VERSION ""

NS_ :

BS_:

BU_: APIM_CISM FCIMB RACM_RCIM DSP WCM DACMC HUD_ADV TRM_ITRM ACM GWM _delete APIM IPC GENERIC TSTR

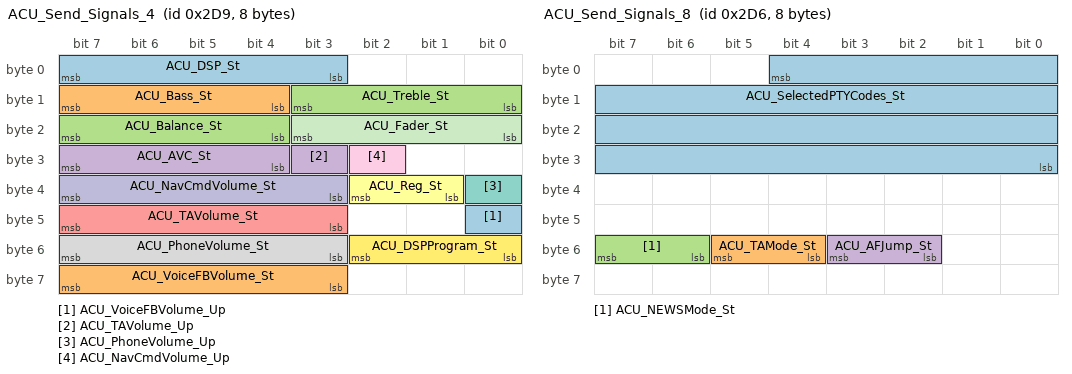
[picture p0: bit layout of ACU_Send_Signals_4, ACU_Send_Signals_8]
BO_ 729 ACU_Send_Signals_4: 8 ACM
 SG_ ACU_VoiceFBVolume_Up : 40|1@0+ (1,0) [0|1] "SED"  HUD_ADV,APIM,IPC
 SG_ ACU_VoiceFBVolume_St : 63|5@0+ (1,0) [0|30] "unitless"  HUD_ADV,WCM,APIM,IPC
 SG_ ACU_Treble_St : 11|4@0+ (1,-7) [-7|8] "unitless"  APIM,IPC
 SG_ ACU_TAVolume_Up : 27|1@0+ (1,0) [0|1] "SED"  HUD_ADV,APIM,IPC
 SG_ ACU_TAVolume_St : 47|5@0+ (1,0) [0|30] "SED"  HUD_ADV,WCM,APIM,IPC
 SG_ ACU_Reg_St : 34|2@0+ (1,0) [0|3] "SED"  APIM
 SG_ ACU_PhoneVolume_Up : 32|1@0+ (1,0) [0|1] "SED"  HUD_ADV,APIM,IPC
 SG_ ACU_PhoneVolume_St : 55|5@0+ (1,0) [0|30] "SED"  HUD_ADV,WCM,APIM,IPC
 SG_ ACU_NavCmdVolume_Up : 26|1@0+ (1,0) [0|1] "SED"  HUD_ADV,APIM,IPC
 SG_ ACU_NavCmdVolume_St : 39|5@0+ (1,0) [0|30] "SED"  HUD_ADV,WCM,APIM,IPC
 SG_ ACU_Fader_St : 19|4@0+ (1,-7) [-7|8] "unitless"  APIM,IPC
 SG_ ACU_DSPProgram_St : 50|3@0+ (1,0) [0|7] "SED"  APIM
 SG_ ACU_DSP_St : 7|5@0+ (1,0) [0|31] "SED"  APIM
 SG_ ACU_Bass_St : 15|4@0+ (1,-7) [-7|8] "unitless"  APIM
 SG_ ACU_Balance_St : 23|4@0+ (1,-7) [-7|8] "unitless"  APIM
 SG_ ACU_AVC_St : 31|4@0+ (1,0) [0|7] "unitless"  APIM

BO_ 727 ACU_Send_Signals_2: 8 ACM
 SG_ ACU_LoadEjectMode_St : 7|4@0+ (1,0) [0|15] "SED"  APIM
 SG_ ACU_LoadEjectDisc_St : 2|3@0+ (1,0) [0|7] "SED"  APIM

BO_ 726 ACU_Send_Signals_8: 8 ACM
 SG_ ACU_SelectedPTYCodes_St : 4|29@0+ (1,0) [0|536870911] "unitless"  APIM
 SG_ ACU_TAMode_St : 53|2@0+ (1,0) [0|3] "SED"  IPC,APIM
 SG_ ACU_NEWSMode_St : 55|2@0+ (1,0) [0|3] "SED"  IPC,APIM
 SG_ ACU_AFJump_St : 51|2@0+ (1,0) [0|3] "SED"  APIM

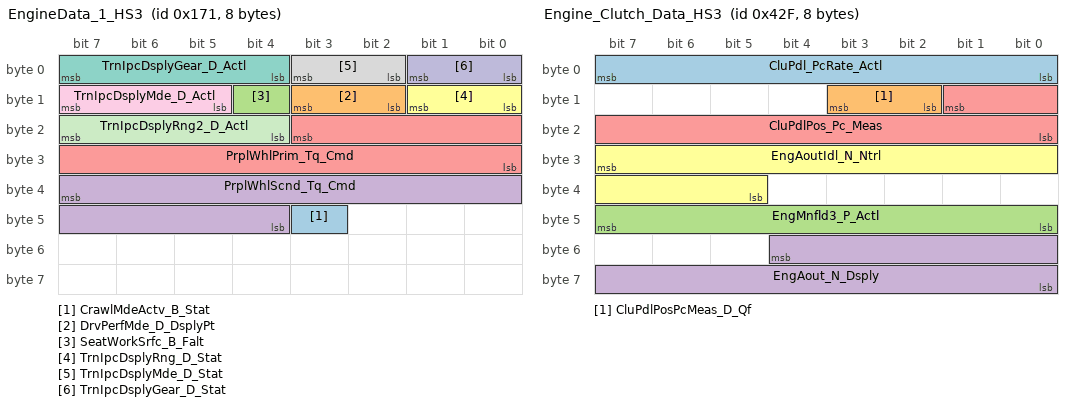
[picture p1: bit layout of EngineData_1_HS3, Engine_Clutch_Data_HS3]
BO_ 369 EngineData_1_HS3: 8 GWM
 SG_ CrawlMdeActv_B_Stat : 43|1@0+ (1,0) [0|1] "SED"  IPC
 SG_ DrvPerfMde_D_DsplyPt : 11|2@0+ (1,0) [0|3] "SED"  APIM_CISM,ACM
 SG_ SeatWorkSrfc_B_Falt : 12|1@0+ (1,0) [0|1] "SED"  IPC
 SG_ PrplWhlScnd_Tq_Cmd : 39|12@0+ (8,-16380) [-16380|16380] "Nm"  GENERIC
 SG_ PrplWhlPrim_Tq_Cmd : 19|12@0+ (8,-16380) [-16380|16380] "Nm"  GENERIC
 SG_ TrnIpcDsplyRng_D_Stat : 9|2@0+ (1,0) [0|3] "SED"  IPC
 SG_ TrnIpcDsplyGear_D_Actl : 7|4@0+ (1,0) [0|15] "SED"  HUD_ADV,APIM_CISM,APIM,IPC
 SG_ TrnIpcDsplyMde_D_Stat : 3|2@0+ (1,0) [0|3] "SED"  HUD_ADV,IPC
 SG_ TrnIpcDsplyMde_D_Actl : 15|3@0+ (1,0) [0|7] "SED"  HUD_ADV,IPC
 SG_ TrnIpcDsplyGear_D_Stat : 1|2@0+ (1,0) [0|3] "SED"  HUD_ADV,IPC
 SG_ TrnIpcDsplyRng2_D_Actl : 23|4@0+ (1,0) [0|15] "SED"  IPC

BO_ 1832 TesterPhysicalResIPC: 8 IPC
 SG_ TesterPhysicalResIPC : 7|64@0+ (1,0) [0|1.84467E+019] "unitless"  TSTR

BO_ 1071 Engine_Clutch_Data_HS3: 8 GWM
 SG_ CluPdl_PcRate_Actl : 7|8@0+ (0.04,-5) [-5|5.2] "%/ms"  IPC
 SG_ CluPdlPosPcMeas_D_Qf : 11|2@0+ (1,0) [0|3] "SED"  IPC
 SG_ EngMnfld3_P_Actl : 47|8@0+ (10,0) [0|2530] "milibar"  GENERIC
 SG_ EngAout_N_Dsply : 52|13@0+ (2,0) [0|16382] "rpm"  IPC
 SG_ CluPdlPos_Pc_Meas : 9|10@0+ (0.1,0) [0|102.3] "%"  IPC
 SG_ EngAoutIdl_N_Ntrl : 31|11@0+ (2,0) [0|4094] "rpm"  GENERIC

BO_ 848 RestraintsData: 8 IPC
 SG_ RILStat : 7|2@0+ (1,0) [0|3] "SED"  GWM

BO_ 891 Active_Noise_Data: 8 DACMC
 SG_ CabnSndAmb2_Db_Actl : 7|8@0+ (1,10) [10|264] "decibel"  GWM

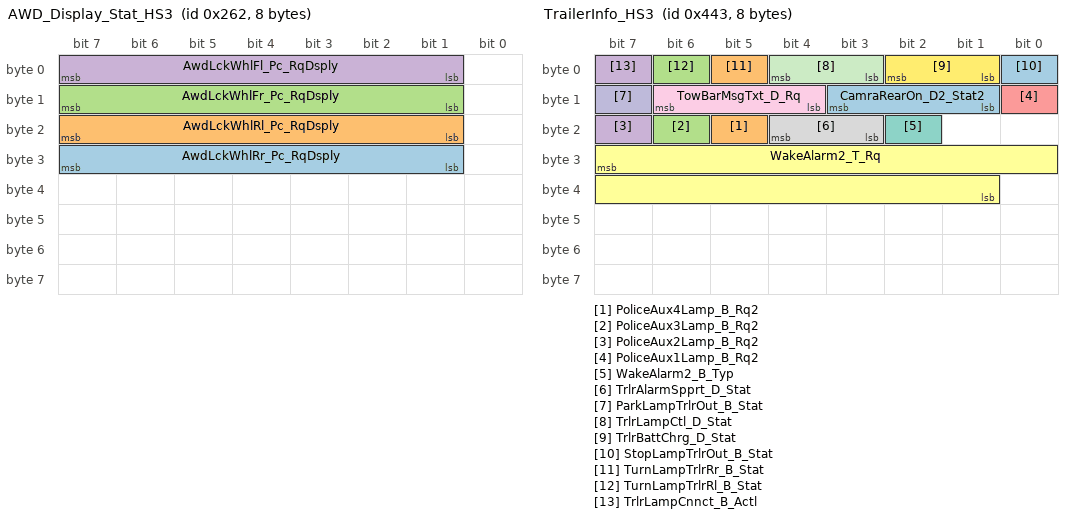
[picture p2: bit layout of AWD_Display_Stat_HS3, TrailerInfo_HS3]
BO_ 610 AWD_Display_Stat_HS3: 8 GWM
 SG_ AwdLckWhlRr_Pc_RqDsply : 31|7@0+ (1,0) [0|127] "percent"  IPC
 SG_ AwdLckWhlRl_Pc_RqDsply : 23|7@0+ (1,0) [0|127] "percent"  IPC
 SG_ AwdLckWhlFr_Pc_RqDsply : 15|7@0+ (1,0) [0|127] "percent"  IPC
 SG_ AwdLckWhlFl_Pc_RqDsply : 7|7@0+ (1,0) [0|127] "percent"  IPC

BO_ 839 FuelOpHeater_Stat_HS3: 8 GWM
 SG_ FohStop_B_Stat : 49|2@0+ (1,0) [0|3] "SED"  IPC
 SG_ FohMsgTxt_D_Rq : 4|3@0+ (1,0) [0|7] "SED"  IPC
 SG_ FohKeyOff_B_Rq : 6|1@0+ (1,0) [0|1] "SED"  IPC
 SG_ FohEnbl_B_Rq : 7|1@0+ (1,0) [0|1] "SED"  IPC
 SG_ FohTAllEnable_B_Stat : 17|2@0+ (1,0) [0|3] "SED"  IPC
 SG_ FohT2Mnte_T_Stat : 55|6@0+ (1,0) [0|63] "minute"  IPC
 SG_ FohT2Hr_T_Stat : 47|5@0+ (1,0) [0|31] "hour"  IPC
 SG_ FohT2Enable_B_Stat : 63|1@0+ (1,0) [0|1] "SED"  IPC
 SG_ FohT1Mnte_T_Stat : 39|6@0+ (1,0) [0|63] "minute"  IPC
 SG_ FohT1Hr_T_Stat : 31|5@0+ (1,0) [0|31] "hour"  IPC
 SG_ FohT1Enable_B_Stat : 0|1@0+ (1,0) [0|1] "SED"  IPC
 SG_ FohStrtMnte_T_Stat : 23|6@0+ (1,0) [0|63] "minute"  IPC
 SG_ FohStrtHr_T_Stat : 15|5@0+ (1,0) [0|31] "hour"  IPC
 SG_ FohStrtEnable_B_Stat : 1|1@0+ (1,0) [0|1] "SED"  IPC
 SG_ FohContOn_B_Stat : 33|2@0+ (1,0) [0|3] "SED"  IPC
 SG_ FohStrtDay_T_Stat : 10|3@0+ (1,0) [0|7] "SED"  IPC
 SG_ FohT2Wednesday_T_Stat : 56|1@0+ (1,0) [0|1] "SED"  IPC
 SG_ FohT2Tuesday_T_Stat : 57|1@0+ (1,0) [0|1] "SED"  IPC
 SG_ FohT2Thursday_T_Stat : 58|1@0+ (1,0) [0|1] "SED"  IPC
 SG_ FohT2Sunday_T_Stat : 59|1@0+ (1,0) [0|1] "SED"  IPC
 SG_ FohT2Saturday_T_Stat : 60|1@0+ (1,0) [0|1] "SED"  IPC
 SG_ FohT2Monday_T_Stat : 61|1@0+ (1,0) [0|1] "SED"  IPC
 SG_ FohT2Friday_T_Stat : 62|1@0+ (1,0) [0|1] "SED"  IPC
 SG_ FohT1Wednesday_T_Stat : 40|1@0+ (1,0) [0|1] "SED"  IPC
 SG_ FohT1Tuesday_T_Stat : 41|1@0+ (1,0) [0|1] "SED"  IPC
 SG_ FohT1Thursday_T_Stat : 42|1@0+ (1,0) [0|1] "SED"  IPC
 SG_ FohT1Sunday_T_Stat : 24|1@0+ (1,0) [0|1] "SED"  IPC
 SG_ FohT1Saturday_T_Stat : 25|1@0+ (1,0) [0|1] "SED"  IPC
 SG_ FohT1Monday_T_Stat : 26|1@0+ (1,0) [0|1] "SED"  IPC
 SG_ FohT1Friday_T_Stat : 5|1@0+ (1,0) [0|1] "SED"  IPC

BO_ 1091 TrailerInfo_HS3: 8 TRM_ITRM
 SG_ CamraRearOn_D2_Stat2 : 11|3@0+ (1,0) [0|7] "SED"  APIM_CISM,GWM,APIM
 SG_ PoliceAux4Lamp_B_Rq2 : 21|1@0+ (1,0) [0|1] "SED"  IPC,GWM
 SG_ PoliceAux3Lamp_B_Rq2 : 22|1@0+ (1,0) [0|1] "SED"  IPC,GWM
 SG_ PoliceAux2Lamp_B_Rq2 : 23|1@0+ (1,0) [0|1] "SED"  IPC,GWM
 SG_ PoliceAux1Lamp_B_Rq2 : 8|1@0+ (1,0) [0|1] "SED"  IPC,GWM
 SG_ WakeAlarm2_T_Rq : 31|15@0+ (1,0) [0|32767] "minute"  GWM
 SG_ WakeAlarm2_B_Typ : 18|1@0+ (1,0) [0|1] "SED"  GWM
 SG_ TrlrAlarmSpprt_D_Stat : 20|2@0+ (1,0) [0|3] "SED"  APIM_CISM,APIM
 SG_ TowBarMsgTxt_D_Rq : 14|3@0+ (1,0) [0|7] "SED"  GWM,IPC
 SG_ ParkLampTrlrOut_B_Stat : 15|1@0+ (1,0) [0|1] "SED"  GWM,IPC
 SG_ TrlrLampCtl_D_Stat : 4|2@0+ (1,0) [0|3] "SED"  GWM,IPC
 SG_ TrlrBattChrg_D_Stat : 2|2@0+ (1,0) [0|3] "SED"  GWM,IPC
 SG_ StopLampTrlrOut_B_Stat : 0|1@0+ (1,0) [0|1] "SED"  GWM,IPC
 SG_ TurnLampTrlrRr_B_Stat : 5|1@0+ (1,0) [0|1] "SED"  GWM,IPC
 SG_ TurnLampTrlrRl_B_Stat : 6|1@0+ (1,0) [0|1] "SED"  GWM,IPC
 SG_ TrlrLampCnnct_B_Actl : 7|1@0+ (1,0) [0|1] "SED"  APIM_CISM,GWM,APIM,IPC

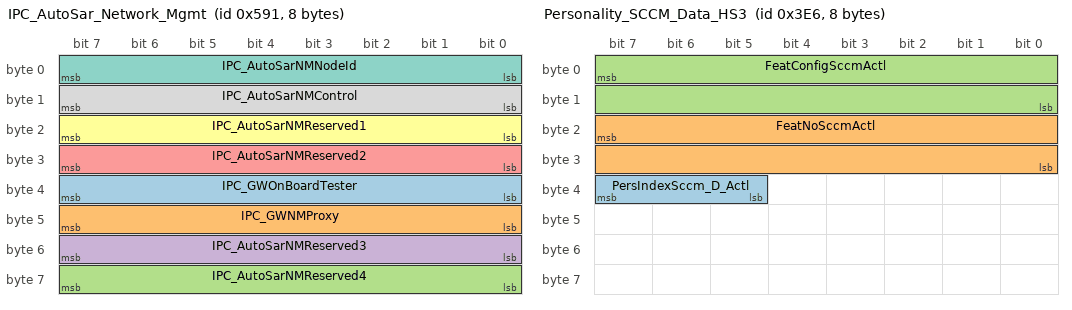
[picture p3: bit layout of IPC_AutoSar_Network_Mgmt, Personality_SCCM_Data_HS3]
BO_ 1425 IPC_AutoSar_Network_Mgmt: 8 IPC
 SG_ IPC_GWOnBoardTester : 39|8@0+ (1,0) [0|255] "unitless"  HUD_ADV,GWM
 SG_ IPC_GWNMProxy : 47|8@0+ (1,0) [0|255] "unitless"  HUD_ADV,GWM
 SG_ IPC_AutoSarNMReserved4 : 63|8@0+ (1,0) [0|255] "unitless"  HUD_ADV,GWM
 SG_ IPC_AutoSarNMReserved3 : 55|8@0+ (1,0) [0|255] "unitless"  HUD_ADV,GWM
 SG_ IPC_AutoSarNMReserved2 : 31|8@0+ (1,0) [0|255] "unitless"  HUD_ADV,GWM
 SG_ IPC_AutoSarNMReserved1 : 23|8@0+ (1,0) [0|255] "unitless"  HUD_ADV,GWM
 SG_ IPC_AutoSarNMNodeId : 7|8@0+ (1,0) [0|255] "unitless"  HUD_ADV,GWM
 SG_ IPC_AutoSarNMControl : 15|8@0+ (1,0) [0|255] "unitless"  HUD_ADV,GWM

BO_ 998 Personality_SCCM_Data_HS3: 8 GWM
 SG_ PersIndexSccm_D_Actl : 39|3@0+ (1,0) [0|7] "SED"  APIM_CISM,APIM,IPC
 SG_ FeatNoSccmActl : 23|16@0+ (1,0) [0|65535] "Number"  APIM_CISM,APIM,IPC
 SG_ FeatConfigSccmActl : 7|16@0+ (1,0) [0|65535] "Undefined"  APIM_CISM,APIM,IPC

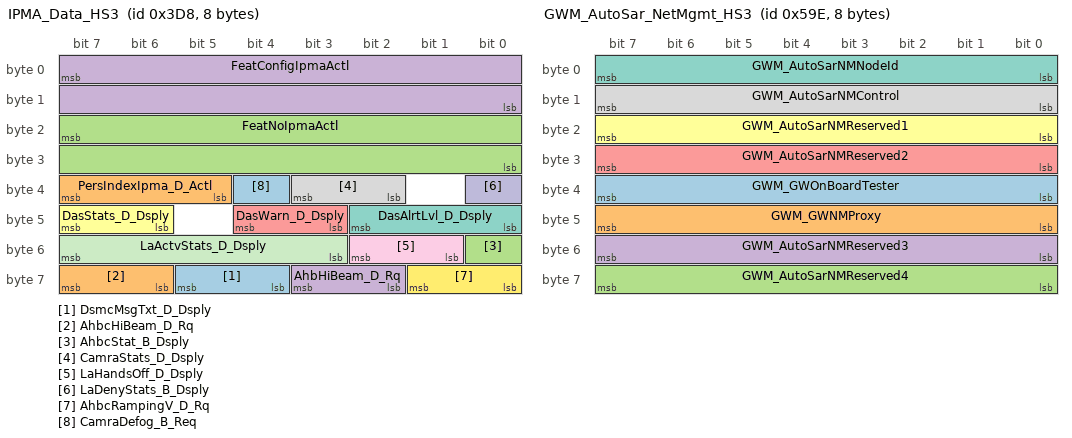
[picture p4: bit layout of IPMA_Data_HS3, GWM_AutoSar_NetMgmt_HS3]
BO_ 984 IPMA_Data_HS3: 8 GWM
 SG_ DsmcMsgTxt_D_Dsply : 61|2@0+ (1,0) [0|3] "SED"  IPC
 SG_ AhbcHiBeam_D_Rq : 63|2@0+ (1,0) [0|3] "SED"  GENERIC
 SG_ AhbcStat_B_Dsply : 48|1@0+ (1,0) [0|1] "SED"  IPC
 SG_ AhbHiBeam_D_Rq : 59|2@0+ (1,0) [0|3] "SED"  GENERIC
 SG_ DasWarn_D_Dsply : 44|2@0+ (1,0) [0|3] "SED"  IPC
 SG_ DasStats_D_Dsply : 47|2@0+ (1,0) [0|3] "SED"  IPC
 SG_ DasAlrtLvl_D_Dsply : 42|3@0+ (1,0) [0|7] "SED"  IPC
 SG_ CamraStats_D_Dsply : 35|2@0+ (1,0) [0|3] "SED"  IPC
 SG_ LaHandsOff_D_Dsply : 50|2@0+ (1,0) [0|3] "SED"  HUD_ADV,IPC
 SG_ LaDenyStats_B_Dsply : 32|1@0+ (1,0) [0|1] "SED"  IPC
 SG_ LaActvStats_D_Dsply : 55|5@0+ (1,0) [0|31] "SED"  APIM_CISM,HUD_ADV,IPC
 SG_ AhbcRampingV_D_Rq : 57|2@0+ (1,0) [0|3] "SED"  GENERIC
 SG_ CamraDefog_B_Req : 36|1@0+ (1,0) [0|1] "SED"  IPC
 SG_ PersIndexIpma_D_Actl : 39|3@0+ (1,0) [0|7] "SED"  APIM_CISM,HUD_ADV,APIM,IPC
 SG_ FeatNoIpmaActl : 23|16@0+ (1,0) [0|65535] "Number"  APIM_CISM,HUD_ADV,APIM,IPC
 SG_ FeatConfigIpmaActl : 7|16@0+ (1,0) [0|65535] "Undefined"  APIM_CISM,HUD_ADV,APIM,IPC

BO_ 1072 Cluster_Info1: 8 IPC
 SG_ PtDrvMde_D_Rq : 61|4@0+ (1,0) [0|15] "SED"  GWM
 SG_ DrvSlipCtlMde_D_Rq : 33|2@0+ (1,0) [0|3] "SED"  GWM
 SG_ EngIdlShutDown_B_RqDrv : 3|1@0+ (1,0) [0|1] "SED"  GWM
 SG_ DrvPerfMde_D_Rq : 49|2@0+ (1,0) [0|3] "SED"  GWM
 SG_ HaDsplyCpblty_B_Stat : 42|1@0+ (1,0) [0|1] "SED"  GWM
 SG_ HsaMde_D_Rq : 54|2@0+ (1,0) [0|3] "SED"  GWM
 SG_ StopStrtDrvMde_D_RqMnu : 47|2@0+ (1,0) [0|3] "SED"  GWM
 SG_ NtrlTowMdeEnbl_B_RqDrv : 1|1@0+ (1,0) [0|1] "SED"  GWM
 SG_ LscmbbStat_B_Actl : 2|1@0+ (1,0) [0|1] "SED"  GWM
 SG_ BulbChkActv_B_Stat : 55|1@0+ (1,0) [0|1] "SED"  GWM
 SG_ ParkDetect_Stat : 52|1@0+ (1,0) [0|1] "SED"  HUD_ADV,GWM
 SG_ ReducedGuard_D_Rq : 51|2@0+ (1,0) [0|3] "SED"  GWM
 SG_ FrostWarn_D_Stat : 45|2@0+ (1,0) [0|3] "SED"  GWM
 SG_ TrlrBrkMde_D_Rq : 57|1@0+ (1,0) [0|1] "SED"  TRM_ITRM,GWM
 SG_ TRLR_SWAY_CONFIG_CMD : 56|1@0+ (1,0) [0|1] "SED"  GWM
 SG_ TRAILER_BRAKE_CONFIG : 37|1@0+ (1,0) [0|1] "SED"  TRM_ITRM,GWM
 SG_ Power_Liftgate_Mode_Cmd : 39|1@0+ (1,0) [0|1] "SED"  GWM
 SG_ AccEnbl_B_RqDrv : 35|1@0+ (1,0) [0|1] "SED"  HUD_ADV,GWM
 SG_ OdometerMasterValue : 15|24@0+ (1,0) [0|16777214] "km"  APIM,APIM_CISM,GWM
 SG_ EngOilLife_B_RqReset : 43|1@0+ (1,0) [0|1] "SED"  GWM
 SG_ MetricActvTe_B_Actl : 38|1@0+ (1,0) [0|1] "SED"  GWM
 SG_ AccDeny_B_RqIpc : 7|1@0+ (1,0) [0|1] "SED"  HUD_ADV,GWM
 SG_ ePRNDL_MODE : 0|1@0+ (1,0) [0|1] "SED"  GWM
 SG_ PrkLckCtlEnbl_D_RqIpc : 63|2@0+ (1,0) [0|3] "SED"  GWM
 SG_ DrvSlipCtlMde_B_Rq2 : 34|1@0+ (1,0) [0|1] "SED"  GWM
 SG_ Fda_B_Stat : 36|1@0+ (1,0) [0|1] "SED"  GWM
 SG_ MetricActv_B_Actl : 6|1@0+ (1,0) [0|1] "SED"  APIM_CISM,HUD_ADV,APIM,GWM
 SG_ KeyTypeChngMykey_D_Rq : 41|2@0+ (1,0) [0|3] "SED"  GWM
 SG_ ManRgen_D_Rq : 5|2@0+ (1,0) [0|3] "SED"  GWM

BO_ 395 HeadUpDisplayReq: 8 IPC
 SG_ SelDrvMdeCnfm_D_Stat : 35|2@0+ (1,0) [0|3] "SED"  GWM
 SG_ HudShifPoint_N_Rq : 29|6@0+ (100,2000) [2000|8300] "rpm"  GWM
 SG_ HudMde_D_Rq : 38|3@0+ (1,0) [0|7] "SED"  GWM
 SG_ HudLedMde_D_Rq : 31|2@0+ (1,0) [0|3] "SED"  GWM
 SG_ HudLedIntns_Pc_Rq : 22|7@0+ (1,0) [0|127] "percent"  GWM
 SG_ HudLed9On_B_Rq : 15|1@0+ (1,0) [0|1] "SED"  GWM
 SG_ HudLed8On_B_Rq : 0|1@0+ (1,0) [0|1] "SED"  GWM
 SG_ HudLed7On_B_Rq : 1|1@0+ (1,0) [0|1] "SED"  GWM
 SG_ HudLed6On_B_Rq : 2|1@0+ (1,0) [0|1] "SED"  GWM
 SG_ HudLed5On_B_Rq : 3|1@0+ (1,0) [0|1] "SED"  GWM
 SG_ HudLed4On_B_Rq : 4|1@0+ (1,0) [0|1] "SED"  GWM
 SG_ HudLed3On_B_Rq : 5|1@0+ (1,0) [0|1] "SED"  GWM
 SG_ HudLed2On_B_Rq : 6|1@0+ (1,0) [0|1] "SED"  GWM
 SG_ HudLed1On_B_Rq : 7|1@0+ (1,0) [0|1] "SED"  GWM
 SG_ HudLed18On_B_Rq : 39|1@0+ (1,0) [0|1] "SED"  GWM
 SG_ HudLed17On_B_Rq : 23|1@0+ (1,0) [0|1] "SED"  GWM
 SG_ HudLed16On_B_Rq : 8|1@0+ (1,0) [0|1] "SED"  GWM
 SG_ HudLed15On_B_Rq : 9|1@0+ (1,0) [0|1] "SED"  GWM
 SG_ HudLed14On_B_Rq : 10|1@0+ (1,0) [0|1] "SED"  GWM
 SG_ HudLed13On_B_Rq : 11|1@0+ (1,0) [0|1] "SED"  GWM
 SG_ HudLed12On_B_Rq : 12|1@0+ (1,0) [0|1] "SED"  GWM
 SG_ HudLed11On_B_Rq : 13|1@0+ (1,0) [0|1] "SED"  GWM
 SG_ HudLed10On_B_Rq : 14|1@0+ (1,0) [0|1] "SED"  GWM

BO_ 1438 GWM_AutoSar_NetMgmt_HS3: 8 GWM
 SG_ GWM_GWOnBoardTester : 39|8@0+ (1,0) [0|255] "unitless"  APIM_CISM,RACM_RCIM,HUD_ADV,TRM_ITRM,WCM,IPC,DSP,APIM,ACM
 SG_ GWM_GWNMProxy : 47|8@0+ (1,0) [0|255] "unitless"  APIM_CISM,RACM_RCIM,HUD_ADV,TRM_ITRM,WCM,IPC,DSP,APIM,ACM
 SG_ GWM_AutoSarNMReserved4 : 63|8@0+ (1,0) [0|255] "unitless"  APIM_CISM,RACM_RCIM,HUD_ADV,TRM_ITRM,WCM,IPC,DSP,APIM,ACM
 SG_ GWM_AutoSarNMReserved3 : 55|8@0+ (1,0) [0|255] "unitless"  APIM_CISM,RACM_RCIM,HUD_ADV,TRM_ITRM,WCM,IPC,DSP,APIM,ACM
 SG_ GWM_AutoSarNMReserved2 : 31|8@0+ (1,0) [0|255] "unitless"  APIM_CISM,RACM_RCIM,HUD_ADV,TRM_ITRM,WCM,IPC,DSP,APIM,ACM
 SG_ GWM_AutoSarNMReserved1 : 23|8@0+ (1,0) [0|255] "unitless"  APIM_CISM,RACM_RCIM,HUD_ADV,TRM_ITRM,WCM,IPC,DSP,APIM,ACM
 SG_ GWM_AutoSarNMNodeId : 7|8@0+ (1,0) [0|255] "unitless"  APIM_CISM,RACM_RCIM,HUD_ADV,TRM_ITRM,WCM,IPC,DSP,APIM,ACM
 SG_ GWM_AutoSarNMControl : 15|8@0+ (1,0) [0|255] "unitless"  APIM_CISM,RACM_RCIM,HUD_ADV,TRM_ITRM,WCM,IPC,DSP,APIM,ACM

BO_ 76 RCMStatusMessage_HS3: 8 GWM
 SG_ RstrnPsngrOn_D_Stat : 39|4@0+ (1,0) [0|15] "SED"  IPC
 SG_ FirstRowBuckle_No_Cs : 47|8@0+ (1,0) [0|255] "unitless"  GENERIC
 SG_ RCMStatusMsg2_No_Cnt : 35|4@0+ (1,0) [0|15] "Unitless"  GENERIC
 SG_ PsngrFmidDetct_D_Actl : 26|2@0+ (1,0) [0|3] "SED"  APIM_CISM,APIM,IPC
 SG_ FirstRowBuckleMid : 28|2@0+ (1,0) [0|3] "SED"  APIM_CISM,APIM,IPC
 SG_ ThirdRowBucklePsngr : 17|2@0+ (1,0) [0|3] "SED"  APIM_CISM,APIM,IPC
 SG_ ThirdRowBuckleMid : 19|2@0+ (1,0) [0|3] "SED"  APIM_CISM,APIM,IPC
 SG_ ThirdRowBuckleDriver : 21|2@0+ (1,0) [0|3] "SED"  APIM_CISM,APIM,IPC
 SG_ SecondRowBucklePsngr : 23|2@0+ (1,0) [0|3] "SED"  APIM_CISM,APIM,IPC
 SG_ SecondRowBuckleMid : 9|2@0+ (1,0) [0|3] "SED"  APIM_CISM,APIM,IPC
 SG_ SecondRowBuckleDriver : 11|2@0+ (1,0) [0|3] "SED"  APIM_CISM,APIM,IPC
 SG_ FirstRowBuckleDriver : 15|2@0+ (1,0) [0|3] "SED"  APIM_CISM,APIM,IPC
 SG_ RILReq : 7|2@0+ (1,0) [0|3] "SED"  IPC
 SG_ FirstRowBucklePsngr : 13|2@0+ (1,0) [0|3] "SED"  APIM_CISM,APIM,IPC
 SG_ RstrnImpactEvntStatus : 3|3@0+ (1,0) [0|7] "SED"  APIM_CISM,APIM,HUD_ADV
 SG_ PsngrFrntDetct_D_Actl : 5|2@0+ (1,0) [0|3] "SED"  APIM_CISM,APIM,IPC
 SG_ PassRstrnInd_Req : 31|2@0+ (1,0) [0|3] "SED"  FCIMB
 SG_ EDRTriggerEvntSync : 29|1@0+ (1,0) [0|1] "SED"  APIM,APIM_CISM,IPC

BO_ 1034 GGCC_Config_Mgmt_ID_1_HS3: 8 GWM
 SG_ VehicleGGCCData : 7|64@0+ (1,0) [0|1.84467E+019] "mixed"  HUD_ADV,APIM_CISM,TRM_ITRM,APIM,ACM,IPC

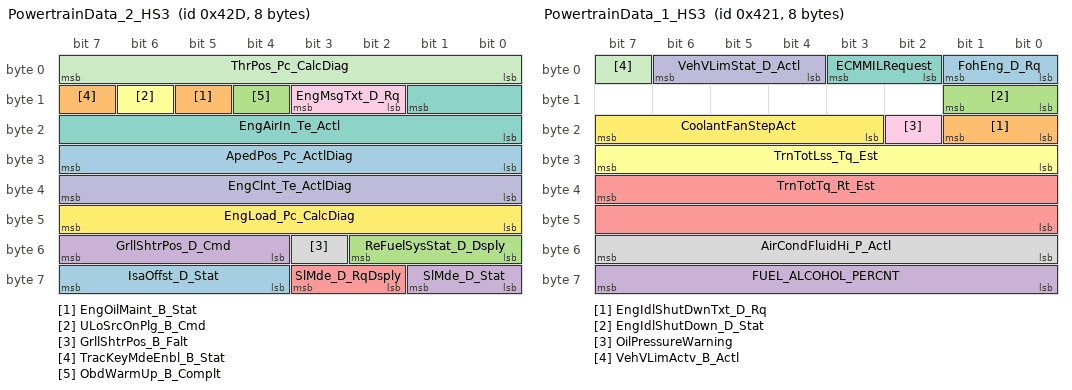
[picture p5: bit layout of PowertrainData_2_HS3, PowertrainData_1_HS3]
BO_ 1069 PowertrainData_2_HS3: 8 GWM
 SG_ IsaOffst_D_Stat : 63|4@0+ (1,0) [0|15] "SED"  HUD_ADV,IPC
 SG_ EngOilMaint_B_Stat : 13|1@0+ (1,0) [0|1] "SED"  GENERIC
 SG_ ReFuelSysStat_D_Dsply : 50|3@0+ (1,0) [0|7] "SED"  IPC
 SG_ SlMde_D_Stat : 57|2@0+ (1,0) [0|3] "SED"  HUD_ADV,IPC
 SG_ SlMde_D_RqDsply : 59|2@0+ (1,0) [0|3] "SED"  APIM_CISM,HUD_ADV,APIM,IPC
 SG_ ULoSrcOnPlg_B_Cmd : 14|1@0+ (1,0) [0|1] "SED"  IPC
 SG_ EngAirIn_Te_Actl : 9|10@0+ (0.25,-128) [-128|127.25] "degC"  IPC
 SG_ GrllShtrPos_B_Falt : 51|1@0+ (1,0) [0|1] "SED"  IPC
 SG_ EngMsgTxt_D_Rq : 11|2@0+ (1,0) [0|3] "SED"  IPC
 SG_ EngClnt_Te_ActlDiag : 39|8@0+ (1,-40) [-40|215] "degC"  IPC
 SG_ ThrPos_Pc_CalcDiag : 7|8@0+ (0.392157,0) [0|100.000035] "%"  IPC
 SG_ EngLoad_Pc_CalcDiag : 47|8@0+ (0.392157,0) [0|100.000035] "%"  IPC
 SG_ ApedPos_Pc_ActlDiag : 31|8@0+ (0.392157,0) [0|100.000035] "%"  IPC
 SG_ TracKeyMdeEnbl_B_Stat : 15|1@0+ (1,0) [0|1] "SED"  IPC
 SG_ ObdWarmUp_B_Complt : 12|1@0+ (1,0) [0|1] "SED" Vector__XXX
 SG_ GrllShtrPos_D_Cmd : 55|4@0+ (1,0) [0|15] "SED"  IPC

BO_ 1057 PowertrainData_1_HS3: 8 GWM
 SG_ FohEng_D_Rq : 1|2@0+ (1,0) [0|3] "SED"  IPC
 SG_ EngIdlShutDwnTxt_D_Rq : 17|2@0+ (1,0) [0|3] "SED"  IPC
 SG_ EngIdlShutDown_D_Stat : 9|2@0+ (1,0) [0|3] "SED"  IPC
 SG_ FUEL_ALCOHOL_PERCNT : 63|8@0+ (0.393700787,0) [0|99.999899898] "Percent"  IPC
 SG_ TrnTotTq_Rt_Est : 39|16@0+ (0.001,0) [0|65.533] "Unitless"  IPC
 SG_ TrnTotLss_Tq_Est : 31|8@0+ (0.5,0) [0|126.5] "Nm"  IPC
 SG_ ECMMILRequest : 3|2@0+ (1,0) [0|3] "SED"  IPC
 SG_ AirCondFluidHi_P_Actl : 55|8@0+ (0.125,0) [0|31.625] "bar"  IPC
 SG_ OilPressureWarning : 18|1@0+ (1,0) [0|1] "SED"  IPC
 SG_ VehVLimStat_D_Actl : 6|3@0+ (1,0) [0|7] "SED"  IPC
 SG_ VehVLimActv_B_Actl : 7|1@0+ (1,0) [0|1] "SED"  IPC
 SG_ CoolantFanStepAct : 23|5@0+ (1,0) [0|31] "Steps"  IPC

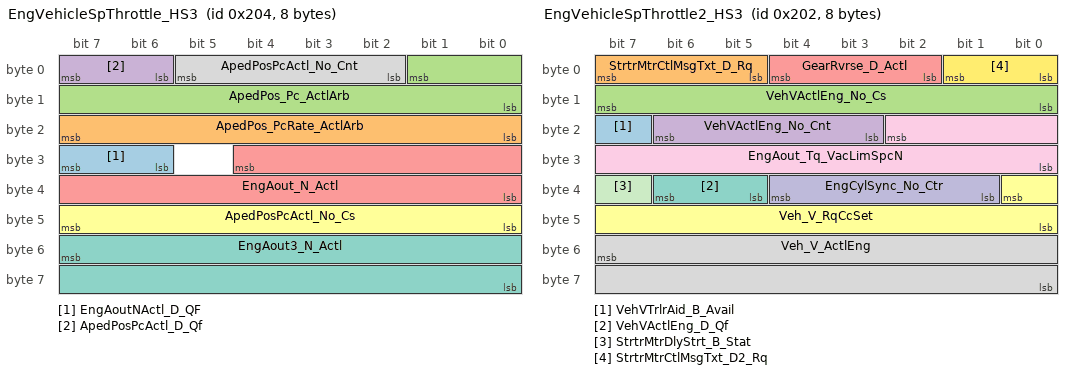
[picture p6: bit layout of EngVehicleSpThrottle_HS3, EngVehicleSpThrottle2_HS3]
BO_ 516 EngVehicleSpThrottle_HS3: 8 GWM
 SG_ EngAoutNActl_D_QF : 31|2@0+ (1,0) [0|3] "SED"  GENERIC
 SG_ ApedPos_PcRate_ActlArb : 23|8@0+ (0.04,-5) [-5|5.12] "%/ms"  APIM_CISM,ACM
 SG_ ApedPos_Pc_ActlArb : 1|10@0+ (0.1,0) [0|102.3] "%"  APIM,APIM_CISM,DACMC,ACM
 SG_ ApedPosPcActl_D_Qf : 7|2@0+ (1,0) [0|3] "SED"  APIM_CISM,DACMC,ACM
 SG_ EngAout_N_Actl : 28|13@0+ (2,0) [0|16382] "rpm"  HUD_ADV,APIM,APIM_CISM,ACM,DACMC,DSP,IPC
 SG_ ApedPosPcActl_No_Cs : 47|8@0+ (1,0) [0|255] "Unitless"  GENERIC
 SG_ EngAout3_N_Actl : 55|16@0+ (0.25,0) [0|16383.5] "RPM"  GENERIC
 SG_ ApedPosPcActl_No_Cnt : 5|4@0+ (1,0) [0|15] "Unitless"  GENERIC

BO_ 514 EngVehicleSpThrottle2_HS3: 8 GWM
 SG_ VehVTrlrAid_B_Avail : 23|1@0+ (1,0) [0|1] "SED"  GENERIC
 SG_ StrtrMtrCtlMsgTxt_D_Rq : 7|3@0+ (1,0) [0|7] "SED"  IPC
 SG_ VehVActlEng_No_Cs : 15|8@0+ (1,0) [0|255] "Unitless"  GENERIC
 SG_ VehVActlEng_No_Cnt : 22|4@0+ (1,0) [0|15] "Unitless"  GENERIC
 SG_ GearRvrse_D_Actl : 4|3@0+ (1,0) [0|7] "SED"  HUD_ADV,APIM_CISM,APIM,IPC
 SG_ Veh_V_RqCcSet : 32|9@0+ (0.5,0) [0|255.5] "kph"  IPC
 SG_ VehVActlEng_D_Qf : 38|2@0+ (1,0) [0|3] "SED"  WCM,APIM,APIM_CISM,DSP,ACM,IPC
 SG_ Veh_V_ActlEng : 55|16@0+ (0.01,0) [0|655.35] "kph"  WCM,APIM,APIM_CISM,TRM_ITRM,DSP,ACM,IPC
 SG_ EngAout_Tq_VacLimSpcN : 18|11@0+ (1,-500) [-500|1547] "Nm"  GENERIC
 SG_ EngCylSync_No_Ctr : 36|4@0+ (1,0) [0|15] "unitless"  GENERIC
 SG_ StrtrMtrDlyStrt_B_Stat : 39|1@0+ (1,0) [0|1] "SED"  GENERIC
 SG_ StrtrMtrCtlMsgTxt_D2_Rq : 1|2@0+ (1,0) [0|3] "SED"  IPC

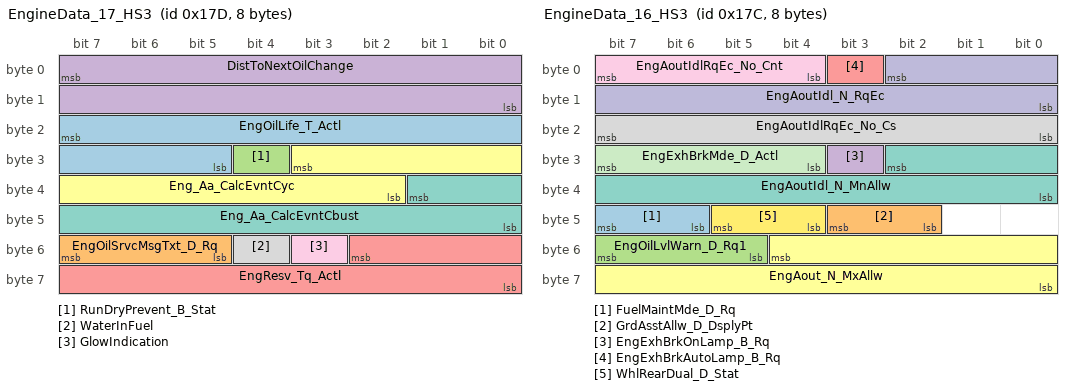
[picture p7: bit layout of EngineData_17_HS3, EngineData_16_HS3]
BO_ 381 EngineData_17_HS3: 8 GWM
 SG_ EngOilLife_T_Actl : 23|11@0+ (1,0) [0|2047] "days"  IPC
 SG_ EngOilSrvcMsgTxt_D_Rq : 55|3@0+ (1,0) [0|7] "SED"  IPC
 SG_ RunDryPrevent_B_Stat : 28|1@0+ (1,0) [0|1] "SED"  IPC
 SG_ DistToNextOilChange : 7|16@0+ (1,0) [0|65535] "unitless"  IPC
 SG_ EngResv_Tq_Actl : 50|11@0+ (1,-500) [-500|1547] "Nm"  IPC
 SG_ Eng_Aa_CalcEvntCyc : 27|10@0+ (0.05,-25.6) [-25.6|25.55] "rpm/ms"  IPC
 SG_ Eng_Aa_CalcEvntCbust : 33|10@0+ (0.05,-25.6) [-25.6|25.55] "rpm/ms"  IPC
 SG_ WaterInFuel : 52|1@0+ (1,0) [0|1] "SED"  IPC
 SG_ GlowIndication : 51|1@0+ (1,0) [0|1] "SED"  IPC

BO_ 380 EngineData_16_HS3: 8 GWM
 SG_ FuelMaintMde_D_Rq : 47|2@0+ (1,0) [0|3] "SED"  GENERIC
 SG_ GrdAsstAllw_D_DsplyPt : 43|2@0+ (1,0) [0|3] "SED"  IPC
 SG_ EngOilLvlWarn_D_Rq1 : 55|3@0+ (1,0) [0|7] "SED"  IPC
 SG_ EngExhBrkOnLamp_B_Rq : 27|1@0+ (1,0) [0|1] "SED"  IPC
 SG_ EngExhBrkAutoLamp_B_Rq : 3|1@0+ (1,0) [0|1] "SED"  IPC
 SG_ EngAout_N_MxAllw : 52|13@0+ (2,0) [0|16382] "rpm"  IPC
 SG_ EngAoutIdl_N_MnAllw : 26|11@0+ (2,0) [0|4094] "rpm"  IPC
 SG_ EngAoutIdlRqEc_No_Cs : 23|8@0+ (1,0) [0|255] "Unitless"  GENERIC
 SG_ EngAoutIdlRqEc_No_Cnt : 7|4@0+ (1,0) [0|15] "Unitless"  GENERIC
 SG_ EngAoutIdl_N_RqEc : 2|11@0+ (2,0) [0|4094] "rpm"  IPC
 SG_ EngExhBrkMde_D_Actl : 31|4@0+ (1,0) [0|15] "SED"  IPC
 SG_ WhlRearDual_D_Stat : 45|2@0+ (1,0) [0|3] "SED"  GENERIC

BO_ 377 EngineData_7_HS3: 8 GWM
 SG_ TrnManShif_D_IndDrv : 7|3@0+ (1,0) [0|7] "Unitless"  HUD_ADV,IPC
 SG_ HvacAirFullOut_B_Rq : 23|1@0+ (1,0) [0|1] "SED"  GENERIC
 SG_ EngFuelCutFull_B_Inhbt : 22|1@0+ (1,0) [0|1] "SED"  IPC
 SG_ EngDecelFuelCut_B_Allw : 21|1@0+ (1,0) [0|1] "SED"  IPC
 SG_ EngAout_Tq_Actl : 2|11@0+ (1,-500) [-500|1547] "Nm"  APIM_CISM,APIM,ACM
 SG_ TrnManShifGear_D_IndDrv : 54|3@0+ (1,0) [0|7] "SED"  HUD_ADV,IPC
 SG_ FuelFlw_Vl_Dsply : 49|10@0+ (25,0) [0|25575] "Micro_Liter"  APIM,APIM_CISM,IPC
 SG_ FuelFillInlet_B_Dsply : 32|1@0+ (1,0) [0|1] "SED"  IPC
 SG_ EngSrvcRqd_B_Rq : 19|1@0+ (1,0) [0|1] "SED"  IPC
 SG_ OdoCount : 47|8@0+ (0.2,0) [0|50.8] "Meters"  APIM_CISM,APIM,IPC
 SG_ EngOilLife_Pc_Actl : 39|7@0+ (1,0) [0|100] "Percent"  APIM,APIM_CISM,IPC
 SG_ EngTqSlwDly_T_Est : 18|11@0+ (1,0) [0|2047] "ms"  IPC
 SG_ TrnKickDown_B_RqDrv : 20|1@0+ (1,0) [0|1] "SED"  IPC
 SG_ FuelFilterLamp_B_Dsply : 50|1@0+ (1,0) [0|1] "SED"  IPC
 SG_ AirCondRec_B_Rq : 55|1@0+ (1,0) [0|1] "SED"  IPC
 SG_ AirCondClutch_B_Stats : 51|1@0+ (1,0) [0|1] "SED"  WCM,IPC
 SG_ EngAoutTqActl_D_Qf : 4|2@0+ (1,0) [0|3] "SED"  APIM_CISM

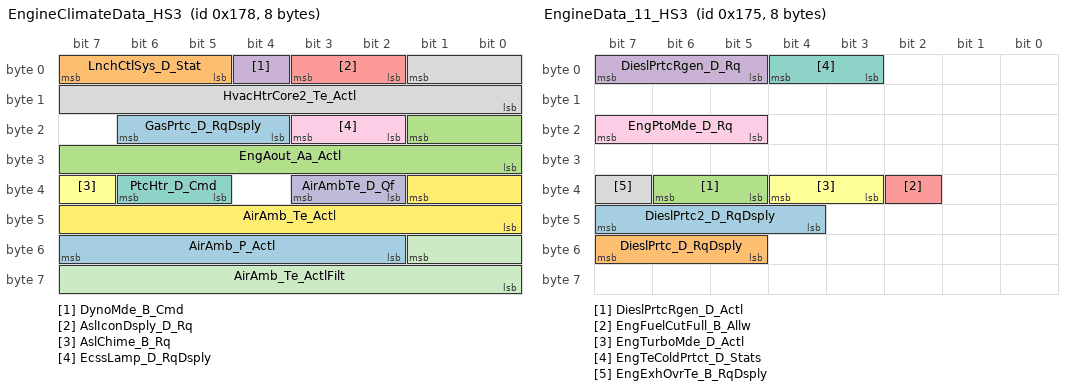
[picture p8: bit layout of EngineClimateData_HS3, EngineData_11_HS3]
BO_ 376 EngineClimateData_HS3: 8 GWM
 SG_ GasPrtc_D_RqDsply : 22|3@0+ (1,0) [0|7] "SED"  IPC
 SG_ LnchCtlSys_D_Stat : 7|3@0+ (1,0) [0|7] "SED"  IPC
 SG_ EngAout_Aa_Actl : 17|10@0+ (0.05,-25.6) [-25.6|25.55] "rpm/ms"  GENERIC
 SG_ DynoMde_B_Cmd : 4|1@0+ (1,0) [0|1] "SED"  GENERIC
 SG_ AslIconDsply_D_Rq : 3|2@0+ (1,0) [0|3] "SED"  HUD_ADV,APIM_CISM,APIM,IPC
 SG_ AslChime_B_Rq : 39|1@0+ (1,0) [0|1] "SED"  HUD_ADV,IPC
 SG_ PtcHtr_D_Cmd : 38|2@0+ (1,0) [0|3] "SED"  GENERIC
 SG_ HvacHtrCore2_Te_Actl : 1|10@0+ (0.25,-50) [-50|205.5] "degC"  IPC
 SG_ EcssLamp_D_RqDsply : 19|2@0+ (1,0) [0|3] "SED"  IPC
 SG_ AirAmbTe_D_Qf : 35|2@0+ (1,0) [0|3] "SED"  IPC
 SG_ AirAmb_Te_ActlFilt : 49|10@0+ (0.25,-128) [-128|127.75] "deg C"  IPC
 SG_ AirAmb_Te_Actl : 33|10@0+ (0.25,-128) [-128|127.75] "degC"  IPC
 SG_ AirAmb_P_Actl : 55|6@0+ (10,500) [500|1110] "mbar"  IPC

BO_ 373 EngineData_11_HS3: 8 GWM
 SG_ DieslPrtc2_D_RqDsply : 47|4@0+ (1,0) [0|15] "SED"  IPC
 SG_ DieslPrtc_D_RqDsply : 55|3@0+ (1,0) [0|7] "SED"  IPC
 SG_ DieslPrtcRgen_D_Actl : 38|2@0+ (1,0) [0|3] "SED"  IPC
 SG_ DieslPrtcRgen_D_Rq : 7|3@0+ (1,0) [0|7] "SED"  IPC
 SG_ EngFuelCutFull_B_Allw : 34|1@0+ (1,0) [0|1] "SED"  GENERIC
 SG_ EngTurboMde_D_Actl : 36|2@0+ (1,0) [0|3] "SED"  IPC
 SG_ EngTeColdPrtct_D_Stats : 4|2@0+ (1,0) [0|3] "SED"  IPC
 SG_ EngExhOvrTe_B_RqDsply : 39|1@0+ (1,0) [0|1] "SED"  IPC
 SG_ EngPtoMde_D_Rq : 23|3@0+ (1,0) [0|7] "SED"  IPC

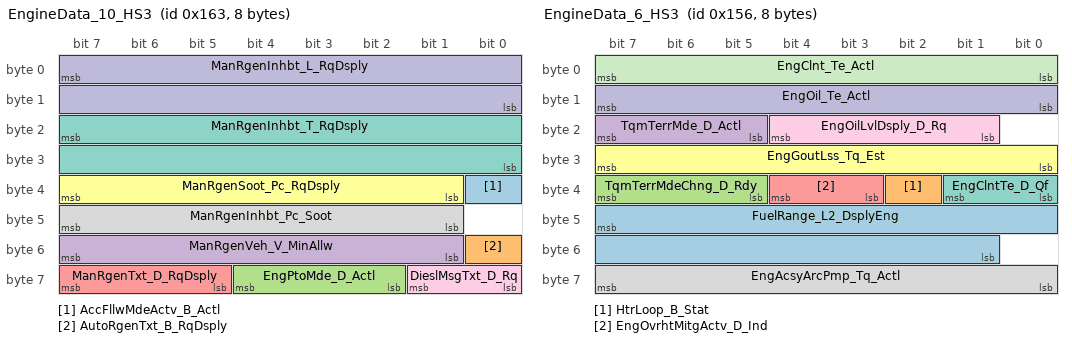
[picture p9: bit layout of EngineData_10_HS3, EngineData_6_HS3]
BO_ 355 EngineData_10_HS3: 8 GWM
 SG_ AccFllwMdeActv_B_Actl : 32|1@0+ (1,0) [0|1] "SED"  GENERIC
 SG_ AutoRgenTxt_B_RqDsply : 48|1@0+ (1,0) [0|1] "SED"  IPC
 SG_ EngPtoMde_D_Actl : 60|3@0+ (1,0) [0|7] "SED"  IPC
 SG_ ManRgenVeh_V_MinAllw : 55|7@0+ (1,0) [0|126] "kilometer/hour"  IPC
 SG_ ManRgenTxt_D_RqDsply : 63|3@0+ (1,0) [0|7] "SED"  IPC
 SG_ ManRgenSoot_Pc_RqDsply : 39|7@0+ (1,0) [0|126] "%"  IPC
 SG_ ManRgenInhbt_T_RqDsply : 23|16@0+ (1,0) [0|65534] "Minutes"  IPC
 SG_ ManRgenInhbt_Pc_Soot : 47|7@0+ (1,0) [0|126] "%"  IPC
 SG_ DieslMsgTxt_D_Rq : 57|2@0+ (1,0) [0|3] "SED"  IPC
 SG_ ManRgenInhbt_L_RqDsply : 7|16@0+ (1,0) [0|65534] "kilometer"  IPC

BO_ 342 EngineData_6_HS3: 8 GWM
 SG_ FuelRange_L2_DsplyEng : 47|15@0+ (0.1,0) [0|3276.7] "kilometer"  IPC
 SG_ HtrLoop_B_Stat : 34|1@0+ (1,0) [0|1] "SED"  IPC
 SG_ TqmTerrMdeChng_D_Rdy : 39|3@0+ (1,0) [0|7] "SED"  IPC
 SG_ TqmTerrMde_D_Actl : 23|3@0+ (1,0) [0|7] "SED"  IPC
 SG_ EngOvrhtMitgActv_D_Ind : 36|2@0+ (1,0) [0|3] "SED"  IPC
 SG_ EngGoutLss_Tq_Est : 31|8@0+ (1,0) [0|255] "Nm"  IPC
 SG_ EngClntTe_D_Qf : 33|2@0+ (1,0) [0|3] "SED"  IPC
 SG_ EngAcsyArcPmp_Tq_Actl : 63|8@0+ (0.5,0) [0|126.5] "Nm"  IPC
 SG_ EngOilLvlDsply_D_Rq : 20|4@0+ (1,0) [0|15] "SED"  IPC
 SG_ EngOil_Te_Actl : 15|8@0+ (1,-60) [-60|193] "degC"  APIM_CISM,APIM,IPC
 SG_ EngClnt_Te_Actl : 7|8@0+ (1,-60) [-60|195] "degC"  APIM_CISM,APIM,IPC

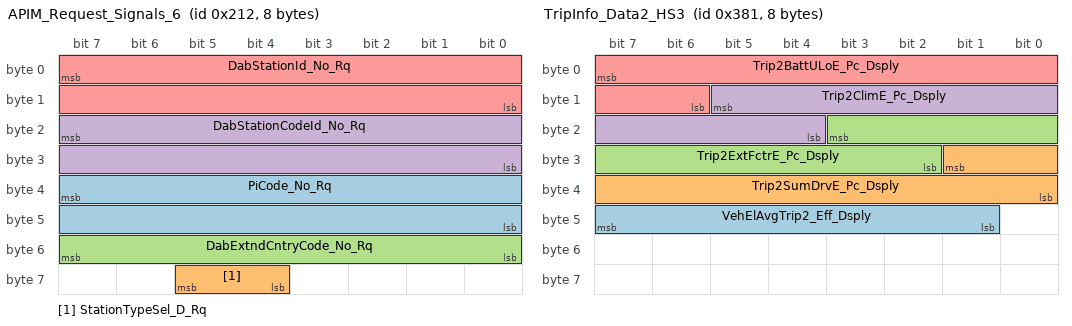
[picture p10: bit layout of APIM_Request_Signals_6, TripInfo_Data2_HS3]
BO_ 530 APIM_Request_Signals_6: 8 APIM
 SG_ PiCode_No_Rq : 39|16@0+ (1,0) [0|65535] "unitless"  APIM_CISM,ACM
 SG_ StationTypeSel_D_Rq : 61|2@0+ (1,0) [0|3] "SED"  APIM_CISM,ACM
 SG_ DabExtndCntryCode_No_Rq : 55|8@0+ (1,0) [0|255] "unitless"  APIM_CISM,ACM
 SG_ DabStationCodeId_No_Rq : 23|16@0+ (1,0) [0|65535] "unitless"  APIM_CISM,ACM
 SG_ DabStationId_No_Rq : 7|16@0+ (1,0) [0|65535] "unitless"  APIM_CISM,ACM

BO_ 897 TripInfo_Data2_HS3: 8 GWM
 SG_ VehElAvgTrip2_Eff_Dsply : 47|7@0+ (10,-100) [-100|1150] "wattHr/km"  APIM_CISM,APIM
 SG_ Trip2SumDrvE_Pc_Dsply : 25|10@0+ (0.1,0) [0|102.1] "percent"  APIM_CISM,APIM
 SG_ Trip2ExtFctrE_Pc_Dsply : 19|10@0+ (0.1,0) [0|102.1] "percent"  APIM_CISM,APIM
 SG_ Trip2ClimE_Pc_Dsply : 13|10@0+ (0.1,0) [0|102.1] "percent"  APIM_CISM,APIM
 SG_ Trip2BattULoE_Pc_Dsply : 7|10@0+ (0.1,0) [0|102.1] "percent"  APIM_CISM,APIM

BO_ 707 SSPClnt_SSPSrv_WORD_Tx: 8 ACM
 SG_ SSPClnt_SSPSrv_WORD_Tx : 7|64@0+ (1,0) [0|1.84467440737096E+019] "unitless"  APIM_CISM,APIM

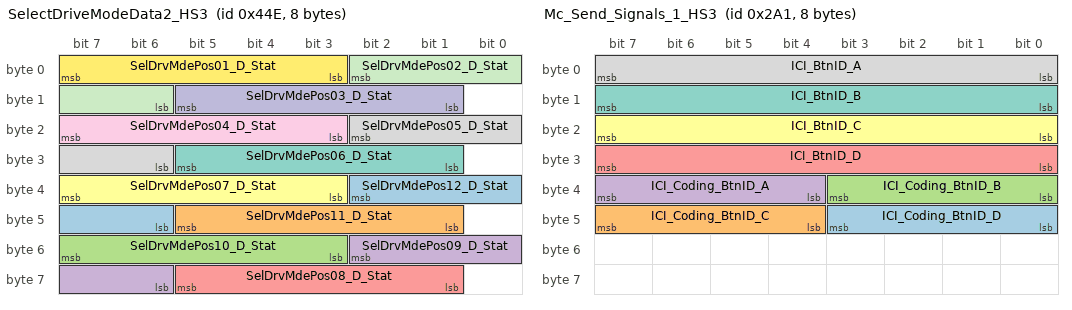
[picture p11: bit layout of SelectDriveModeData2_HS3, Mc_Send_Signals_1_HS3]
BO_ 1102 SelectDriveModeData2_HS3: 8 GWM
 SG_ SelDrvMdePos12_D_Stat : 34|5@0+ (1,0) [0|31] "SED"  APIM_CISM,APIM,IPC
 SG_ SelDrvMdePos11_D_Stat : 45|5@0+ (1,0) [0|31] "SED"  APIM_CISM,APIM,IPC
 SG_ SelDrvMdePos10_D_Stat : 55|5@0+ (1,0) [0|31] "SED"  APIM_CISM,APIM,IPC
 SG_ SelDrvMdePos09_D_Stat : 50|5@0+ (1,0) [0|31] "SED"  APIM_CISM,APIM,IPC
 SG_ SelDrvMdePos08_D_Stat : 61|5@0+ (1,0) [0|31] "SED"  APIM_CISM,APIM,IPC
 SG_ SelDrvMdePos07_D_Stat : 39|5@0+ (1,0) [0|31] "SED"  APIM_CISM,APIM,IPC
 SG_ SelDrvMdePos06_D_Stat : 29|5@0+ (1,0) [0|31] "SED"  APIM_CISM,APIM,IPC
 SG_ SelDrvMdePos05_D_Stat : 18|5@0+ (1,0) [0|31] "SED"  APIM_CISM,APIM,IPC
 SG_ SelDrvMdePos04_D_Stat : 23|5@0+ (1,0) [0|31] "SED"  APIM_CISM,APIM,IPC
 SG_ SelDrvMdePos03_D_Stat : 13|5@0+ (1,0) [0|31] "SED"  APIM_CISM,APIM,IPC
 SG_ SelDrvMdePos02_D_Stat : 2|5@0+ (1,0) [0|31] "SED"  APIM_CISM,APIM,IPC
 SG_ SelDrvMdePos01_D_Stat : 7|5@0+ (1,0) [0|31] "SED"  APIM_CISM,APIM,IPC

BO_ 551 APIM_Request_Signals_1: 8 APIM
 SG_ Rba_D_Rq : 31|2@0+ (1,0) [0|3] "SED"  GWM
 SG_ PrcondEdit_D_RqMnu : 15|3@0+ (1,0) [0|7] "SED"  GWM
 SG_ ChrgToPcEdit_Pc_RqMnu : 23|7@0+ (1,0) [0|125] "percent"  GWM
 SG_ EcoIdl_D_Rq : 7|2@0+ (1,0) [0|3] "SED"  GWM
 SG_ PwRnngBoardT_D_Rq : 25|2@0+ (1,0) [0|3] "SED"  GWM
 SG_ PwRnngBoardSwtch_D_Rq : 27|2@0+ (1,0) [0|3] "SED"  GWM
 SG_ PwRnngBoardMde_D_Rq : 29|2@0+ (1,0) [0|3] "SED"  GWM
 SG_ GoTElementEdit_No_RqMnu : 12|4@0+ (1,0) [0|15] "unitless"  GWM
 SG_ OneTEditActv_B_RqMnu : 40|1@0+ (1,0) [0|1] "SED"  GWM
 SG_ Cntr_Plg_Mode_Cmd : 39|1@0+ (1,0) [0|1] "SED"  GWM
 SG_ BattTracLoThres_D_Rq : 43|3@0+ (1,0) [0|7] "SED"  GWM
 SG_ EmPrflNo_D_Rq : 61|3@0+ (1,0) [0|7] "SED"  GWM
 SG_ EmPrflButtnAssoc_D_Rq : 33|2@0+ (1,0) [0|3] "SED"  GWM
 SG_ EmPrflKeyAssoc_D_Rq : 46|3@0+ (1,0) [0|7] "SED"  GWM
 SG_ Em_D_Stat : 63|2@0+ (1,0) [0|3] "SED"  GWM
 SG_ PmCabnLvl_D_Stat : 36|3@0+ (1,0) [0|7] "SED"  GWM,RACM_RCIM
 SG_ PmCabn_D_Stat : 38|2@0+ (1,0) [0|3] "SED"  GWM,RACM_RCIM
 SG_ ChrgCrdLckEnbl_B_Stat : 47|1@0+ (1,0) [0|1] "SED"  GWM
 SG_ ChrgOvrdExitScrn_D_Rq : 58|2@0+ (1,0) [0|3] "SED"  GWM
 SG_ Btt_L_Actl2 : 55|7@0+ (0.1,0) [0|12.5] "meter"  GWM

BO_ 673 Mc_Send_Signals_1_HS3: 8 GWM
 SG_ ICI_Coding_BtnID_D : 43|4@0+ (1,0) [0|15] "SED"  APIM_CISM,HUD_ADV,ACM,APIM,IPC
 SG_ ICI_Coding_BtnID_C : 47|4@0+ (1,0) [0|15] "SED"  APIM_CISM,HUD_ADV,ACM,APIM,IPC
 SG_ ICI_Coding_BtnID_B : 35|4@0+ (1,0) [0|15] "SED"  APIM_CISM,HUD_ADV,ACM,APIM,IPC
 SG_ ICI_Coding_BtnID_A : 39|4@0+ (1,0) [0|15] "SED"  APIM_CISM,HUD_ADV,ACM,APIM,IPC
 SG_ ICI_BtnID_D : 31|8@0+ (1,0) [0|255] "unitless"  APIM_CISM,HUD_ADV,ACM,APIM,IPC
 SG_ ICI_BtnID_C : 23|8@0+ (1,0) [0|255] "unitless"  APIM_CISM,HUD_ADV,ACM,APIM,IPC
 SG_ ICI_BtnID_B : 15|8@0+ (1,0) [0|255] "unitless"  APIM_CISM,HUD_ADV,ACM,APIM,IPC
 SG_ ICI_BtnID_A : 7|8@0+ (1,0) [0|255] "unitless"  APIM_CISM,HUD_ADV,APIM,ACM,IPC

BO_ 963 BCM_Lamp_Stat_HS3: 8 GWM
 SG_ Illuminated_Entry_Stat : 63|2@0+ (1,0) [0|3] "SED"  GENERIC
 SG_ Dr_Courtesy_Light_Stat : 49|2@0+ (1,0) [0|3] "SED"  GENERIC
 SG_ Courtesy_Delay_Status : 51|2@0+ (1,0) [0|3] "SED"  GENERIC
 SG_ ImpactEvntFdbck_D_Stat : 53|2@0+ (1,0) [0|3] "SED"  GENERIC
 SG_ WrlssAcsyChrgInhbt_B_Rq : 40|1@0+ (1,0) [0|1] "SED"  WCM
 SG_ PudLampPsngr_D_Rq : 57|2@0+ (1,0) [0|3] "SED" Vector__XXX
 SG_ HeadLampLoOut_B_Stat : 32|1@0+ (1,0) [0|1] "SED"  IPC
 SG_ CrnrLghtRight_Pc_Rq : 47|7@0+ (1,0) [0|100] "percent"  GENERIC
 SG_ CrnrLghtLeft_Pc_Rq : 39|7@0+ (1,0) [0|100] "percent"  GENERIC
 SG_ HeadLghtHiFdbck_D_Stat : 55|2@0+ (1,0) [0|3] "SED"  GENERIC
 SG_ PrkLightChime_B_Rq : 25|1@0+ (1,0) [0|1] "SED"  IPC
 SG_ TrnNotInPrkChime_B_Rq : 24|1@0+ (1,0) [0|1] "SED"  IPC
 SG_ KeyInIgnWarn_B_Cmd : 27|1@0+ (1,0) [0|1] "SED"  IPC
 SG_ HomeSafeLtChime_B_Rq : 28|1@0+ (1,0) [0|1] "SED"  IPC
 SG_ StopLghtOn_B_Stat : 8|1@0+ (1,0) [0|1] "SED"  TRM_ITRM
 SG_ RvrseLghtOn_B_Stat : 9|1@0+ (1,0) [0|1] "SED"  APIM_CISM,APIM
 SG_ PrkLght_D_Stat : 13|2@0+ (1,0) [0|3] "SED" Vector__XXX
 SG_ HeadLghtSwtch_D_Stat : 15|2@0+ (1,0) [0|3] "SED"  IPC
 SG_ HeadLampLoFrOn_B_Stat : 2|1@0+ (1,0) [0|1] "SED"  GENERIC
 SG_ HeadLampLoFlOn_B_Stat : 3|1@0+ (1,0) [0|1] "SED"  GENERIC
 SG_ HeadLampLoActv_B_Stat : 4|1@0+ (1,0) [0|1] "SED"  APIM_CISM,APIM
 SG_ Headlamp_On_Wrning_Cmd : 29|1@0+ (1,0) [0|1] "SED"  IPC
 SG_ HeadLghtHiOn_B_Stat : 1|1@0+ (1,0) [0|1] "SED"  APIM,APIM_CISM,IPC
 SG_ Park_Brake_Chime_Rqst : 26|1@0+ (1,0) [0|1] "SED"  IPC
 SG_ BrkWarnInd_B_Rq : 20|1@0+ (1,0) [0|1] "SED"  IPC
 SG_ Brk_Fluid_Lvl_Low : 31|2@0+ (1,0) [0|3] "SED"  IPC
 SG_ ReducedGuard_D_Stat : 19|2@0+ (1,0) [0|3] "SED"  IPC
 SG_ PudLampDrv_D_Rq : 59|2@0+ (1,0) [0|3] "SED" Vector__XXX
 SG_ Courtesy_BSave_Stat : 7|2@0+ (1,0) [0|3] "SED"  APIM_CISM,ACM
 SG_ DayRnngLampOn_B_Stat : 5|1@0+ (1,0) [0|1] "SED"  IPC
 SG_ PerimeterAlarmChimeRq : 0|1@0+ (1,0) [0|1] "SED"  IPC
 SG_ Perimeter_Alarm_Status : 17|2@0+ (1,0) [0|3] "SED"  TRM_ITRM
 SG_ WndwGlbl_D_Cmd : 23|3@0+ (1,0) [0|7] "SED" Vector__XXX
 SG_ DrTgateLck_D_Stat : 61|2@0+ (1,0) [0|3] "SED"  IPC
 SG_ PudLamp_D_Rq : 11|2@0+ (1,0) [0|3] "SED"  HUD_ADV,APIM_CISM,APIM

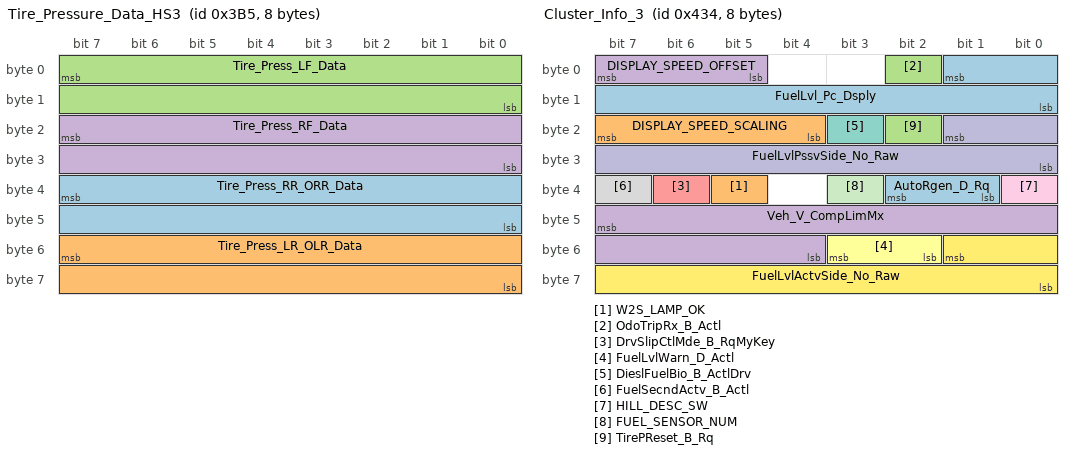
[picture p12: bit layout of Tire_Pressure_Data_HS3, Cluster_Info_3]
BO_ 949 Tire_Pressure_Data_HS3: 8 GWM
 SG_ Tire_Press_RR_ORR_Data : 39|16@0+ (1,0) [0|65533] "kilopascal"  APIM_CISM,APIM,IPC
 SG_ Tire_Press_LR_OLR_Data : 55|16@0+ (1,0) [0|65533] "kilopascal"  APIM_CISM,APIM,IPC
 SG_ Tire_Press_LF_Data : 7|16@0+ (1,0) [0|65533] "kilopascal"  APIM_CISM,APIM,IPC
 SG_ Tire_Press_RF_Data : 23|16@0+ (1,0) [0|65533] "kilopascal"  APIM_CISM,APIM,IPC

BO_ 2015 TesterFunctionalReq_H3: 8 TSTR
 SG_ TesterFunctionalReq : 7|64@0+ (1,0) [0|1.84467E+019] "unitless"  RACM_RCIM,APIM,DACMC,APIM_CISM,DSP,HUD_ADV,TRM_ITRM,FCIMB,WCM,ACM,IPC,GWM

BO_ 1076 Cluster_Info_3: 8 IPC
 SG_ AutoRgen_D_Rq : 34|2@0+ (1,0) [0|3] "SED"  GWM
 SG_ W2S_LAMP_OK : 37|1@0+ (1,0) [0|1] "SED"  GWM
 SG_ OdoTripRx_B_Actl : 2|1@0+ (1,0) [0|1] "SED"  GWM
 SG_ Veh_V_CompLimMx : 47|12@0+ (0.1,0) [0|409.5] "km/h"  GWM
 SG_ DrvSlipCtlMde_B_RqMyKey : 38|1@0+ (1,0) [0|1] "SED"  GWM
 SG_ FuelLvlWarn_D_Actl : 51|2@0+ (1,0) [0|3] "SED"  HUD_ADV,APIM_CISM,APIM,GWM
 SG_ DieslFuelBio_B_ActlDrv : 19|1@0+ (1,0) [0|1] "SED"  GWM
 SG_ FuelSecndActv_B_Actl : 39|1@0+ (1,0) [0|1] "SED"  GWM
 SG_ HILL_DESC_SW : 32|1@0+ (1,0) [0|1] "SED"  GWM
 SG_ FuelLvlPssvSide_No_Raw : 17|10@0+ (1,0) [0|1023] "Unitless"  GWM
 SG_ FUEL_SENSOR_NUM : 35|1@0+ (1,0) [0|1] "SED"  GWM
 SG_ FuelLvlActvSide_No_Raw : 49|10@0+ (1,0) [0|1023] "Unitless"  GWM
 SG_ FuelLvl_Pc_Dsply : 1|10@0+ (0.108696,-5.217408) [-5.217408|105.9786] "Percent"  APIM_CISM,APIM,GWM
 SG_ DISPLAY_SPEED_SCALING : 23|4@0+ (0.5,100) [100|107.5] "%"  GWM
 SG_ TirePReset_B_Rq : 18|1@0+ (1,0) [0|1] "SED"  GWM
 SG_ DISPLAY_SPEED_OFFSET : 7|3@0+ (0.5,0) [0|3.5] "kph"  GWM

BO_ 709 DSPAMP_RDISP_WORD_Tx: 8 DSP
 SG_ DSPAMP_RDISP_WORD_Tx : 7|64@0+ (1,0) [0|1.84467440737096E+019] "unitless"  APIM_CISM,APIM

BO_ 552 DSPAMP_Send_Signals: 8 DSP
 SG_ DSP_Treble_St : 55|4@0+ (1,-7) [-7|8] "unitless"  APIM_CISM,APIM
 SG_ DSP_VoiceFBVolume_Up : 35|1@0+ (1,0) [0|1] "SED"  IPC,HUD_ADV,APIM_CISM,APIM
 SG_ DSP_VoiceFBVolume_St : 63|5@0+ (1,0) [0|30] "unitless"  IPC,WCM,HUD_ADV,APIM_CISM,APIM
 SG_ DSP_TAVolume_Up : 34|1@0+ (1,0) [0|1] "SED"  IPC,HUD_ADV,APIM_CISM,APIM
 SG_ DSP_TAVolume_St : 44|5@0+ (1,0) [0|30] "unitless"  IPC,WCM,HUD_ADV,APIM_CISM,APIM
 SG_ DSP_Shaker_St : 1|1@0+ (1,0) [0|1] "SED"  APIM_CISM,APIM
 SG_ DSP_Reg_St : 27|2@0+ (1,0) [0|3] "SED"  APIM_CISM,APIM
 SG_ DSP_PhoneVolume_Up : 25|1@0+ (1,0) [0|1] "SED"  IPC,HUD_ADV,APIM_CISM,APIM
 SG_ DSP_PhoneVolume_St : 33|5@0+ (1,0) [0|30] "unitless"  IPC,WCM,HUD_ADV,APIM_CISM,APIM
 SG_ DSP_NavCmdVolume_Up : 7|1@0+ (1,0) [0|1] "SED"  IPC,HUD_ADV,APIM_CISM,APIM
 SG_ DSP_NavCmdVolume_St : 24|5@0+ (1,0) [0|30] "SED"  IPC,WCM,HUD_ADV,APIM_CISM,APIM
 SG_ DSP_Midrange_St : 51|4@0+ (1,-7) [-7|8] "unitless"  APIM_CISM,APIM
 SG_ DSP_Fader_St : 20|4@0+ (1,-7) [-7|8] "unitless"  APIM_CISM,APIM
 SG_ DSP_DSPProgram_St : 15|3@0+ (1,0) [0|7] "SED"  APIM_CISM,APIM
 SG_ DSP_DSP_St : 16|5@0+ (1,0) [0|31] "SED"  APIM_CISM,APIM
 SG_ DSP_Bass_St : 12|4@0+ (1,-7) [-7|8] "unitless"  APIM_CISM,APIM
 SG_ DSP_Balance_St : 8|4@0+ (1,-7) [-7|8] "unitless"  APIM_CISM,APIM
 SG_ DSP_AVC_St : 6|3@0+ (1,0) [0|7] "SED"  APIM_CISM,APIM
 SG_ Audio_Demo_Status : 0|1@0+ (1,0) [0|1] "SED"  APIM_CISM,APIM

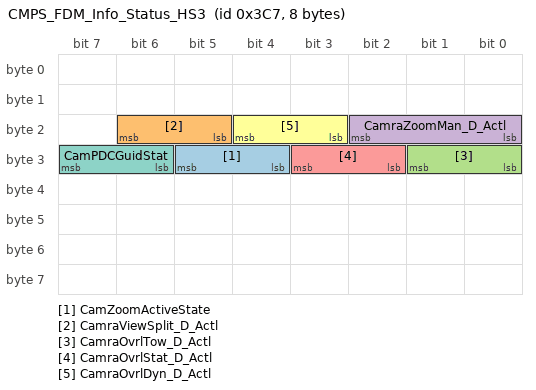
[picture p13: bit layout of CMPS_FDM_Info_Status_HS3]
BO_ 967 CMPS_FDM_Info_Status_HS3: 8 GWM
 SG_ CamZoomActiveState : 29|2@0+ (1,0) [0|3] "SED"  APIM_CISM,APIM
 SG_ CamraViewSplit_D_Actl : 22|2@0+ (1,0) [0|3] "SED"  APIM_CISM,APIM
 SG_ CamraOvrlTow_D_Actl : 25|2@0+ (1,0) [0|3] "SED"  APIM_CISM,APIM
 SG_ CamraZoomMan_D_Actl : 18|3@0+ (1,0) [0|7] "SED"  APIM_CISM,APIM
 SG_ CamraOvrlStat_D_Actl : 27|2@0+ (1,0) [0|3] "SED"  APIM_CISM,APIM
 SG_ CamraOvrlDyn_D_Actl : 20|2@0+ (1,0) [0|3] "SED"  APIM_CISM,APIM
 SG_ CamPDCGuidStat : 31|2@0+ (1,0) [0|3] "SED"  APIM_CISM,APIM

BO_TX_BU_ 729 : APIM_CISM,ACM;
BO_TX_BU_ 727 : APIM_CISM,ACM;
BO_TX_BU_ 726 : APIM_CISM,ACM;
BO_TX_BU_ 1091 : GWM,TRM_ITRM;
BO_TX_BU_ 530 : APIM_CISM,APIM;
BO_TX_BU_ 707 : APIM_CISM,ACM;
BO_TX_BU_ 551 : APIM_CISM,APIM;
CM_ SG_ 729 ACU_VoiceFBVolume_Up "Object Audio.VoiceFBVolume_UP
Object.AHU_VR_Vol_Updated
Indicate user value recalls if the value is set to lower/upper border ";
CM_ SG_ 729 ACU_VoiceFBVolume_St "Object Audio.VoiceFBVolume
Method AHU_VR_Vol_Level_St()

Refer method table in SPSS for details
0x0 No Volume
0x1 Vol_Step1
0x2 Vol_Step2
0x3 Vol_Step3
Cont.
0x1E Vol_Step30";
CM_ SG_ 729 ACU_Treble_St "Object Audio.Treble

Treble.St



Level -7..0..7


Method: AHU_Treble";
CM_ SG_ 729 ACU_TAVolume_Up "Object Audio.TAVolume_UP
Indicate user value recalls if the value is set to lower/upper border 
Method AHU_TA_Vol_Updated ";
CM_ SG_ 729 ACU_TAVolume_St "Object Audio.TAVolume
Method AHU_TA_Vol_Level.St 

Refer method table in SPSS for details
0x0 No Volume
0x1 Vol_Step1
0x2 Vol_Step2
0x3 Vol_Step3
Cont.
0x1E Vol_Step30";
CM_ SG_ 729 ACU_Reg_St "Object Tuner.REG";
CM_ SG_ 729 ACU_PhoneVolume_Up "Object Audio.PhoneVolume_UP

Object.VolumeControl.AHU_Phone_Vol_Updated";
CM_ SG_ 729 ACU_PhoneVolume_St "Object Audio.PhoneVolume
AHU_Phone_Vol_Level.St
0x0 No Volume
0x1 Vol_Step1
0x2 Vol_Step2
0x3 Vol_Step3
Cont.
0x1E Vol_Step30";
CM_ SG_ 729 ACU_NavCmdVolume_Up "Object Audio.NavCmdVolume_UP. AHU_Prompt_Vol_Updated. ";
CM_ SG_ 729 ACU_NavCmdVolume_St "Object Audio.NavCmdVolume. AHU_Prompt_Vol_Level.St()

Refer method table in SPSS for details
0x0 No Volume
0x1 Vol_Step1
0x2 Vol_Step2
0x3 Vol_Step3
Cont.
0x1E Vol_Step30";
CM_ SG_ 729 ACU_Fader_St "Object Audio.Fader



Fade.St

Level -7..0..7


Method: AHU_Fade";
CM_ SG_ 729 ACU_DSPProgram_St "Object Audio.DSPProgram
";
CM_ SG_ 729 ACU_DSP_St "Object. Audio.DSP
Object: AudioSettings.AHU_Occupancy_Mode.St";
CM_ SG_ 729 ACU_Bass_St "Object Audio.Bass



Bass.St

Level -7..0..7


Method: AHU_Bass";
CM_ SG_ 729 ACU_Balance_St "Object Audio.Balance

Balance.St



Level -7..0..7


Method: AHU_Balance";
CM_ SG_ 729 ACU_AVC_St "Object Audio.AVC
Off, Level 1 .. Level 7

Method: AHU_Speed_Comp_Vol.St";
CM_ SG_ 727 ACU_LoadEjectMode_St "Object Indash CD Changer.LoadEject(Action)";
CM_ SG_ 727 ACU_LoadEjectDisc_St "Object Indash CD Changer.LoadEject(Disc Number)";
CM_ SG_ 726 ACU_SelectedPTYCodes_St "Object Tuner.SelectedPTYCodes

Bit 0: 0: invalid, 1: valid
Bit 1: 0: PTY code 2 not selected; 1: PTY code 2 selected
...
Bit 28: 0: PTY code 29 not selected; 1: PTY code 29 selected";
CM_ SG_ 726 ACU_TAMode_St "Object Tuner.TAMode";
CM_ SG_ 726 ACU_NEWSMode_St "Object Tuner.NEWSMode";
CM_ SG_ 726 ACU_AFJump_St "Object Tuner.AFJump.St";
CM_ SG_ 1071 CluPdl_PcRate_Actl "Signal not transmitted on HEV variants.";
CM_ SG_ 1071 CluPdlPosPcMeas_D_Qf "Signal not transmitted on HEV variants.";
CM_ SG_ 1071 CluPdlPos_Pc_Meas "Signal not transmitted on HEV variants.";
CM_ SG_ 1071 EngAoutIdl_N_Ntrl "Signal not transmitted on HEV variants and diesel.";
CM_ BO_ 891 "DACMC Tx";
CM_ SG_ 839 FohStop_B_Stat "Signal not transmitted on vehicles that do not have the Fuel operated heater feature.";
CM_ SG_ 839 FohMsgTxt_D_Rq "Signal not transmitted on vehicles that do not have the Fuel operated heater feature.";
CM_ SG_ 839 FohKeyOff_B_Rq "Signal not transmitted on vehicles that do not have the Fuel operated heater feature.";
CM_ SG_ 839 FohEnbl_B_Rq "Signal not transmitted on vehicles that do not have the Fuel operated heater feature.";
CM_ SG_ 839 FohTAllEnable_B_Stat "Signal not transmitted on vehicles that do not have the Fuel operated heater feature.";
CM_ SG_ 839 FohT2Mnte_T_Stat "Signal not transmitted on vehicles that do not have the Fuel operated heater feature.";
CM_ SG_ 839 FohT2Hr_T_Stat "Signal not transmitted on vehicles that do not have the Fuel operated heater feature.";
CM_ SG_ 839 FohT2Enable_B_Stat "Signal not transmitted on vehicles that do not have the Fuel operated heater feature.";
CM_ SG_ 839 FohT1Mnte_T_Stat "Signal not transmitted on vehicles that do not have the Fuel operated heater feature.";
CM_ SG_ 839 FohT1Hr_T_Stat "Signal not transmitted on vehicles that do not have the Fuel operated heater feature.";
CM_ SG_ 839 FohT1Enable_B_Stat "Signal not transmitted on vehicles that do not have the Fuel operated heater feature.";
CM_ SG_ 839 FohStrtMnte_T_Stat "Signal not transmitted on vehicles that do not have the Fuel operated heater feature.";
CM_ SG_ 839 FohStrtHr_T_Stat "Signal not transmitted on vehicles that do not have the Fuel operated heater feature.";
CM_ SG_ 839 FohStrtEnable_B_Stat "Signal not transmitted on vehicles that do not have the Fuel operated heater feature.";
CM_ SG_ 839 FohContOn_B_Stat "Signal not transmitted on vehicles that do not have the Fuel operated heater feature.";
CM_ SG_ 839 FohStrtDay_T_Stat "Signal not transmitted on vehicles that do not have the Fuel operated heater feature.";
CM_ SG_ 839 FohT2Wednesday_T_Stat "Signal not transmitted on vehicles that do not have the Fuel operated heater feature.";
CM_ SG_ 839 FohT2Tuesday_T_Stat "Signal not transmitted on vehicles that do not have the Fuel operated heater feature.";
CM_ SG_ 839 FohT2Thursday_T_Stat "Signal not transmitted on vehicles that do not have the Fuel operated heater feature.";
CM_ SG_ 839 FohT2Sunday_T_Stat "Signal not transmitted on vehicles that do not have the Fuel operated heater feature.";
CM_ SG_ 839 FohT2Saturday_T_Stat "Signal not transmitted on vehicles that do not have the Fuel operated heater feature.";
CM_ SG_ 839 FohT2Monday_T_Stat "Signal not transmitted on vehicles that do not have the Fuel operated heater feature.";
CM_ SG_ 839 FohT2Friday_T_Stat "Signal not transmitted on vehicles that do not have the Fuel operated heater feature.";
CM_ SG_ 839 FohT1Wednesday_T_Stat "Signal not transmitted on vehicles that do not have the Fuel operated heater feature.";
CM_ SG_ 839 FohT1Tuesday_T_Stat "Signal not transmitted on vehicles that do not have the Fuel operated heater feature.";
CM_ SG_ 839 FohT1Thursday_T_Stat "Signal not transmitted on vehicles that do not have the Fuel operated heater feature.";
CM_ SG_ 839 FohT1Sunday_T_Stat "Signal not transmitted on vehicles that do not have the Fuel operated heater feature.";
CM_ SG_ 839 FohT1Saturday_T_Stat "Signal not transmitted on vehicles that do not have the Fuel operated heater feature.";
CM_ SG_ 839 FohT1Monday_T_Stat "Signal not transmitted on vehicles that do not have the Fuel operated heater feature.";
CM_ SG_ 839 FohT1Friday_T_Stat "Signal not transmitted on vehicles that do not have the Fuel operated heater feature.";
CM_ SG_ 1091 PoliceAux4Lamp_B_Rq2 "Signal not transmitted on programs that do not have AWD.";
CM_ SG_ 1091 PoliceAux3Lamp_B_Rq2 "Signal not transmitted on programs that do not have AWD.";
CM_ SG_ 1091 PoliceAux2Lamp_B_Rq2 "Signal not transmitted on programs that do not have AWD.";
CM_ SG_ 1091 PoliceAux1Lamp_B_Rq2 "Signal not transmitted on programs that do not have AWD.";
CM_ SG_ 1072 MetricActv_B_Actl "0 =Inactive(English), 1=Active(Metric)";
CM_ SG_ 1034 VehicleGGCCData "RCMGenSigTimeout=6000";
CM_ SG_ 1069 SlMde_D_Stat "IPC and HUD_ADV Receve from HS3 FGW 0x42D, not HS3 0x38A, MSG DCR 506.";
CM_ SG_ 1069 SlMde_D_RqDsply "IPC and HUD_ADV Receve from HS3 FGW 0x42D, not HS3 0x38A, MSG DCR 506.";
CM_ SG_ 1069 EngMsgTxt_D_Rq "Signal not transmitted on diesel variants.";
CM_ SG_ 1069 EngClnt_Te_ActlDiag "Signal not transmitted on gas variants.";
CM_ SG_ 1069 EngLoad_Pc_CalcDiag "Signal not transmitted on gas variants.";
CM_ SG_ 1069 ApedPos_Pc_ActlDiag "Signal not transmitted on gas variants.";
CM_ SG_ 1069 ObdWarmUp_B_Complt "Signal not transmitted on gas and diesel variants.";
CM_ SG_ 1057 FohEng_D_Rq "Signal not transmitted on vehicles that do not have the fuel operated heater feature.";
CM_ SG_ 1057 EngIdlShutDown_D_Stat "Signal not transmitted on diesel variants.";
CM_ SG_ 1057 FUEL_ALCOHOL_PERCNT "signal not transmitted on diesel and HEV variants.";
CM_ SG_ 1057 TrnTotTq_Rt_Est "Signal not transmitted on gas and HEV variants.";
CM_ SG_ 1057 TrnTotLss_Tq_Est "Signal not transmitted on gas and HEV variants.";
CM_ SG_ 1057 VehVLimStat_D_Actl "Signal not transmitted on gas and HEV variants.";
CM_ SG_ 1057 VehVLimActv_B_Actl "Signal not transmitted on gas and HEV variants.";
CM_ SG_ 516 ApedPos_Pc_ActlArb "ABSGenSigTimeoutTime=1000";
CM_ SG_ 516 ApedPosPcActl_No_Cs "Signal not transmitted on gas and diesel variants.";
CM_ SG_ 516 EngAout3_N_Actl "Signal not transmitted on gas and diesel variants.";
CM_ SG_ 516 ApedPosPcActl_No_Cnt "Signal not transmitted on gas and diesel variants.";
CM_ SG_ 514 GearRvrse_D_Actl "Do not implement GearRvrse_D_Actl  until eTracker 8804151 is approved, 11/24/09";
CM_ SG_ 514 EngAout_Tq_VacLimSpcN "Signal not transmitted on gas and diesel variances.";
CM_ SG_ 514 EngCylSync_No_Ctr "Signal not transmitted on gas and diesel variances.";
CM_ SG_ 377 EngFuelCutFull_B_Inhbt "Signal not transmitted on diesel variants.";
CM_ SG_ 377 FuelFlw_Vl_Dsply "Signal not transmitted on diesel variants.";
CM_ SG_ 377 FuelFillInlet_B_Dsply "Signal not transmitted on diesel variants.";
CM_ SG_ 377 OdoCount "Signal not transmitted on diesel variants.";
CM_ SG_ 377 EngOilLife_Pc_Actl "Signal not transmitted on diesel variants.";
CM_ SG_ 377 TrnKickDown_B_RqDrv "Signal not transmitted on diesel variants.";
CM_ SG_ 377 AirCondRec_B_Rq "Signal not transmitted on diesel variants.";
CM_ SG_ 377 AirCondClutch_B_Stats "Signal not transmitted on diesel variants.";
CM_ SG_ 376 EngAout_Aa_Actl "Signal not transmitted on HEV variants.";
CM_ SG_ 373 EngFuelCutFull_B_Allw "Signal not transmitted on diesel variances.";
CM_ SG_ 342 EngOvrhtMitgActv_D_Ind "Signal not transmitted on diesel.";
CM_ SG_ 342 EngGoutLss_Tq_Est "Signal not transmitted on gas and diesel variants.";
CM_ SG_ 707 SSPClnt_SSPSrv_WORD_Tx "Tx by HS3 APIM";
CM_ BO_ 673 "Do not use this Frame for other Cluster Interaction";
CM_ SG_ 673 ICI_Coding_BtnID_D "Object InputControlInterface ICI ButtonCoding_D
(Parameter2)";
CM_ SG_ 673 ICI_Coding_BtnID_C "Object InputControlInterface ICI ButtonCoding_C
(Parameter2)";
CM_ SG_ 673 ICI_Coding_BtnID_B "Object InputControlInterface ICI ButtonCoding_B
(Parameter2)";
CM_ SG_ 673 ICI_Coding_BtnID_A "Object InputControlInterface ICI ButtonCoding_A
(Parameter2)";
CM_ SG_ 673 ICI_BtnID_D "Object InputControlInterface ICI ButtonID_D
(Parameter1)
for detailed Information refer to ICI Reference document";
CM_ SG_ 673 ICI_BtnID_C "Object InputControlInterface ICI ButtonID_C
(Parameter1)
for detailed Information refer to ICI Reference document";
CM_ SG_ 673 ICI_BtnID_B "Object InputControlInterface ICI ButtonID_B
(Parameter1)
for detailed Information refer to ICI Reference document";
CM_ SG_ 673 ICI_BtnID_A "Object InputControlInterface ICI ButtonID_A
(Parameter1)
for detailed Information refer to ICI Reference document";
CM_ BO_ 949 "For 2010MY and beyond, use for SCT (non-CGEA) and CGEA modules";
CM_ BO_ 2015 "OBDII Request ($7DF) messages are for FNOS 1.0.1 only.
Diagnostic Functional Addressing ($7DF) and Dual Rate Periodic messages are for FNOS I3 only.";
CM_ SG_ 709 DSPAMP_RDISP_WORD_Tx "Object:BezelDiagnostics.DSP_Bezel_Diag_Data";
CM_ SG_ 552 DSP_Treble_St "Object Audio.Treble.St

Level -7..0..7";
CM_ SG_ 552 DSP_VoiceFBVolume_Up "Object AudioControl.DSP_VR_Vol_updated";
CM_ SG_ 552 DSP_VoiceFBVolume_St "Object.VolumeControl.DSP_VR_Vol_Level.St 
0x0 No Volume
0x1 Vol_Step1
0x2 Vol_Step2
0x3 Vol_Step3
Cont.
0x1E Vol_Step30";
CM_ SG_ 552 DSP_TAVolume_Up "Object Audio.DSP_TA_Vol_Updated
Indicate user value recalls if the value is set to lower/upper border ";
CM_ SG_ 552 DSP_TAVolume_St "Object.VolumeControl.DSP_TA_Vol_Level.St

0x0 No Volume
0x1 Vol_Step1
0x2 Vol_Step2
0x3 Vol_Step3
Cont.
0x1E Vol_Step30";
CM_ SG_ 552 DSP_Shaker_St "Method DSP_Shaker.St";
CM_ SG_ 552 DSP_Reg_St "Object Tuner.REG";
CM_ SG_ 552 DSP_PhoneVolume_Up "Object.VolumeControl.DSP_Phone_Vol_Updated
";
CM_ SG_ 552 DSP_PhoneVolume_St "Object.VolumeControl.DSP_Phone_Vol_Level.St

0x0 No Volume
0x1 Vol_Step1
0x2 Vol_Step2
0x3 Vol_Step3
Cont.
0x1E Vol_Step30";
CM_ SG_ 552 DSP_NavCmdVolume_Up "Object Audio.NavCmdVolume_UP. DSP_Prompt_Vol_Updated
";
CM_ SG_ 552 DSP_NavCmdVolume_St "Object Audio.NavCmdVolume. DSP_Prompt_Vol_Level.St

0x0 No Volume
0x1 Vol_Step1
0x2 Vol_Step2
0x3 Vol_Step3
Cont.
0x1E Vol_Step30";
CM_ SG_ 552 DSP_Midrange_St "MidRange.St

Level -7..0..7";
CM_ SG_ 552 DSP_Fader_St "Object Audio.Fader

Fade.St

Level -7..0..7";
CM_ SG_ 552 DSP_DSPProgram_St "Object Audio.DSPProgram
";
CM_ SG_ 552 DSP_DSP_St "Object Audio.DSP

";
CM_ SG_ 552 DSP_Bass_St "Object Audio.Bass.St

Level -7..0..7";
CM_ SG_ 552 DSP_Balance_St "Object Audio.Balance.St

Level -7..0..7";
CM_ SG_ 552 DSP_AVC_St "Object Audio.AVC
Off, Level 1 .. Level 7

Object.AudioSettings.DSP_Speed_Comp_Vol.St 
";
CM_ SG_ 552 Audio_Demo_Status "Object.AudioSettings.Audio_Demo_Status";
CM_ BO_ 967 "2008' programs, Tx by IC;  updated on 5/6/05";
BA_DEF_ BO_  "FrameRouting" STRING ;
BA_DEF_ BO_  "FrameGatewayNetwork" STRING ;
BA_DEF_ BO_  "NetworkInitialization" ENUM  "No","Yes";
BA_DEF_ BO_  "FrameGatewayId" HEX 0 1407;
BA_DEF_ BO_  "EventRateOfChange" INT 10 10000;
BA_DEF_ BO_  "GenMsgStartDelayTime" INT 0 10000;
BA_DEF_ BO_  "GenMsgNrOfRepetition" INT 0 100;
BA_DEF_ BO_  "GenMsgDelayTime" INT 0 1000;
BA_DEF_ BO_  "GenMsgCycleTime" INT 0 100000;
BA_DEF_ BO_  "GenMsgSendType" ENUM  "FixedPeriodic","Event","EnabledPeriodic","NotUsed","NotUsed","EventPeriodic","NotUsed","NotUsed","NoMsgSendType";
BA_DEF_ SG_  "U_U55X_MY2022_Tx" ENUM  "No","Yes";
BA_DEF_ SG_  "U_CD542_MY2021_Tx" ENUM  "No","Yes";
BA_DEF_ SG_  "ECGUsedTxSignal" ENUM  "No","Yes";
BA_DEF_ SG_  "U_T6_MCA_MY2020_Tx" ENUM  "No","Yes";
BA_DEF_ SG_  "U_P702_MY2021_Tx" ENUM  "No","Yes";
BA_DEF_ SG_  "U_CX727_MY2021_Tx" ENUM  "No","Yes";
BA_DEF_ SG_  "U_FNV2_IVI_Rx" ENUM  "No","Yes";
BA_DEF_ SG_  "U_U55X_MY2022_Rx" ENUM  "No","Yes";
BA_DEF_ SG_  "U_CD542_MY2021_Rx" ENUM  "No","Yes";
BA_DEF_ SG_  "ECGUsedRxSignal" ENUM  "No","Yes";
BA_DEF_ SG_  "U_T6_MCA_MY2020_Rx" ENUM  "No","Yes";
BA_DEF_ SG_  "U_P702_MY2021_Rx" ENUM  "No","Yes";
BA_DEF_ SG_  "U_CX727_MY2021_Rx" ENUM  "No","Yes";
BA_DEF_ SG_  "GenSigStartValue" HEX 0 268435455;
BA_DEF_ SG_  "MetaData" ENUM  "No","Yes";
BA_DEF_ SG_  "ContentDependant" ENUM  "No","Yes";
BA_DEF_ SG_  "GenSigStartValueInteger" INT 0 1000000000;
BA_DEF_ SG_  "UsedOnPgmDBC" ENUM  "No","Yes";
BA_DEF_ SG_  "WakeupSignal" ENUM  "No","Yes";
BA_DEF_ SG_  "GenSigInactiveValue" INT 0 100000;
BA_DEF_ SG_  "GenSigSendType" ENUM  "Cyclic","OnWrite","vector_leerstring","OnChange","vector_leerstring","IfActive","vector_leerstring","NoSigSendType";
BA_DEF_ BO_  "OvtpPushApplication" ENUM  "FALSE","TRUE";
BA_DEF_ BO_  "SCP_FreshnessValueLength" INT 0 512;
BA_DEF_ BO_  "SCP_FreshnessValueTxLength" INT 0 512;
BA_DEF_ BO_  "SCP_AuthInfoTxLength" INT 0 512;
BA_DEF_ BO_  "GenMsgRoutingTimeoutTime" INT 0 5000;
BA_DEF_ BO_  "MessageGateway" ENUM  "No","Yes";
BA_DEF_ BO_  "NmAsrMessage" ENUM  "No","Yes";
BA_DEF_ BO_  "DiagState" ENUM  "No","Yes";
BA_DEF_ BO_  "TpTxIndex" INT 0 536870911;
BA_DEF_ BO_  "DiagRequest" ENUM  "No","Yes";
BA_DEF_ BO_  "DiagResponse" ENUM  "No","Yes";
BA_DEF_ BO_  "GenMsgILSupport" ENUM  "No","Yes";
BA_DEF_DEF_  "FrameRouting" "";
BA_DEF_DEF_  "FrameGatewayNetwork" "NONE";
BA_DEF_DEF_  "NetworkInitialization" "Yes";
BA_DEF_DEF_  "FrameGatewayId" 0;
BA_DEF_DEF_  "EventRateOfChange" 10000;
BA_DEF_DEF_  "GenMsgStartDelayTime" 0;
BA_DEF_DEF_  "GenMsgNrOfRepetition" 1;
BA_DEF_DEF_  "GenMsgDelayTime" 20;
BA_DEF_DEF_  "GenMsgCycleTime" 0;
BA_DEF_DEF_  "GenMsgSendType" "NoMsgSendType";
BA_DEF_DEF_  "U_U55X_MY2022_Tx" "No";
BA_DEF_DEF_  "U_CD542_MY2021_Tx" "No";
BA_DEF_DEF_  "ECGUsedTxSignal" "No";
BA_DEF_DEF_  "U_T6_MCA_MY2020_Tx" "No";
BA_DEF_DEF_  "U_P702_MY2021_Tx" "No";
BA_DEF_DEF_  "U_CX727_MY2021_Tx" "No";
BA_DEF_DEF_  "U_FNV2_IVI_Rx" "No";
BA_DEF_DEF_  "U_U55X_MY2022_Rx" "No";
BA_DEF_DEF_  "U_CD542_MY2021_Rx" "No";
BA_DEF_DEF_  "ECGUsedRxSignal" "No";
BA_DEF_DEF_  "U_T6_MCA_MY2020_Rx" "No";
BA_DEF_DEF_  "U_P702_MY2021_Rx" "No";
BA_DEF_DEF_  "U_CX727_MY2021_Rx" "No";
BA_DEF_DEF_  "GenSigStartValue" 0;
BA_DEF_DEF_  "MetaData" "No";
BA_DEF_DEF_  "ContentDependant" "No";
BA_DEF_DEF_  "GenSigStartValueInteger" 0;
BA_DEF_DEF_  "UsedOnPgmDBC" "Yes";
BA_DEF_DEF_  "WakeupSignal" "No";
BA_DEF_DEF_  "GenSigInactiveValue" 0;
BA_DEF_DEF_  "GenSigSendType" "NoSigSendType";
BA_DEF_DEF_  "OvtpPushApplication" "FALSE";
BA_DEF_DEF_  "SCP_FreshnessValueLength" 64;
BA_DEF_DEF_  "SCP_FreshnessValueTxLength" 11;
BA_DEF_DEF_  "SCP_AuthInfoTxLength" 53;
BA_DEF_DEF_  "GenMsgRoutingTimeoutTime" 0;
BA_DEF_DEF_  "MessageGateway" "No";
BA_DEF_DEF_  "NmAsrMessage" "No";
BA_DEF_DEF_  "DiagState" "No";
BA_DEF_DEF_  "TpTxIndex" 0;
BA_DEF_DEF_  "DiagRequest" "No";
BA_DEF_DEF_  "DiagResponse" "No";
BA_DEF_DEF_  "GenMsgILSupport" "Yes";
BA_ "GenMsgCycleTime" BO_ 729 1000;
BA_ "GenMsgSendType" BO_ 729 5;
BA_ "GenMsgCycleTime" BO_ 727 1000;
BA_ "GenMsgSendType" BO_ 727 5;
BA_ "GenMsgCycleTime" BO_ 726 1000;
BA_ "GenMsgSendType" BO_ 726 5;
BA_ "FrameRouting" BO_ 369 "FD1_CAN,0x171;";
BA_ "FrameGatewayNetwork" BO_ 369 "FD1_CAN";
BA_ "FrameGatewayId" BO_ 369 369;
BA_ "GenMsgDelayTime" BO_ 369 15;
BA_ "NetworkInitialization" BO_ 1832 0;
BA_ "GenMsgDelayTime" BO_ 1832 0;
BA_ "GenMsgSendType" BO_ 1832 1;
BA_ "DiagResponse" BO_ 1832 1;
BA_ "GenMsgILSupport" BO_ 1832 0;
BA_ "GenMsgCycleTime" BO_ 1071 50;
BA_ "GenMsgSendType" BO_ 1071 0;
BA_ "GenMsgRoutingTimeoutTime" BO_ 1071 90;
BA_ "MessageGateway" BO_ 1071 1;
BA_ "GenMsgCycleTime" BO_ 848 1000;
BA_ "GenMsgSendType" BO_ 848 0;
BA_ "GenMsgCycleTime" BO_ 891 100;
BA_ "GenMsgSendType" BO_ 891 0;
BA_ "FrameRouting" BO_ 610 "FD1_CAN,0x262;HS1_CAN,0x262";
BA_ "FrameGatewayNetwork" BO_ 610 "FD1_CAN";
BA_ "FrameGatewayId" BO_ 610 610;
BA_ "FrameRouting" BO_ 839 "MS1_CAN,0x347;";
BA_ "FrameGatewayNetwork" BO_ 839 "MS1_CAN";
BA_ "FrameGatewayId" BO_ 839 839;
BA_ "GenMsgCycleTime" BO_ 1091 1000;
BA_ "GenMsgSendType" BO_ 1091 5;
BA_ "NetworkInitialization" BO_ 1425 0;
BA_ "GenMsgCycleTime" BO_ 1425 1000;
BA_ "GenMsgSendType" BO_ 1425 0;
BA_ "NmAsrMessage" BO_ 1425 1;
BA_ "GenMsgILSupport" BO_ 1425 0;
BA_ "FrameRouting" BO_ 998 "HS2_CAN,0x3E6;";
BA_ "FrameGatewayNetwork" BO_ 998 "HS2_CAN";
BA_ "FrameGatewayId" BO_ 998 998;
BA_ "FrameRouting" BO_ 984 "FD1_CAN,0x3D8;HS2_CAN,0x3D8";
BA_ "GenMsgCycleTime" BO_ 1072 100;
BA_ "GenMsgSendType" BO_ 1072 5;
BA_ "GenMsgCycleTime" BO_ 395 1000;
BA_ "GenMsgSendType" BO_ 395 5;
BA_ "NetworkInitialization" BO_ 1438 0;
BA_ "GenMsgCycleTime" BO_ 1438 1000;
BA_ "GenMsgSendType" BO_ 1438 0;
BA_ "NmAsrMessage" BO_ 1438 1;
BA_ "GenMsgILSupport" BO_ 1438 0;
BA_ "FrameRouting" BO_ 76 "HS2_CAN,0x4C;";
BA_ "FrameGatewayNetwork" BO_ 76 "HS2_CAN";
BA_ "FrameGatewayId" BO_ 76 76;
BA_ "GenMsgDelayTime" BO_ 76 10;
BA_ "FrameRouting" BO_ 1034 "HS1_CAN,0x40A;";
BA_ "FrameGatewayNetwork" BO_ 1034 "HS1_CAN";
BA_ "FrameGatewayId" BO_ 1034 1034;
BA_ "FrameRouting" BO_ 1069 "FD1_CAN,0x42D;HS1_CAN,0x42D";
BA_ "FrameGatewayNetwork" BO_ 1069 "FD1_CAN";
BA_ "FrameGatewayId" BO_ 1069 1069;
BA_ "FrameRouting" BO_ 1057 "FD1_CAN,0x421;HS1_CAN,0x421";
BA_ "FrameGatewayNetwork" BO_ 1057 "FD1_CAN";
BA_ "FrameGatewayId" BO_ 1057 1057;
BA_ "FrameRouting" BO_ 516 "FD1_CAN,0x204;HS1_CAN,0x204";
BA_ "FrameGatewayNetwork" BO_ 516 "FD1_CAN";
BA_ "FrameGatewayId" BO_ 516 516;
BA_ "GenMsgDelayTime" BO_ 516 0;
BA_ "FrameRouting" BO_ 514 "FD1_CAN,0x202;HS1_CAN,0x202";
BA_ "FrameGatewayNetwork" BO_ 514 "FD1_CAN";
BA_ "FrameGatewayId" BO_ 514 514;
BA_ "GenMsgDelayTime" BO_ 514 10;
BA_ "FrameRouting" BO_ 381 "FD1_CAN,0x17D;";
BA_ "FrameGatewayNetwork" BO_ 381 "FD1_CAN";
BA_ "FrameGatewayId" BO_ 381 381;
BA_ "FrameRouting" BO_ 380 "FD1_CAN,0x17C;";
BA_ "FrameGatewayNetwork" BO_ 380 "FD1_CAN";
BA_ "FrameGatewayId" BO_ 380 380;
BA_ "FrameRouting" BO_ 377 "FD1_CAN,0x179;HS1_CAN,0x179";
BA_ "FrameGatewayNetwork" BO_ 377 "FD1_CAN";
BA_ "FrameGatewayId" BO_ 377 377;
BA_ "FrameRouting" BO_ 376 "FD1_CAN,0x178;HS1_CAN,0x178";
BA_ "FrameGatewayNetwork" BO_ 376 "FD1_CAN";
BA_ "FrameGatewayId" BO_ 376 376;
BA_ "FrameRouting" BO_ 373 "FD1_CAN,0x175;";
BA_ "FrameGatewayNetwork" BO_ 373 "FD1_CAN";
BA_ "FrameGatewayId" BO_ 373 373;
BA_ "GenMsgDelayTime" BO_ 373 10;
BA_ "FrameRouting" BO_ 355 "FD1_CAN,0x163;";
BA_ "FrameGatewayNetwork" BO_ 355 "FD1_CAN";
BA_ "FrameGatewayId" BO_ 355 355;
BA_ "FrameRouting" BO_ 342 "FD1_CAN,0x156;HS1_CAN,0x156";
BA_ "FrameGatewayNetwork" BO_ 342 "FD1_CAN";
BA_ "FrameGatewayId" BO_ 342 342;
BA_ "GenMsgSendType" BO_ 530 1;
BA_ "FrameRouting" BO_ 897 "FD1_CAN,0x381;";
BA_ "FrameGatewayNetwork" BO_ 897 "FD1_CAN";
BA_ "FrameGatewayId" BO_ 897 897;
BA_ "TpTxIndex" BO_ 707 23;
BA_ "FrameRouting" BO_ 1102 "FD1_CAN,0x44E;HS1_CAN,0x44E";
BA_ "FrameGatewayNetwork" BO_ 1102 "FD1_CAN";
BA_ "FrameGatewayId" BO_ 1102 1102;
BA_ "GenMsgCycleTime" BO_ 551 1000;
BA_ "GenMsgSendType" BO_ 551 5;
BA_ "FrameRouting" BO_ 673 "HS2_CAN,0x2A1;";
BA_ "FrameGatewayNetwork" BO_ 673 "HS2_CAN";
BA_ "FrameGatewayId" BO_ 673 673;
BA_ "FrameRouting" BO_ 963 "HS1_CAN,0x3C3;";
BA_ "FrameGatewayNetwork" BO_ 963 "HS1_CAN";
BA_ "FrameGatewayId" BO_ 963 963;
BA_ "FrameRouting" BO_ 949 "HS1_CAN,0x3B5;";
BA_ "FrameGatewayNetwork" BO_ 949 "HS1_CAN";
BA_ "FrameGatewayId" BO_ 949 949;
BA_ "NetworkInitialization" BO_ 2015 0;
BA_ "GenMsgDelayTime" BO_ 2015 0;
BA_ "GenMsgSendType" BO_ 2015 1;
BA_ "DiagState" BO_ 2015 1;
BA_ "GenMsgILSupport" BO_ 2015 0;
BA_ "GenMsgCycleTime" BO_ 1076 100;
BA_ "GenMsgSendType" BO_ 1076 5;
BA_ "TpTxIndex" BO_ 709 25;
BA_ "GenMsgCycleTime" BO_ 552 1000;
BA_ "GenMsgSendType" BO_ 552 5;
BA_ "FrameRouting" BO_ 967 "HS1_CAN,0x3C7;";
BA_ "FrameGatewayNetwork" BO_ 967 "HS1_CAN";
BA_ "FrameGatewayId" BO_ 967 967;
BA_ "U_U55X_MY2022_Tx" SG_ 729 ACU_VoiceFBVolume_Up 1;
BA_ "U_CD542_MY2021_Tx" SG_ 729 ACU_VoiceFBVolume_Up 1;
BA_ "U_T6_MCA_MY2020_Tx" SG_ 729 ACU_VoiceFBVolume_Up 1;
BA_ "U_P702_MY2021_Tx" SG_ 729 ACU_VoiceFBVolume_Up 1;
BA_ "U_P702_MY2021_Rx" SG_ 729 ACU_VoiceFBVolume_Up 1;
BA_ "U_U55X_MY2022_Rx" SG_ 729 ACU_VoiceFBVolume_Up 1;
BA_ "U_CD542_MY2021_Rx" SG_ 729 ACU_VoiceFBVolume_Up 1;
BA_ "U_T6_MCA_MY2020_Rx" SG_ 729 ACU_VoiceFBVolume_Up 1;
BA_ "GenSigSendType" SG_ 729 ACU_VoiceFBVolume_Up 3;
BA_ "U_U55X_MY2022_Tx" SG_ 729 ACU_VoiceFBVolume_St 1;
BA_ "U_CD542_MY2021_Tx" SG_ 729 ACU_VoiceFBVolume_St 1;
BA_ "U_T6_MCA_MY2020_Tx" SG_ 729 ACU_VoiceFBVolume_St 1;
BA_ "U_P702_MY2021_Tx" SG_ 729 ACU_VoiceFBVolume_St 1;
BA_ "U_P702_MY2021_Rx" SG_ 729 ACU_VoiceFBVolume_St 1;
BA_ "U_U55X_MY2022_Rx" SG_ 729 ACU_VoiceFBVolume_St 1;
BA_ "U_CD542_MY2021_Rx" SG_ 729 ACU_VoiceFBVolume_St 1;
BA_ "U_T6_MCA_MY2020_Rx" SG_ 729 ACU_VoiceFBVolume_St 1;
BA_ "GenSigSendType" SG_ 729 ACU_VoiceFBVolume_St 3;
BA_ "U_U55X_MY2022_Tx" SG_ 729 ACU_Treble_St 1;
BA_ "U_CD542_MY2021_Tx" SG_ 729 ACU_Treble_St 1;
BA_ "U_T6_MCA_MY2020_Tx" SG_ 729 ACU_Treble_St 1;
BA_ "U_P702_MY2021_Tx" SG_ 729 ACU_Treble_St 1;
BA_ "U_P702_MY2021_Rx" SG_ 729 ACU_Treble_St 1;
BA_ "U_U55X_MY2022_Rx" SG_ 729 ACU_Treble_St 1;
BA_ "U_CD542_MY2021_Rx" SG_ 729 ACU_Treble_St 1;
BA_ "U_T6_MCA_MY2020_Rx" SG_ 729 ACU_Treble_St 1;
BA_ "GenSigSendType" SG_ 729 ACU_Treble_St 3;
BA_ "U_U55X_MY2022_Tx" SG_ 729 ACU_TAVolume_Up 1;
BA_ "U_CD542_MY2021_Tx" SG_ 729 ACU_TAVolume_Up 1;
BA_ "U_T6_MCA_MY2020_Tx" SG_ 729 ACU_TAVolume_Up 1;
BA_ "U_P702_MY2021_Tx" SG_ 729 ACU_TAVolume_Up 1;
BA_ "U_P702_MY2021_Rx" SG_ 729 ACU_TAVolume_Up 1;
BA_ "U_U55X_MY2022_Rx" SG_ 729 ACU_TAVolume_Up 1;
BA_ "U_CD542_MY2021_Rx" SG_ 729 ACU_TAVolume_Up 1;
BA_ "U_T6_MCA_MY2020_Rx" SG_ 729 ACU_TAVolume_Up 1;
BA_ "GenSigSendType" SG_ 729 ACU_TAVolume_Up 3;
BA_ "U_U55X_MY2022_Tx" SG_ 729 ACU_TAVolume_St 1;
BA_ "U_CD542_MY2021_Tx" SG_ 729 ACU_TAVolume_St 1;
BA_ "U_T6_MCA_MY2020_Tx" SG_ 729 ACU_TAVolume_St 1;
BA_ "U_P702_MY2021_Tx" SG_ 729 ACU_TAVolume_St 1;
BA_ "U_P702_MY2021_Rx" SG_ 729 ACU_TAVolume_St 1;
BA_ "U_U55X_MY2022_Rx" SG_ 729 ACU_TAVolume_St 1;
BA_ "U_CD542_MY2021_Rx" SG_ 729 ACU_TAVolume_St 1;
BA_ "U_T6_MCA_MY2020_Rx" SG_ 729 ACU_TAVolume_St 1;
BA_ "GenSigSendType" SG_ 729 ACU_TAVolume_St 3;
BA_ "U_U55X_MY2022_Tx" SG_ 729 ACU_Reg_St 1;
BA_ "U_CD542_MY2021_Tx" SG_ 729 ACU_Reg_St 1;
BA_ "U_T6_MCA_MY2020_Tx" SG_ 729 ACU_Reg_St 1;
BA_ "U_P702_MY2021_Tx" SG_ 729 ACU_Reg_St 1;
BA_ "U_U55X_MY2022_Rx" SG_ 729 ACU_Reg_St 1;
BA_ "U_CD542_MY2021_Rx" SG_ 729 ACU_Reg_St 1;
BA_ "U_T6_MCA_MY2020_Rx" SG_ 729 ACU_Reg_St 1;
BA_ "U_P702_MY2021_Rx" SG_ 729 ACU_Reg_St 1;
BA_ "GenSigSendType" SG_ 729 ACU_Reg_St 3;
BA_ "U_U55X_MY2022_Tx" SG_ 729 ACU_PhoneVolume_Up 1;
BA_ "U_CD542_MY2021_Tx" SG_ 729 ACU_PhoneVolume_Up 1;
BA_ "U_T6_MCA_MY2020_Tx" SG_ 729 ACU_PhoneVolume_Up 1;
BA_ "U_P702_MY2021_Tx" SG_ 729 ACU_PhoneVolume_Up 1;
BA_ "U_P702_MY2021_Rx" SG_ 729 ACU_PhoneVolume_Up 1;
BA_ "U_U55X_MY2022_Rx" SG_ 729 ACU_PhoneVolume_Up 1;
BA_ "U_CD542_MY2021_Rx" SG_ 729 ACU_PhoneVolume_Up 1;
BA_ "U_T6_MCA_MY2020_Rx" SG_ 729 ACU_PhoneVolume_Up 1;
BA_ "GenSigSendType" SG_ 729 ACU_PhoneVolume_Up 3;
BA_ "U_U55X_MY2022_Tx" SG_ 729 ACU_PhoneVolume_St 1;
BA_ "U_CD542_MY2021_Tx" SG_ 729 ACU_PhoneVolume_St 1;
BA_ "U_T6_MCA_MY2020_Tx" SG_ 729 ACU_PhoneVolume_St 1;
BA_ "U_P702_MY2021_Tx" SG_ 729 ACU_PhoneVolume_St 1;
BA_ "U_P702_MY2021_Rx" SG_ 729 ACU_PhoneVolume_St 1;
BA_ "U_U55X_MY2022_Rx" SG_ 729 ACU_PhoneVolume_St 1;
BA_ "U_CD542_MY2021_Rx" SG_ 729 ACU_PhoneVolume_St 1;
BA_ "U_T6_MCA_MY2020_Rx" SG_ 729 ACU_PhoneVolume_St 1;
BA_ "GenSigSendType" SG_ 729 ACU_PhoneVolume_St 3;
BA_ "U_U55X_MY2022_Tx" SG_ 729 ACU_NavCmdVolume_Up 1;
BA_ "U_CD542_MY2021_Tx" SG_ 729 ACU_NavCmdVolume_Up 1;
BA_ "U_T6_MCA_MY2020_Tx" SG_ 729 ACU_NavCmdVolume_Up 1;
BA_ "U_P702_MY2021_Tx" SG_ 729 ACU_NavCmdVolume_Up 1;
BA_ "U_P702_MY2021_Rx" SG_ 729 ACU_NavCmdVolume_Up 1;
BA_ "U_U55X_MY2022_Rx" SG_ 729 ACU_NavCmdVolume_Up 1;
BA_ "U_CD542_MY2021_Rx" SG_ 729 ACU_NavCmdVolume_Up 1;
BA_ "U_T6_MCA_MY2020_Rx" SG_ 729 ACU_NavCmdVolume_Up 1;
BA_ "GenSigSendType" SG_ 729 ACU_NavCmdVolume_Up 3;
BA_ "U_U55X_MY2022_Tx" SG_ 729 ACU_NavCmdVolume_St 1;
BA_ "U_CD542_MY2021_Tx" SG_ 729 ACU_NavCmdVolume_St 1;
BA_ "U_T6_MCA_MY2020_Tx" SG_ 729 ACU_NavCmdVolume_St 1;
BA_ "U_P702_MY2021_Tx" SG_ 729 ACU_NavCmdVolume_St 1;
BA_ "U_P702_MY2021_Rx" SG_ 729 ACU_NavCmdVolume_St 1;
BA_ "U_U55X_MY2022_Rx" SG_ 729 ACU_NavCmdVolume_St 1;
BA_ "U_CD542_MY2021_Rx" SG_ 729 ACU_NavCmdVolume_St 1;
BA_ "U_T6_MCA_MY2020_Rx" SG_ 729 ACU_NavCmdVolume_St 1;
BA_ "GenSigSendType" SG_ 729 ACU_NavCmdVolume_St 3;
BA_ "U_U55X_MY2022_Tx" SG_ 729 ACU_Fader_St 1;
BA_ "U_CD542_MY2021_Tx" SG_ 729 ACU_Fader_St 1;
BA_ "U_T6_MCA_MY2020_Tx" SG_ 729 ACU_Fader_St 1;
BA_ "U_P702_MY2021_Tx" SG_ 729 ACU_Fader_St 1;
BA_ "U_P702_MY2021_Rx" SG_ 729 ACU_Fader_St 1;
BA_ "U_U55X_MY2022_Rx" SG_ 729 ACU_Fader_St 1;
BA_ "U_CD542_MY2021_Rx" SG_ 729 ACU_Fader_St 1;
BA_ "U_T6_MCA_MY2020_Rx" SG_ 729 ACU_Fader_St 1;
BA_ "GenSigSendType" SG_ 729 ACU_Fader_St 3;
BA_ "U_U55X_MY2022_Tx" SG_ 729 ACU_DSPProgram_St 1;
BA_ "U_CD542_MY2021_Tx" SG_ 729 ACU_DSPProgram_St 1;
BA_ "U_T6_MCA_MY2020_Tx" SG_ 729 ACU_DSPProgram_St 1;
BA_ "U_P702_MY2021_Tx" SG_ 729 ACU_DSPProgram_St 1;
BA_ "U_U55X_MY2022_Rx" SG_ 729 ACU_DSPProgram_St 1;
BA_ "U_CD542_MY2021_Rx" SG_ 729 ACU_DSPProgram_St 1;
BA_ "U_T6_MCA_MY2020_Rx" SG_ 729 ACU_DSPProgram_St 1;
BA_ "U_P702_MY2021_Rx" SG_ 729 ACU_DSPProgram_St 1;
BA_ "GenSigSendType" SG_ 729 ACU_DSPProgram_St 3;
BA_ "U_U55X_MY2022_Tx" SG_ 729 ACU_DSP_St 1;
BA_ "U_CD542_MY2021_Tx" SG_ 729 ACU_DSP_St 1;
BA_ "U_T6_MCA_MY2020_Tx" SG_ 729 ACU_DSP_St 1;
BA_ "U_P702_MY2021_Tx" SG_ 729 ACU_DSP_St 1;
BA_ "U_U55X_MY2022_Rx" SG_ 729 ACU_DSP_St 1;
BA_ "U_CD542_MY2021_Rx" SG_ 729 ACU_DSP_St 1;
BA_ "U_T6_MCA_MY2020_Rx" SG_ 729 ACU_DSP_St 1;
BA_ "U_P702_MY2021_Rx" SG_ 729 ACU_DSP_St 1;
BA_ "GenSigSendType" SG_ 729 ACU_DSP_St 3;
BA_ "U_U55X_MY2022_Tx" SG_ 729 ACU_Bass_St 1;
BA_ "U_CD542_MY2021_Tx" SG_ 729 ACU_Bass_St 1;
BA_ "U_T6_MCA_MY2020_Tx" SG_ 729 ACU_Bass_St 1;
BA_ "U_P702_MY2021_Tx" SG_ 729 ACU_Bass_St 1;
BA_ "U_U55X_MY2022_Rx" SG_ 729 ACU_Bass_St 1;
BA_ "U_CD542_MY2021_Rx" SG_ 729 ACU_Bass_St 1;
BA_ "U_T6_MCA_MY2020_Rx" SG_ 729 ACU_Bass_St 1;
BA_ "U_P702_MY2021_Rx" SG_ 729 ACU_Bass_St 1;
BA_ "GenSigSendType" SG_ 729 ACU_Bass_St 3;
BA_ "U_U55X_MY2022_Tx" SG_ 729 ACU_Balance_St 1;
BA_ "U_CD542_MY2021_Tx" SG_ 729 ACU_Balance_St 1;
BA_ "U_T6_MCA_MY2020_Tx" SG_ 729 ACU_Balance_St 1;
BA_ "U_P702_MY2021_Tx" SG_ 729 ACU_Balance_St 1;
BA_ "U_U55X_MY2022_Rx" SG_ 729 ACU_Balance_St 1;
BA_ "U_CD542_MY2021_Rx" SG_ 729 ACU_Balance_St 1;
BA_ "U_T6_MCA_MY2020_Rx" SG_ 729 ACU_Balance_St 1;
BA_ "U_P702_MY2021_Rx" SG_ 729 ACU_Balance_St 1;
BA_ "GenSigSendType" SG_ 729 ACU_Balance_St 3;
BA_ "U_U55X_MY2022_Tx" SG_ 729 ACU_AVC_St 1;
BA_ "U_CD542_MY2021_Tx" SG_ 729 ACU_AVC_St 1;
BA_ "U_T6_MCA_MY2020_Tx" SG_ 729 ACU_AVC_St 1;
BA_ "U_P702_MY2021_Tx" SG_ 729 ACU_AVC_St 1;
BA_ "U_U55X_MY2022_Rx" SG_ 729 ACU_AVC_St 1;
BA_ "U_CD542_MY2021_Rx" SG_ 729 ACU_AVC_St 1;
BA_ "U_T6_MCA_MY2020_Rx" SG_ 729 ACU_AVC_St 1;
BA_ "U_P702_MY2021_Rx" SG_ 729 ACU_AVC_St 1;
BA_ "GenSigSendType" SG_ 729 ACU_AVC_St 3;
BA_ "U_U55X_MY2022_Tx" SG_ 727 ACU_LoadEjectMode_St 1;
BA_ "U_CD542_MY2021_Tx" SG_ 727 ACU_LoadEjectMode_St 1;
BA_ "U_T6_MCA_MY2020_Tx" SG_ 727 ACU_LoadEjectMode_St 1;
BA_ "U_P702_MY2021_Tx" SG_ 727 ACU_LoadEjectMode_St 1;
BA_ "U_U55X_MY2022_Rx" SG_ 727 ACU_LoadEjectMode_St 1;
BA_ "U_CD542_MY2021_Rx" SG_ 727 ACU_LoadEjectMode_St 1;
BA_ "U_T6_MCA_MY2020_Rx" SG_ 727 ACU_LoadEjectMode_St 1;
BA_ "U_P702_MY2021_Rx" SG_ 727 ACU_LoadEjectMode_St 1;
BA_ "GenSigSendType" SG_ 727 ACU_LoadEjectMode_St 3;
BA_ "U_U55X_MY2022_Tx" SG_ 727 ACU_LoadEjectDisc_St 1;
BA_ "U_CD542_MY2021_Tx" SG_ 727 ACU_LoadEjectDisc_St 1;
BA_ "U_T6_MCA_MY2020_Tx" SG_ 727 ACU_LoadEjectDisc_St 1;
BA_ "U_P702_MY2021_Tx" SG_ 727 ACU_LoadEjectDisc_St 1;
BA_ "U_U55X_MY2022_Rx" SG_ 727 ACU_LoadEjectDisc_St 1;
BA_ "U_CD542_MY2021_Rx" SG_ 727 ACU_LoadEjectDisc_St 1;
BA_ "U_T6_MCA_MY2020_Rx" SG_ 727 ACU_LoadEjectDisc_St 1;
BA_ "U_P702_MY2021_Rx" SG_ 727 ACU_LoadEjectDisc_St 1;
BA_ "U_U55X_MY2022_Tx" SG_ 726 ACU_SelectedPTYCodes_St 1;
BA_ "U_CD542_MY2021_Tx" SG_ 726 ACU_SelectedPTYCodes_St 1;
BA_ "U_T6_MCA_MY2020_Tx" SG_ 726 ACU_SelectedPTYCodes_St 1;
BA_ "U_P702_MY2021_Tx" SG_ 726 ACU_SelectedPTYCodes_St 1;
BA_ "U_U55X_MY2022_Rx" SG_ 726 ACU_SelectedPTYCodes_St 1;
BA_ "U_CD542_MY2021_Rx" SG_ 726 ACU_SelectedPTYCodes_St 1;
BA_ "U_T6_MCA_MY2020_Rx" SG_ 726 ACU_SelectedPTYCodes_St 1;
BA_ "U_P702_MY2021_Rx" SG_ 726 ACU_SelectedPTYCodes_St 1;
BA_ "GenSigSendType" SG_ 726 ACU_SelectedPTYCodes_St 3;
BA_ "U_U55X_MY2022_Tx" SG_ 726 ACU_TAMode_St 1;
BA_ "U_CD542_MY2021_Tx" SG_ 726 ACU_TAMode_St 1;
BA_ "U_T6_MCA_MY2020_Tx" SG_ 726 ACU_TAMode_St 1;
BA_ "U_P702_MY2021_Tx" SG_ 726 ACU_TAMode_St 1;
BA_ "U_U55X_MY2022_Rx" SG_ 726 ACU_TAMode_St 1;
BA_ "U_CD542_MY2021_Rx" SG_ 726 ACU_TAMode_St 1;
BA_ "U_T6_MCA_MY2020_Rx" SG_ 726 ACU_TAMode_St 1;
BA_ "U_P702_MY2021_Rx" SG_ 726 ACU_TAMode_St 1;
BA_ "GenSigSendType" SG_ 726 ACU_TAMode_St 3;
BA_ "U_U55X_MY2022_Tx" SG_ 726 ACU_NEWSMode_St 1;
BA_ "U_CD542_MY2021_Tx" SG_ 726 ACU_NEWSMode_St 1;
BA_ "U_T6_MCA_MY2020_Tx" SG_ 726 ACU_NEWSMode_St 1;
BA_ "U_P702_MY2021_Tx" SG_ 726 ACU_NEWSMode_St 1;
BA_ "U_U55X_MY2022_Rx" SG_ 726 ACU_NEWSMode_St 1;
BA_ "U_CD542_MY2021_Rx" SG_ 726 ACU_NEWSMode_St 1;
BA_ "U_T6_MCA_MY2020_Rx" SG_ 726 ACU_NEWSMode_St 1;
BA_ "U_P702_MY2021_Rx" SG_ 726 ACU_NEWSMode_St 1;
BA_ "GenSigSendType" SG_ 726 ACU_NEWSMode_St 3;
BA_ "U_U55X_MY2022_Tx" SG_ 726 ACU_AFJump_St 1;
BA_ "U_CD542_MY2021_Tx" SG_ 726 ACU_AFJump_St 1;
BA_ "U_T6_MCA_MY2020_Tx" SG_ 726 ACU_AFJump_St 1;
BA_ "U_P702_MY2021_Tx" SG_ 726 ACU_AFJump_St 1;
BA_ "U_U55X_MY2022_Rx" SG_ 726 ACU_AFJump_St 1;
BA_ "U_CD542_MY2021_Rx" SG_ 726 ACU_AFJump_St 1;
BA_ "U_T6_MCA_MY2020_Rx" SG_ 726 ACU_AFJump_St 1;
BA_ "U_P702_MY2021_Rx" SG_ 726 ACU_AFJump_St 1;
BA_ "GenSigSendType" SG_ 726 ACU_AFJump_St 3;
BA_ "U_CD542_MY2021_Rx" SG_ 369 SeatWorkSrfc_B_Falt 1;
BA_ "GenSigStartValue" SG_ 369 PrplWhlScnd_Tq_Cmd 2048;
BA_ "GenSigStartValueInteger" SG_ 369 PrplWhlScnd_Tq_Cmd 4;
BA_ "GenSigStartValue" SG_ 369 PrplWhlPrim_Tq_Cmd 2048;
BA_ "GenSigStartValueInteger" SG_ 369 PrplWhlPrim_Tq_Cmd 4;
BA_ "U_U55X_MY2022_Rx" SG_ 369 TrnIpcDsplyRng_D_Stat 1;
BA_ "U_CD542_MY2021_Rx" SG_ 369 TrnIpcDsplyRng_D_Stat 1;
BA_ "U_T6_MCA_MY2020_Rx" SG_ 369 TrnIpcDsplyRng_D_Stat 1;
BA_ "U_P702_MY2021_Rx" SG_ 369 TrnIpcDsplyRng_D_Stat 1;
BA_ "U_U55X_MY2022_Rx" SG_ 369 TrnIpcDsplyGear_D_Actl 1;
BA_ "U_CD542_MY2021_Rx" SG_ 369 TrnIpcDsplyGear_D_Actl 1;
BA_ "U_T6_MCA_MY2020_Rx" SG_ 369 TrnIpcDsplyGear_D_Actl 1;
BA_ "U_P702_MY2021_Rx" SG_ 369 TrnIpcDsplyGear_D_Actl 1;
BA_ "GenSigStartValue" SG_ 369 TrnIpcDsplyGear_D_Actl 15;
BA_ "GenSigStartValueInteger" SG_ 369 TrnIpcDsplyGear_D_Actl 15;
BA_ "U_U55X_MY2022_Rx" SG_ 369 TrnIpcDsplyMde_D_Stat 1;
BA_ "U_CD542_MY2021_Rx" SG_ 369 TrnIpcDsplyMde_D_Stat 1;
BA_ "U_T6_MCA_MY2020_Rx" SG_ 369 TrnIpcDsplyMde_D_Stat 1;
BA_ "U_P702_MY2021_Rx" SG_ 369 TrnIpcDsplyMde_D_Stat 1;
BA_ "WakeupSignal" SG_ 369 TrnIpcDsplyMde_D_Stat 1;
BA_ "U_U55X_MY2022_Rx" SG_ 369 TrnIpcDsplyMde_D_Actl 1;
BA_ "U_CD542_MY2021_Rx" SG_ 369 TrnIpcDsplyMde_D_Actl 1;
BA_ "U_T6_MCA_MY2020_Rx" SG_ 369 TrnIpcDsplyMde_D_Actl 1;
BA_ "U_P702_MY2021_Rx" SG_ 369 TrnIpcDsplyMde_D_Actl 1;
BA_ "WakeupSignal" SG_ 369 TrnIpcDsplyMde_D_Actl 1;
BA_ "U_U55X_MY2022_Rx" SG_ 369 TrnIpcDsplyGear_D_Stat 1;
BA_ "U_CD542_MY2021_Rx" SG_ 369 TrnIpcDsplyGear_D_Stat 1;
BA_ "U_T6_MCA_MY2020_Rx" SG_ 369 TrnIpcDsplyGear_D_Stat 1;
BA_ "U_P702_MY2021_Rx" SG_ 369 TrnIpcDsplyGear_D_Stat 1;
BA_ "U_U55X_MY2022_Rx" SG_ 369 TrnIpcDsplyRng2_D_Actl 1;
BA_ "U_CD542_MY2021_Rx" SG_ 369 TrnIpcDsplyRng2_D_Actl 1;
BA_ "U_T6_MCA_MY2020_Rx" SG_ 369 TrnIpcDsplyRng2_D_Actl 1;
BA_ "U_P702_MY2021_Rx" SG_ 369 TrnIpcDsplyRng2_D_Actl 1;
BA_ "GenSigStartValue" SG_ 369 TrnIpcDsplyRng2_D_Actl 15;
BA_ "GenSigStartValueInteger" SG_ 369 TrnIpcDsplyRng2_D_Actl 15;
BA_ "U_U55X_MY2022_Tx" SG_ 1832 TesterPhysicalResIPC 1;
BA_ "U_CD542_MY2021_Tx" SG_ 1832 TesterPhysicalResIPC 1;
BA_ "U_T6_MCA_MY2020_Tx" SG_ 1832 TesterPhysicalResIPC 1;
BA_ "U_P702_MY2021_Tx" SG_ 1832 TesterPhysicalResIPC 1;
BA_ "GenSigSendType" SG_ 1832 TesterPhysicalResIPC 3;
BA_ "U_CD542_MY2021_Rx" SG_ 1071 CluPdl_PcRate_Actl 1;
BA_ "U_T6_MCA_MY2020_Rx" SG_ 1071 CluPdl_PcRate_Actl 1;
BA_ "ContentDependant" SG_ 1071 CluPdl_PcRate_Actl 1;
BA_ "U_CD542_MY2021_Rx" SG_ 1071 CluPdlPosPcMeas_D_Qf 1;
BA_ "U_T6_MCA_MY2020_Rx" SG_ 1071 CluPdlPosPcMeas_D_Qf 1;
BA_ "GenSigStartValue" SG_ 1071 CluPdlPosPcMeas_D_Qf 1;
BA_ "MetaData" SG_ 1071 CluPdlPosPcMeas_D_Qf 1;
BA_ "ContentDependant" SG_ 1071 CluPdlPosPcMeas_D_Qf 1;
BA_ "GenSigStartValueInteger" SG_ 1071 CluPdlPosPcMeas_D_Qf 1;
BA_ "GenSigStartValue" SG_ 1071 EngMnfld3_P_Actl 254;
BA_ "GenSigStartValueInteger" SG_ 1071 EngMnfld3_P_Actl 254;
BA_ "U_U55X_MY2022_Rx" SG_ 1071 EngAout_N_Dsply 1;
BA_ "U_CD542_MY2021_Rx" SG_ 1071 EngAout_N_Dsply 1;
BA_ "U_T6_MCA_MY2020_Rx" SG_ 1071 EngAout_N_Dsply 1;
BA_ "U_P702_MY2021_Rx" SG_ 1071 EngAout_N_Dsply 1;
BA_ "U_CD542_MY2021_Rx" SG_ 1071 CluPdlPos_Pc_Meas 1;
BA_ "U_T6_MCA_MY2020_Rx" SG_ 1071 CluPdlPos_Pc_Meas 1;
BA_ "ContentDependant" SG_ 1071 CluPdlPos_Pc_Meas 1;
BA_ "ContentDependant" SG_ 1071 EngAoutIdl_N_Ntrl 1;
BA_ "U_U55X_MY2022_Tx" SG_ 848 RILStat 1;
BA_ "U_CD542_MY2021_Tx" SG_ 848 RILStat 1;
BA_ "U_T6_MCA_MY2020_Tx" SG_ 848 RILStat 1;
BA_ "U_P702_MY2021_Tx" SG_ 848 RILStat 1;
BA_ "U_U55X_MY2022_Rx" SG_ 610 AwdLckWhlRr_Pc_RqDsply 1;
BA_ "U_T6_MCA_MY2020_Rx" SG_ 610 AwdLckWhlRr_Pc_RqDsply 1;
BA_ "U_U55X_MY2022_Rx" SG_ 610 AwdLckWhlRl_Pc_RqDsply 1;
BA_ "U_T6_MCA_MY2020_Rx" SG_ 610 AwdLckWhlRl_Pc_RqDsply 1;
BA_ "U_U55X_MY2022_Rx" SG_ 610 AwdLckWhlFr_Pc_RqDsply 1;
BA_ "U_T6_MCA_MY2020_Rx" SG_ 610 AwdLckWhlFr_Pc_RqDsply 1;
BA_ "U_U55X_MY2022_Rx" SG_ 610 AwdLckWhlFl_Pc_RqDsply 1;
BA_ "U_T6_MCA_MY2020_Rx" SG_ 610 AwdLckWhlFl_Pc_RqDsply 1;
BA_ "U_T6_MCA_MY2020_Rx" SG_ 839 FohStop_B_Stat 1;
BA_ "GenSigStartValue" SG_ 839 FohStop_B_Stat 3;
BA_ "ContentDependant" SG_ 839 FohStop_B_Stat 1;
BA_ "GenSigStartValueInteger" SG_ 839 FohStop_B_Stat 3;
BA_ "WakeupSignal" SG_ 839 FohStop_B_Stat 1;
BA_ "U_T6_MCA_MY2020_Rx" SG_ 839 FohMsgTxt_D_Rq 1;
BA_ "ContentDependant" SG_ 839 FohMsgTxt_D_Rq 1;
BA_ "U_T6_MCA_MY2020_Rx" SG_ 839 FohKeyOff_B_Rq 1;
BA_ "ContentDependant" SG_ 839 FohKeyOff_B_Rq 1;
BA_ "WakeupSignal" SG_ 839 FohKeyOff_B_Rq 1;
BA_ "U_T6_MCA_MY2020_Rx" SG_ 839 FohEnbl_B_Rq 1;
BA_ "ContentDependant" SG_ 839 FohEnbl_B_Rq 1;
BA_ "WakeupSignal" SG_ 839 FohEnbl_B_Rq 1;
BA_ "U_T6_MCA_MY2020_Rx" SG_ 839 FohTAllEnable_B_Stat 1;
BA_ "GenSigStartValue" SG_ 839 FohTAllEnable_B_Stat 3;
BA_ "ContentDependant" SG_ 839 FohTAllEnable_B_Stat 1;
BA_ "GenSigStartValueInteger" SG_ 839 FohTAllEnable_B_Stat 3;
BA_ "U_T6_MCA_MY2020_Rx" SG_ 839 FohT2Mnte_T_Stat 1;
BA_ "ContentDependant" SG_ 839 FohT2Mnte_T_Stat 1;
BA_ "U_T6_MCA_MY2020_Rx" SG_ 839 FohT2Hr_T_Stat 1;
BA_ "ContentDependant" SG_ 839 FohT2Hr_T_Stat 1;
BA_ "U_T6_MCA_MY2020_Rx" SG_ 839 FohT2Enable_B_Stat 1;
BA_ "ContentDependant" SG_ 839 FohT2Enable_B_Stat 1;
BA_ "U_T6_MCA_MY2020_Rx" SG_ 839 FohT1Mnte_T_Stat 1;
BA_ "ContentDependant" SG_ 839 FohT1Mnte_T_Stat 1;
BA_ "U_T6_MCA_MY2020_Rx" SG_ 839 FohT1Hr_T_Stat 1;
BA_ "ContentDependant" SG_ 839 FohT1Hr_T_Stat 1;
BA_ "U_T6_MCA_MY2020_Rx" SG_ 839 FohT1Enable_B_Stat 1;
BA_ "ContentDependant" SG_ 839 FohT1Enable_B_Stat 1;
BA_ "U_T6_MCA_MY2020_Rx" SG_ 839 FohStrtMnte_T_Stat 1;
BA_ "ContentDependant" SG_ 839 FohStrtMnte_T_Stat 1;
BA_ "U_T6_MCA_MY2020_Rx" SG_ 839 FohStrtHr_T_Stat 1;
BA_ "ContentDependant" SG_ 839 FohStrtHr_T_Stat 1;
BA_ "ContentDependant" SG_ 839 FohStrtEnable_B_Stat 1;
BA_ "U_T6_MCA_MY2020_Rx" SG_ 839 FohContOn_B_Stat 1;
BA_ "GenSigStartValue" SG_ 839 FohContOn_B_Stat 3;
BA_ "ContentDependant" SG_ 839 FohContOn_B_Stat 1;
BA_ "GenSigStartValueInteger" SG_ 839 FohContOn_B_Stat 3;
BA_ "ContentDependant" SG_ 839 FohStrtDay_T_Stat 1;
BA_ "U_T6_MCA_MY2020_Rx" SG_ 839 FohT2Wednesday_T_Stat 1;
BA_ "ContentDependant" SG_ 839 FohT2Wednesday_T_Stat 1;
BA_ "U_T6_MCA_MY2020_Rx" SG_ 839 FohT2Tuesday_T_Stat 1;
BA_ "ContentDependant" SG_ 839 FohT2Tuesday_T_Stat 1;
BA_ "U_T6_MCA_MY2020_Rx" SG_ 839 FohT2Thursday_T_Stat 1;
BA_ "ContentDependant" SG_ 839 FohT2Thursday_T_Stat 1;
BA_ "U_T6_MCA_MY2020_Rx" SG_ 839 FohT2Sunday_T_Stat 1;
BA_ "ContentDependant" SG_ 839 FohT2Sunday_T_Stat 1;
BA_ "U_T6_MCA_MY2020_Rx" SG_ 839 FohT2Saturday_T_Stat 1;
BA_ "ContentDependant" SG_ 839 FohT2Saturday_T_Stat 1;
BA_ "U_T6_MCA_MY2020_Rx" SG_ 839 FohT2Monday_T_Stat 1;
BA_ "ContentDependant" SG_ 839 FohT2Monday_T_Stat 1;
BA_ "U_T6_MCA_MY2020_Rx" SG_ 839 FohT2Friday_T_Stat 1;
BA_ "ContentDependant" SG_ 839 FohT2Friday_T_Stat 1;
BA_ "U_T6_MCA_MY2020_Rx" SG_ 839 FohT1Wednesday_T_Stat 1;
BA_ "ContentDependant" SG_ 839 FohT1Wednesday_T_Stat 1;
BA_ "U_T6_MCA_MY2020_Rx" SG_ 839 FohT1Tuesday_T_Stat 1;
BA_ "ContentDependant" SG_ 839 FohT1Tuesday_T_Stat 1;
BA_ "U_T6_MCA_MY2020_Rx" SG_ 839 FohT1Thursday_T_Stat 1;
BA_ "ContentDependant" SG_ 839 FohT1Thursday_T_Stat 1;
BA_ "U_T6_MCA_MY2020_Rx" SG_ 839 FohT1Sunday_T_Stat 1;
BA_ "ContentDependant" SG_ 839 FohT1Sunday_T_Stat 1;
BA_ "U_T6_MCA_MY2020_Rx" SG_ 839 FohT1Saturday_T_Stat 1;
BA_ "ContentDependant" SG_ 839 FohT1Saturday_T_Stat 1;
BA_ "U_T6_MCA_MY2020_Rx" SG_ 839 FohT1Monday_T_Stat 1;
BA_ "ContentDependant" SG_ 839 FohT1Monday_T_Stat 1;
BA_ "U_T6_MCA_MY2020_Rx" SG_ 839 FohT1Friday_T_Stat 1;
BA_ "ContentDependant" SG_ 839 FohT1Friday_T_Stat 1;
BA_ "U_U55X_MY2022_Rx" SG_ 1091 CamraRearOn_D2_Stat2 1;
BA_ "U_CD542_MY2021_Rx" SG_ 1091 CamraRearOn_D2_Stat2 1;
BA_ "U_P702_MY2021_Rx" SG_ 1091 CamraRearOn_D2_Stat2 1;
BA_ "U_T6_MCA_MY2020_Rx" SG_ 1091 PoliceAux4Lamp_B_Rq2 1;
BA_ "ContentDependant" SG_ 1091 PoliceAux4Lamp_B_Rq2 1;
BA_ "U_T6_MCA_MY2020_Rx" SG_ 1091 PoliceAux3Lamp_B_Rq2 1;
BA_ "ContentDependant" SG_ 1091 PoliceAux3Lamp_B_Rq2 1;
BA_ "U_T6_MCA_MY2020_Rx" SG_ 1091 PoliceAux2Lamp_B_Rq2 1;
BA_ "ContentDependant" SG_ 1091 PoliceAux2Lamp_B_Rq2 1;
BA_ "U_T6_MCA_MY2020_Rx" SG_ 1091 PoliceAux1Lamp_B_Rq2 1;
BA_ "ContentDependant" SG_ 1091 PoliceAux1Lamp_B_Rq2 1;
BA_ "U_U55X_MY2022_Tx" SG_ 1091 WakeAlarm2_T_Rq 1;
BA_ "U_T6_MCA_MY2020_Tx" SG_ 1091 WakeAlarm2_T_Rq 1;
BA_ "GenSigSendType" SG_ 1091 WakeAlarm2_T_Rq 3;
BA_ "GenSigStartValue" SG_ 1091 WakeAlarm2_T_Rq 32767;
BA_ "GenSigStartValueInteger" SG_ 1091 WakeAlarm2_T_Rq 32767;
BA_ "U_U55X_MY2022_Tx" SG_ 1091 WakeAlarm2_B_Typ 1;
BA_ "U_T6_MCA_MY2020_Tx" SG_ 1091 WakeAlarm2_B_Typ 1;
BA_ "GenSigSendType" SG_ 1091 WakeAlarm2_B_Typ 3;
BA_ "U_U55X_MY2022_Tx" SG_ 1091 TrlrAlarmSpprt_D_Stat 1;
BA_ "U_T6_MCA_MY2020_Tx" SG_ 1091 TrlrAlarmSpprt_D_Stat 1;
BA_ "U_U55X_MY2022_Rx" SG_ 1091 TrlrAlarmSpprt_D_Stat 1;
BA_ "U_CD542_MY2021_Rx" SG_ 1091 TrlrAlarmSpprt_D_Stat 1;
BA_ "U_T6_MCA_MY2020_Rx" SG_ 1091 TrlrAlarmSpprt_D_Stat 1;
BA_ "GenSigSendType" SG_ 1091 TrlrAlarmSpprt_D_Stat 3;
BA_ "U_T6_MCA_MY2020_Tx" SG_ 1091 ParkLampTrlrOut_B_Stat 1;
BA_ "U_P702_MY2021_Tx" SG_ 1091 ParkLampTrlrOut_B_Stat 1;
BA_ "U_U55X_MY2022_Rx" SG_ 1091 ParkLampTrlrOut_B_Stat 1;
BA_ "U_T6_MCA_MY2020_Rx" SG_ 1091 ParkLampTrlrOut_B_Stat 1;
BA_ "U_P702_MY2021_Rx" SG_ 1091 ParkLampTrlrOut_B_Stat 1;
BA_ "U_U55X_MY2022_Tx" SG_ 1091 TrlrLampCtl_D_Stat 1;
BA_ "U_T6_MCA_MY2020_Tx" SG_ 1091 TrlrLampCtl_D_Stat 1;
BA_ "U_P702_MY2021_Tx" SG_ 1091 TrlrLampCtl_D_Stat 1;
BA_ "U_U55X_MY2022_Rx" SG_ 1091 TrlrLampCtl_D_Stat 1;
BA_ "U_T6_MCA_MY2020_Rx" SG_ 1091 TrlrLampCtl_D_Stat 1;
BA_ "U_P702_MY2021_Rx" SG_ 1091 TrlrLampCtl_D_Stat 1;
BA_ "U_U55X_MY2022_Tx" SG_ 1091 TrlrBattChrg_D_Stat 1;
BA_ "U_T6_MCA_MY2020_Tx" SG_ 1091 TrlrBattChrg_D_Stat 1;
BA_ "U_P702_MY2021_Tx" SG_ 1091 TrlrBattChrg_D_Stat 1;
BA_ "U_U55X_MY2022_Rx" SG_ 1091 TrlrBattChrg_D_Stat 1;
BA_ "U_T6_MCA_MY2020_Rx" SG_ 1091 TrlrBattChrg_D_Stat 1;
BA_ "U_P702_MY2021_Rx" SG_ 1091 TrlrBattChrg_D_Stat 1;
BA_ "U_U55X_MY2022_Tx" SG_ 1091 StopLampTrlrOut_B_Stat 1;
BA_ "U_T6_MCA_MY2020_Tx" SG_ 1091 StopLampTrlrOut_B_Stat 1;
BA_ "U_P702_MY2021_Tx" SG_ 1091 StopLampTrlrOut_B_Stat 1;
BA_ "U_U55X_MY2022_Rx" SG_ 1091 StopLampTrlrOut_B_Stat 1;
BA_ "U_T6_MCA_MY2020_Rx" SG_ 1091 StopLampTrlrOut_B_Stat 1;
BA_ "U_P702_MY2021_Rx" SG_ 1091 StopLampTrlrOut_B_Stat 1;
BA_ "U_U55X_MY2022_Tx" SG_ 1091 TurnLampTrlrRr_B_Stat 1;
BA_ "U_T6_MCA_MY2020_Tx" SG_ 1091 TurnLampTrlrRr_B_Stat 1;
BA_ "U_P702_MY2021_Tx" SG_ 1091 TurnLampTrlrRr_B_Stat 1;
BA_ "U_U55X_MY2022_Rx" SG_ 1091 TurnLampTrlrRr_B_Stat 1;
BA_ "U_T6_MCA_MY2020_Rx" SG_ 1091 TurnLampTrlrRr_B_Stat 1;
BA_ "U_P702_MY2021_Rx" SG_ 1091 TurnLampTrlrRr_B_Stat 1;
BA_ "U_U55X_MY2022_Tx" SG_ 1091 TurnLampTrlrRl_B_Stat 1;
BA_ "U_T6_MCA_MY2020_Tx" SG_ 1091 TurnLampTrlrRl_B_Stat 1;
BA_ "U_P702_MY2021_Tx" SG_ 1091 TurnLampTrlrRl_B_Stat 1;
BA_ "U_U55X_MY2022_Rx" SG_ 1091 TurnLampTrlrRl_B_Stat 1;
BA_ "U_T6_MCA_MY2020_Rx" SG_ 1091 TurnLampTrlrRl_B_Stat 1;
BA_ "U_P702_MY2021_Rx" SG_ 1091 TurnLampTrlrRl_B_Stat 1;
BA_ "U_U55X_MY2022_Tx" SG_ 1091 TrlrLampCnnct_B_Actl 1;
BA_ "U_T6_MCA_MY2020_Tx" SG_ 1091 TrlrLampCnnct_B_Actl 1;
BA_ "U_P702_MY2021_Tx" SG_ 1091 TrlrLampCnnct_B_Actl 1;
BA_ "U_CD542_MY2021_Rx" SG_ 1091 TrlrLampCnnct_B_Actl 1;
BA_ "U_U55X_MY2022_Rx" SG_ 1091 TrlrLampCnnct_B_Actl 1;
BA_ "U_T6_MCA_MY2020_Rx" SG_ 1091 TrlrLampCnnct_B_Actl 1;
BA_ "U_P702_MY2021_Rx" SG_ 1091 TrlrLampCnnct_B_Actl 1;
BA_ "U_U55X_MY2022_Tx" SG_ 1425 IPC_GWOnBoardTester 1;
BA_ "U_CD542_MY2021_Tx" SG_ 1425 IPC_GWOnBoardTester 1;
BA_ "U_T6_MCA_MY2020_Tx" SG_ 1425 IPC_GWOnBoardTester 1;
BA_ "U_P702_MY2021_Tx" SG_ 1425 IPC_GWOnBoardTester 1;
BA_ "U_U55X_MY2022_Rx" SG_ 1425 IPC_GWOnBoardTester 1;
BA_ "U_T6_MCA_MY2020_Rx" SG_ 1425 IPC_GWOnBoardTester 1;
BA_ "GenSigStartValue" SG_ 1425 IPC_GWOnBoardTester 255;
BA_ "ContentDependant" SG_ 1425 IPC_GWOnBoardTester 1;
BA_ "GenSigStartValueInteger" SG_ 1425 IPC_GWOnBoardTester 255;
BA_ "U_U55X_MY2022_Tx" SG_ 1425 IPC_GWNMProxy 1;
BA_ "U_CD542_MY2021_Tx" SG_ 1425 IPC_GWNMProxy 1;
BA_ "U_T6_MCA_MY2020_Tx" SG_ 1425 IPC_GWNMProxy 1;
BA_ "U_P702_MY2021_Tx" SG_ 1425 IPC_GWNMProxy 1;
BA_ "U_U55X_MY2022_Rx" SG_ 1425 IPC_GWNMProxy 1;
BA_ "U_T6_MCA_MY2020_Rx" SG_ 1425 IPC_GWNMProxy 1;
BA_ "GenSigStartValue" SG_ 1425 IPC_GWNMProxy 255;
BA_ "ContentDependant" SG_ 1425 IPC_GWNMProxy 1;
BA_ "GenSigStartValueInteger" SG_ 1425 IPC_GWNMProxy 255;
BA_ "U_U55X_MY2022_Tx" SG_ 1425 IPC_AutoSarNMReserved4 1;
BA_ "U_CD542_MY2021_Tx" SG_ 1425 IPC_AutoSarNMReserved4 1;
BA_ "U_T6_MCA_MY2020_Tx" SG_ 1425 IPC_AutoSarNMReserved4 1;
BA_ "U_P702_MY2021_Tx" SG_ 1425 IPC_AutoSarNMReserved4 1;
BA_ "U_U55X_MY2022_Rx" SG_ 1425 IPC_AutoSarNMReserved4 1;
BA_ "U_T6_MCA_MY2020_Rx" SG_ 1425 IPC_AutoSarNMReserved4 1;
BA_ "GenSigStartValue" SG_ 1425 IPC_AutoSarNMReserved4 255;
BA_ "ContentDependant" SG_ 1425 IPC_AutoSarNMReserved4 1;
BA_ "GenSigStartValueInteger" SG_ 1425 IPC_AutoSarNMReserved4 255;
BA_ "U_U55X_MY2022_Tx" SG_ 1425 IPC_AutoSarNMReserved3 1;
BA_ "U_CD542_MY2021_Tx" SG_ 1425 IPC_AutoSarNMReserved3 1;
BA_ "U_T6_MCA_MY2020_Tx" SG_ 1425 IPC_AutoSarNMReserved3 1;
BA_ "U_P702_MY2021_Tx" SG_ 1425 IPC_AutoSarNMReserved3 1;
BA_ "U_U55X_MY2022_Rx" SG_ 1425 IPC_AutoSarNMReserved3 1;
BA_ "U_T6_MCA_MY2020_Rx" SG_ 1425 IPC_AutoSarNMReserved3 1;
BA_ "GenSigStartValue" SG_ 1425 IPC_AutoSarNMReserved3 255;
BA_ "ContentDependant" SG_ 1425 IPC_AutoSarNMReserved3 1;
BA_ "GenSigStartValueInteger" SG_ 1425 IPC_AutoSarNMReserved3 255;
BA_ "U_U55X_MY2022_Tx" SG_ 1425 IPC_AutoSarNMReserved2 1;
BA_ "U_CD542_MY2021_Tx" SG_ 1425 IPC_AutoSarNMReserved2 1;
BA_ "U_T6_MCA_MY2020_Tx" SG_ 1425 IPC_AutoSarNMReserved2 1;
BA_ "U_P702_MY2021_Tx" SG_ 1425 IPC_AutoSarNMReserved2 1;
BA_ "U_U55X_MY2022_Rx" SG_ 1425 IPC_AutoSarNMReserved2 1;
BA_ "U_T6_MCA_MY2020_Rx" SG_ 1425 IPC_AutoSarNMReserved2 1;
BA_ "GenSigStartValue" SG_ 1425 IPC_AutoSarNMReserved2 255;
BA_ "ContentDependant" SG_ 1425 IPC_AutoSarNMReserved2 1;
BA_ "GenSigStartValueInteger" SG_ 1425 IPC_AutoSarNMReserved2 255;
BA_ "U_U55X_MY2022_Tx" SG_ 1425 IPC_AutoSarNMReserved1 1;
BA_ "U_CD542_MY2021_Tx" SG_ 1425 IPC_AutoSarNMReserved1 1;
BA_ "U_T6_MCA_MY2020_Tx" SG_ 1425 IPC_AutoSarNMReserved1 1;
BA_ "U_P702_MY2021_Tx" SG_ 1425 IPC_AutoSarNMReserved1 1;
BA_ "U_U55X_MY2022_Rx" SG_ 1425 IPC_AutoSarNMReserved1 1;
BA_ "U_T6_MCA_MY2020_Rx" SG_ 1425 IPC_AutoSarNMReserved1 1;
BA_ "GenSigStartValue" SG_ 1425 IPC_AutoSarNMReserved1 255;
BA_ "ContentDependant" SG_ 1425 IPC_AutoSarNMReserved1 1;
BA_ "GenSigStartValueInteger" SG_ 1425 IPC_AutoSarNMReserved1 255;
BA_ "U_U55X_MY2022_Tx" SG_ 1425 IPC_AutoSarNMNodeId 1;
BA_ "U_CD542_MY2021_Tx" SG_ 1425 IPC_AutoSarNMNodeId 1;
BA_ "U_T6_MCA_MY2020_Tx" SG_ 1425 IPC_AutoSarNMNodeId 1;
BA_ "U_P702_MY2021_Tx" SG_ 1425 IPC_AutoSarNMNodeId 1;
BA_ "U_U55X_MY2022_Rx" SG_ 1425 IPC_AutoSarNMNodeId 1;
BA_ "U_T6_MCA_MY2020_Rx" SG_ 1425 IPC_AutoSarNMNodeId 1;
BA_ "GenSigStartValue" SG_ 1425 IPC_AutoSarNMNodeId 145;
BA_ "ContentDependant" SG_ 1425 IPC_AutoSarNMNodeId 1;
BA_ "GenSigStartValueInteger" SG_ 1425 IPC_AutoSarNMNodeId 145;
BA_ "U_U55X_MY2022_Tx" SG_ 1425 IPC_AutoSarNMControl 1;
BA_ "U_CD542_MY2021_Tx" SG_ 1425 IPC_AutoSarNMControl 1;
BA_ "U_T6_MCA_MY2020_Tx" SG_ 1425 IPC_AutoSarNMControl 1;
BA_ "U_P702_MY2021_Tx" SG_ 1425 IPC_AutoSarNMControl 1;
BA_ "U_U55X_MY2022_Rx" SG_ 1425 IPC_AutoSarNMControl 1;
BA_ "U_T6_MCA_MY2020_Rx" SG_ 1425 IPC_AutoSarNMControl 1;
BA_ "ContentDependant" SG_ 1425 IPC_AutoSarNMControl 1;
BA_ "U_U55X_MY2022_Rx" SG_ 998 PersIndexSccm_D_Actl 1;
BA_ "U_CD542_MY2021_Rx" SG_ 998 PersIndexSccm_D_Actl 1;
BA_ "U_T6_MCA_MY2020_Rx" SG_ 998 PersIndexSccm_D_Actl 1;
BA_ "U_P702_MY2021_Rx" SG_ 998 PersIndexSccm_D_Actl 1;
BA_ "GenSigStartValue" SG_ 998 PersIndexSccm_D_Actl 4;
BA_ "GenSigStartValueInteger" SG_ 998 PersIndexSccm_D_Actl 4;
BA_ "U_U55X_MY2022_Rx" SG_ 998 FeatNoSccmActl 1;
BA_ "U_CD542_MY2021_Rx" SG_ 998 FeatNoSccmActl 1;
BA_ "U_T6_MCA_MY2020_Rx" SG_ 998 FeatNoSccmActl 1;
BA_ "U_P702_MY2021_Rx" SG_ 998 FeatNoSccmActl 1;
BA_ "U_U55X_MY2022_Rx" SG_ 998 FeatConfigSccmActl 1;
BA_ "U_CD542_MY2021_Rx" SG_ 998 FeatConfigSccmActl 1;
BA_ "U_T6_MCA_MY2020_Rx" SG_ 998 FeatConfigSccmActl 1;
BA_ "U_P702_MY2021_Rx" SG_ 998 FeatConfigSccmActl 1;
BA_ "U_U55X_MY2022_Rx" SG_ 984 DsmcMsgTxt_D_Dsply 1;
BA_ "U_CD542_MY2021_Rx" SG_ 984 DsmcMsgTxt_D_Dsply 1;
BA_ "U_T6_MCA_MY2020_Rx" SG_ 984 DsmcMsgTxt_D_Dsply 1;
BA_ "U_U55X_MY2022_Rx" SG_ 984 AhbcStat_B_Dsply 1;
BA_ "U_CD542_MY2021_Rx" SG_ 984 AhbcStat_B_Dsply 1;
BA_ "U_T6_MCA_MY2020_Rx" SG_ 984 AhbcStat_B_Dsply 1;
BA_ "U_U55X_MY2022_Rx" SG_ 984 DasWarn_D_Dsply 1;
BA_ "U_CD542_MY2021_Rx" SG_ 984 DasWarn_D_Dsply 1;
BA_ "U_T6_MCA_MY2020_Rx" SG_ 984 DasWarn_D_Dsply 1;
BA_ "U_P702_MY2021_Rx" SG_ 984 DasWarn_D_Dsply 1;
BA_ "U_U55X_MY2022_Rx" SG_ 984 DasStats_D_Dsply 1;
BA_ "U_CD542_MY2021_Rx" SG_ 984 DasStats_D_Dsply 1;
BA_ "U_T6_MCA_MY2020_Rx" SG_ 984 DasStats_D_Dsply 1;
BA_ "U_P702_MY2021_Rx" SG_ 984 DasStats_D_Dsply 1;
BA_ "U_U55X_MY2022_Rx" SG_ 984 DasAlrtLvl_D_Dsply 1;
BA_ "U_CD542_MY2021_Rx" SG_ 984 DasAlrtLvl_D_Dsply 1;
BA_ "U_T6_MCA_MY2020_Rx" SG_ 984 DasAlrtLvl_D_Dsply 1;
BA_ "U_P702_MY2021_Rx" SG_ 984 DasAlrtLvl_D_Dsply 1;
BA_ "U_U55X_MY2022_Rx" SG_ 984 CamraStats_D_Dsply 1;
BA_ "U_CD542_MY2021_Rx" SG_ 984 CamraStats_D_Dsply 1;
BA_ "U_T6_MCA_MY2020_Rx" SG_ 984 CamraStats_D_Dsply 1;
BA_ "U_P702_MY2021_Rx" SG_ 984 CamraStats_D_Dsply 1;
BA_ "U_U55X_MY2022_Rx" SG_ 984 LaHandsOff_D_Dsply 1;
BA_ "U_CD542_MY2021_Rx" SG_ 984 LaHandsOff_D_Dsply 1;
BA_ "U_T6_MCA_MY2020_Rx" SG_ 984 LaHandsOff_D_Dsply 1;
BA_ "U_P702_MY2021_Rx" SG_ 984 LaHandsOff_D_Dsply 1;
BA_ "U_U55X_MY2022_Rx" SG_ 984 LaDenyStats_B_Dsply 1;
BA_ "U_CD542_MY2021_Rx" SG_ 984 LaDenyStats_B_Dsply 1;
BA_ "U_T6_MCA_MY2020_Rx" SG_ 984 LaDenyStats_B_Dsply 1;
BA_ "U_P702_MY2021_Rx" SG_ 984 LaDenyStats_B_Dsply 1;
BA_ "U_U55X_MY2022_Rx" SG_ 984 LaActvStats_D_Dsply 1;
BA_ "U_CD542_MY2021_Rx" SG_ 984 LaActvStats_D_Dsply 1;
BA_ "U_T6_MCA_MY2020_Rx" SG_ 984 LaActvStats_D_Dsply 1;
BA_ "U_P702_MY2021_Rx" SG_ 984 LaActvStats_D_Dsply 1;
BA_ "U_CD542_MY2021_Rx" SG_ 984 CamraDefog_B_Req 1;
BA_ "U_T6_MCA_MY2020_Rx" SG_ 984 CamraDefog_B_Req 1;
BA_ "U_U55X_MY2022_Rx" SG_ 984 PersIndexIpma_D_Actl 1;
BA_ "U_CD542_MY2021_Rx" SG_ 984 PersIndexIpma_D_Actl 1;
BA_ "U_T6_MCA_MY2020_Rx" SG_ 984 PersIndexIpma_D_Actl 1;
BA_ "U_P702_MY2021_Rx" SG_ 984 PersIndexIpma_D_Actl 1;
BA_ "GenSigStartValue" SG_ 984 PersIndexIpma_D_Actl 4;
BA_ "GenSigStartValueInteger" SG_ 984 PersIndexIpma_D_Actl 4;
BA_ "U_U55X_MY2022_Rx" SG_ 984 FeatNoIpmaActl 1;
BA_ "U_CD542_MY2021_Rx" SG_ 984 FeatNoIpmaActl 1;
BA_ "U_T6_MCA_MY2020_Rx" SG_ 984 FeatNoIpmaActl 1;
BA_ "U_P702_MY2021_Rx" SG_ 984 FeatNoIpmaActl 1;
BA_ "U_U55X_MY2022_Rx" SG_ 984 FeatConfigIpmaActl 1;
BA_ "U_CD542_MY2021_Rx" SG_ 984 FeatConfigIpmaActl 1;
BA_ "U_T6_MCA_MY2020_Rx" SG_ 984 FeatConfigIpmaActl 1;
BA_ "U_P702_MY2021_Rx" SG_ 984 FeatConfigIpmaActl 1;
BA_ "U_CD542_MY2021_Tx" SG_ 1072 PtDrvMde_D_Rq 1;
BA_ "U_T6_MCA_MY2020_Tx" SG_ 1072 PtDrvMde_D_Rq 1;
BA_ "GenSigSendType" SG_ 1072 PtDrvMde_D_Rq 3;
BA_ "U_U55X_MY2022_Tx" SG_ 1072 DrvSlipCtlMde_D_Rq 1;
BA_ "U_CD542_MY2021_Tx" SG_ 1072 DrvSlipCtlMde_D_Rq 1;
BA_ "U_T6_MCA_MY2020_Tx" SG_ 1072 DrvSlipCtlMde_D_Rq 1;
BA_ "U_P702_MY2021_Tx" SG_ 1072 DrvSlipCtlMde_D_Rq 1;
BA_ "U_U55X_MY2022_Rx" SG_ 1072 DrvSlipCtlMde_D_Rq 1;
BA_ "U_CD542_MY2021_Rx" SG_ 1072 DrvSlipCtlMde_D_Rq 1;
BA_ "ECGUsedRxSignal" SG_ 1072 DrvSlipCtlMde_D_Rq 1;
BA_ "U_T6_MCA_MY2020_Rx" SG_ 1072 DrvSlipCtlMde_D_Rq 1;
BA_ "GenSigSendType" SG_ 1072 DrvSlipCtlMde_D_Rq 3;
BA_ "U_U55X_MY2022_Tx" SG_ 1072 EngIdlShutDown_B_RqDrv 1;
BA_ "U_CD542_MY2021_Tx" SG_ 1072 EngIdlShutDown_B_RqDrv 1;
BA_ "U_T6_MCA_MY2020_Tx" SG_ 1072 EngIdlShutDown_B_RqDrv 1;
BA_ "U_P702_MY2021_Tx" SG_ 1072 EngIdlShutDown_B_RqDrv 1;
BA_ "GenSigSendType" SG_ 1072 EngIdlShutDown_B_RqDrv 3;
BA_ "U_CD542_MY2021_Tx" SG_ 1072 DrvPerfMde_D_Rq 1;
BA_ "U_T6_MCA_MY2020_Tx" SG_ 1072 DrvPerfMde_D_Rq 1;
BA_ "GenSigSendType" SG_ 1072 DrvPerfMde_D_Rq 3;
BA_ "U_U55X_MY2022_Tx" SG_ 1072 HaDsplyCpblty_B_Stat 1;
BA_ "U_T6_MCA_MY2020_Tx" SG_ 1072 HaDsplyCpblty_B_Stat 1;
BA_ "GenSigSendType" SG_ 1072 HaDsplyCpblty_B_Stat 3;
BA_ "U_U55X_MY2022_Tx" SG_ 1072 HsaMde_D_Rq 1;
BA_ "U_CD542_MY2021_Tx" SG_ 1072 HsaMde_D_Rq 1;
BA_ "U_T6_MCA_MY2020_Tx" SG_ 1072 HsaMde_D_Rq 1;
BA_ "U_P702_MY2021_Tx" SG_ 1072 HsaMde_D_Rq 1;
BA_ "GenSigSendType" SG_ 1072 HsaMde_D_Rq 3;
BA_ "GenSigStartValue" SG_ 1072 HsaMde_D_Rq 1;
BA_ "GenSigStartValueInteger" SG_ 1072 HsaMde_D_Rq 1;
BA_ "U_CD542_MY2021_Tx" SG_ 1072 StopStrtDrvMde_D_RqMnu 1;
BA_ "U_T6_MCA_MY2020_Tx" SG_ 1072 StopStrtDrvMde_D_RqMnu 1;
BA_ "GenSigSendType" SG_ 1072 StopStrtDrvMde_D_RqMnu 3;
BA_ "U_U55X_MY2022_Tx" SG_ 1072 NtrlTowMdeEnbl_B_RqDrv 1;
BA_ "U_CD542_MY2021_Tx" SG_ 1072 NtrlTowMdeEnbl_B_RqDrv 1;
BA_ "U_T6_MCA_MY2020_Tx" SG_ 1072 NtrlTowMdeEnbl_B_RqDrv 1;
BA_ "U_P702_MY2021_Tx" SG_ 1072 NtrlTowMdeEnbl_B_RqDrv 1;
BA_ "GenSigSendType" SG_ 1072 NtrlTowMdeEnbl_B_RqDrv 3;
BA_ "U_U55X_MY2022_Tx" SG_ 1072 LscmbbStat_B_Actl 1;
BA_ "U_CD542_MY2021_Tx" SG_ 1072 LscmbbStat_B_Actl 1;
BA_ "U_T6_MCA_MY2020_Tx" SG_ 1072 LscmbbStat_B_Actl 1;
BA_ "U_U55X_MY2022_Rx" SG_ 1072 LscmbbStat_B_Actl 1;
BA_ "U_CD542_MY2021_Rx" SG_ 1072 LscmbbStat_B_Actl 1;
BA_ "ECGUsedRxSignal" SG_ 1072 LscmbbStat_B_Actl 1;
BA_ "U_T6_MCA_MY2020_Rx" SG_ 1072 LscmbbStat_B_Actl 1;
BA_ "GenSigSendType" SG_ 1072 LscmbbStat_B_Actl 3;
BA_ "U_U55X_MY2022_Tx" SG_ 1072 BulbChkActv_B_Stat 1;
BA_ "U_CD542_MY2021_Tx" SG_ 1072 BulbChkActv_B_Stat 1;
BA_ "U_T6_MCA_MY2020_Tx" SG_ 1072 BulbChkActv_B_Stat 1;
BA_ "U_P702_MY2021_Tx" SG_ 1072 BulbChkActv_B_Stat 1;
BA_ "GenSigSendType" SG_ 1072 BulbChkActv_B_Stat 3;
BA_ "U_U55X_MY2022_Tx" SG_ 1072 ParkDetect_Stat 1;
BA_ "U_CD542_MY2021_Tx" SG_ 1072 ParkDetect_Stat 1;
BA_ "U_T6_MCA_MY2020_Tx" SG_ 1072 ParkDetect_Stat 1;
BA_ "U_U55X_MY2022_Rx" SG_ 1072 ParkDetect_Stat 1;
BA_ "U_T6_MCA_MY2020_Rx" SG_ 1072 ParkDetect_Stat 1;
BA_ "GenSigSendType" SG_ 1072 ParkDetect_Stat 3;
BA_ "U_U55X_MY2022_Tx" SG_ 1072 ReducedGuard_D_Rq 1;
BA_ "U_CD542_MY2021_Tx" SG_ 1072 ReducedGuard_D_Rq 1;
BA_ "U_T6_MCA_MY2020_Tx" SG_ 1072 ReducedGuard_D_Rq 1;
BA_ "U_P702_MY2021_Tx" SG_ 1072 ReducedGuard_D_Rq 1;
BA_ "GenSigSendType" SG_ 1072 ReducedGuard_D_Rq 3;
BA_ "U_CD542_MY2021_Tx" SG_ 1072 FrostWarn_D_Stat 1;
BA_ "U_T6_MCA_MY2020_Tx" SG_ 1072 FrostWarn_D_Stat 1;
BA_ "GenSigSendType" SG_ 1072 FrostWarn_D_Stat 3;
BA_ "U_U55X_MY2022_Tx" SG_ 1072 TrlrBrkMde_D_Rq 1;
BA_ "U_CD542_MY2021_Tx" SG_ 1072 TrlrBrkMde_D_Rq 1;
BA_ "U_T6_MCA_MY2020_Tx" SG_ 1072 TrlrBrkMde_D_Rq 1;
BA_ "U_P702_MY2021_Tx" SG_ 1072 TrlrBrkMde_D_Rq 1;
BA_ "U_U55X_MY2022_Rx" SG_ 1072 TrlrBrkMde_D_Rq 1;
BA_ "U_T6_MCA_MY2020_Rx" SG_ 1072 TrlrBrkMde_D_Rq 1;
BA_ "U_P702_MY2021_Rx" SG_ 1072 TrlrBrkMde_D_Rq 1;
BA_ "GenSigSendType" SG_ 1072 TrlrBrkMde_D_Rq 3;
BA_ "U_U55X_MY2022_Tx" SG_ 1072 TRLR_SWAY_CONFIG_CMD 1;
BA_ "U_CD542_MY2021_Tx" SG_ 1072 TRLR_SWAY_CONFIG_CMD 1;
BA_ "U_P702_MY2021_Tx" SG_ 1072 TRLR_SWAY_CONFIG_CMD 1;
BA_ "GenSigSendType" SG_ 1072 TRLR_SWAY_CONFIG_CMD 3;
BA_ "U_U55X_MY2022_Tx" SG_ 1072 TRAILER_BRAKE_CONFIG 1;
BA_ "U_CD542_MY2021_Tx" SG_ 1072 TRAILER_BRAKE_CONFIG 1;
BA_ "U_P702_MY2021_Tx" SG_ 1072 TRAILER_BRAKE_CONFIG 1;
BA_ "U_U55X_MY2022_Rx" SG_ 1072 TRAILER_BRAKE_CONFIG 1;
BA_ "U_T6_MCA_MY2020_Rx" SG_ 1072 TRAILER_BRAKE_CONFIG 1;
BA_ "U_P702_MY2021_Rx" SG_ 1072 TRAILER_BRAKE_CONFIG 1;
BA_ "GenSigSendType" SG_ 1072 TRAILER_BRAKE_CONFIG 3;
BA_ "U_U55X_MY2022_Tx" SG_ 1072 Power_Liftgate_Mode_Cmd 1;
BA_ "U_CD542_MY2021_Tx" SG_ 1072 Power_Liftgate_Mode_Cmd 1;
BA_ "U_T6_MCA_MY2020_Tx" SG_ 1072 Power_Liftgate_Mode_Cmd 1;
BA_ "U_P702_MY2021_Tx" SG_ 1072 Power_Liftgate_Mode_Cmd 1;
BA_ "GenSigSendType" SG_ 1072 Power_Liftgate_Mode_Cmd 3;
BA_ "WakeupSignal" SG_ 1072 Power_Liftgate_Mode_Cmd 1;
BA_ "U_U55X_MY2022_Tx" SG_ 1072 AccEnbl_B_RqDrv 1;
BA_ "U_CD542_MY2021_Tx" SG_ 1072 AccEnbl_B_RqDrv 1;
BA_ "U_T6_MCA_MY2020_Tx" SG_ 1072 AccEnbl_B_RqDrv 1;
BA_ "U_P702_MY2021_Tx" SG_ 1072 AccEnbl_B_RqDrv 1;
BA_ "U_U55X_MY2022_Rx" SG_ 1072 AccEnbl_B_RqDrv 1;
BA_ "U_T6_MCA_MY2020_Rx" SG_ 1072 AccEnbl_B_RqDrv 1;
BA_ "GenSigSendType" SG_ 1072 AccEnbl_B_RqDrv 3;
BA_ "GenSigStartValue" SG_ 1072 AccEnbl_B_RqDrv 1;
BA_ "GenSigStartValueInteger" SG_ 1072 AccEnbl_B_RqDrv 1;
BA_ "U_U55X_MY2022_Tx" SG_ 1072 OdometerMasterValue 1;
BA_ "U_CD542_MY2021_Tx" SG_ 1072 OdometerMasterValue 1;
BA_ "U_T6_MCA_MY2020_Tx" SG_ 1072 OdometerMasterValue 1;
BA_ "U_P702_MY2021_Tx" SG_ 1072 OdometerMasterValue 1;
BA_ "ECGUsedRxSignal" SG_ 1072 OdometerMasterValue 1;
BA_ "U_U55X_MY2022_Rx" SG_ 1072 OdometerMasterValue 1;
BA_ "U_CD542_MY2021_Rx" SG_ 1072 OdometerMasterValue 1;
BA_ "U_T6_MCA_MY2020_Rx" SG_ 1072 OdometerMasterValue 1;
BA_ "U_U55X_MY2022_Tx" SG_ 1072 EngOilLife_B_RqReset 1;
BA_ "U_CD542_MY2021_Tx" SG_ 1072 EngOilLife_B_RqReset 1;
BA_ "U_T6_MCA_MY2020_Tx" SG_ 1072 EngOilLife_B_RqReset 1;
BA_ "U_P702_MY2021_Tx" SG_ 1072 EngOilLife_B_RqReset 1;
BA_ "GenSigSendType" SG_ 1072 EngOilLife_B_RqReset 3;
BA_ "U_U55X_MY2022_Tx" SG_ 1072 MetricActvTe_B_Actl 1;
BA_ "U_CD542_MY2021_Tx" SG_ 1072 MetricActvTe_B_Actl 1;
BA_ "U_T6_MCA_MY2020_Tx" SG_ 1072 MetricActvTe_B_Actl 1;
BA_ "GenSigSendType" SG_ 1072 MetricActvTe_B_Actl 3;
BA_ "U_U55X_MY2022_Tx" SG_ 1072 AccDeny_B_RqIpc 1;
BA_ "U_CD542_MY2021_Tx" SG_ 1072 AccDeny_B_RqIpc 1;
BA_ "U_T6_MCA_MY2020_Tx" SG_ 1072 AccDeny_B_RqIpc 1;
BA_ "U_U55X_MY2022_Rx" SG_ 1072 AccDeny_B_RqIpc 1;
BA_ "U_T6_MCA_MY2020_Rx" SG_ 1072 AccDeny_B_RqIpc 1;
BA_ "GenSigSendType" SG_ 1072 AccDeny_B_RqIpc 3;
BA_ "U_U55X_MY2022_Tx" SG_ 1072 ePRNDL_MODE 1;
BA_ "U_CD542_MY2021_Tx" SG_ 1072 ePRNDL_MODE 1;
BA_ "U_T6_MCA_MY2020_Tx" SG_ 1072 ePRNDL_MODE 1;
BA_ "U_P702_MY2021_Tx" SG_ 1072 ePRNDL_MODE 1;
BA_ "GenSigSendType" SG_ 1072 ePRNDL_MODE 3;
BA_ "WakeupSignal" SG_ 1072 ePRNDL_MODE 1;
BA_ "U_CD542_MY2021_Tx" SG_ 1072 PrkLckCtlEnbl_D_RqIpc 1;
BA_ "U_T6_MCA_MY2020_Tx" SG_ 1072 PrkLckCtlEnbl_D_RqIpc 1;
BA_ "GenSigSendType" SG_ 1072 PrkLckCtlEnbl_D_RqIpc 3;
BA_ "U_U55X_MY2022_Tx" SG_ 1072 DrvSlipCtlMde_B_Rq2 1;
BA_ "U_CD542_MY2021_Tx" SG_ 1072 DrvSlipCtlMde_B_Rq2 1;
BA_ "U_T6_MCA_MY2020_Tx" SG_ 1072 DrvSlipCtlMde_B_Rq2 1;
BA_ "GenSigSendType" SG_ 1072 DrvSlipCtlMde_B_Rq2 3;
BA_ "U_CD542_MY2021_Tx" SG_ 1072 Fda_B_Stat 1;
BA_ "U_T6_MCA_MY2020_Tx" SG_ 1072 Fda_B_Stat 1;
BA_ "GenSigSendType" SG_ 1072 Fda_B_Stat 3;
BA_ "U_U55X_MY2022_Tx" SG_ 1072 MetricActv_B_Actl 1;
BA_ "U_CD542_MY2021_Tx" SG_ 1072 MetricActv_B_Actl 1;
BA_ "U_T6_MCA_MY2020_Tx" SG_ 1072 MetricActv_B_Actl 1;
BA_ "U_P702_MY2021_Tx" SG_ 1072 MetricActv_B_Actl 1;
BA_ "U_U55X_MY2022_Rx" SG_ 1072 MetricActv_B_Actl 1;
BA_ "U_CD542_MY2021_Rx" SG_ 1072 MetricActv_B_Actl 1;
BA_ "ECGUsedRxSignal" SG_ 1072 MetricActv_B_Actl 1;
BA_ "U_T6_MCA_MY2020_Rx" SG_ 1072 MetricActv_B_Actl 1;
BA_ "GenSigSendType" SG_ 1072 MetricActv_B_Actl 3;
BA_ "U_U55X_MY2022_Tx" SG_ 1072 KeyTypeChngMykey_D_Rq 1;
BA_ "U_CD542_MY2021_Tx" SG_ 1072 KeyTypeChngMykey_D_Rq 1;
BA_ "U_T6_MCA_MY2020_Tx" SG_ 1072 KeyTypeChngMykey_D_Rq 1;
BA_ "U_P702_MY2021_Tx" SG_ 1072 KeyTypeChngMykey_D_Rq 1;
BA_ "GenSigSendType" SG_ 1072 KeyTypeChngMykey_D_Rq 3;
BA_ "U_U55X_MY2022_Tx" SG_ 1072 ManRgen_D_Rq 1;
BA_ "U_CD542_MY2021_Tx" SG_ 1072 ManRgen_D_Rq 1;
BA_ "U_T6_MCA_MY2020_Tx" SG_ 1072 ManRgen_D_Rq 1;
BA_ "U_P702_MY2021_Tx" SG_ 1072 ManRgen_D_Rq 1;
BA_ "GenSigSendType" SG_ 1072 ManRgen_D_Rq 3;
BA_ "U_U55X_MY2022_Tx" SG_ 395 SelDrvMdeCnfm_D_Stat 1;
BA_ "U_CD542_MY2021_Tx" SG_ 395 SelDrvMdeCnfm_D_Stat 1;
BA_ "GenSigSendType" SG_ 395 SelDrvMdeCnfm_D_Stat 3;
BA_ "U_U55X_MY2022_Tx" SG_ 395 HudShifPoint_N_Rq 1;
BA_ "GenSigStartValue" SG_ 395 HudShifPoint_N_Rq 30;
BA_ "GenSigStartValueInteger" SG_ 395 HudShifPoint_N_Rq 30;
BA_ "U_U55X_MY2022_Tx" SG_ 395 HudMde_D_Rq 1;
BA_ "GenSigSendType" SG_ 395 HudMde_D_Rq 3;
BA_ "U_U55X_MY2022_Tx" SG_ 395 HudLedMde_D_Rq 1;
BA_ "GenSigSendType" SG_ 395 HudLedMde_D_Rq 3;
BA_ "U_U55X_MY2022_Tx" SG_ 395 HudLedIntns_Pc_Rq 1;
BA_ "U_U55X_MY2022_Tx" SG_ 395 HudLed9On_B_Rq 1;
BA_ "GenSigSendType" SG_ 395 HudLed9On_B_Rq 3;
BA_ "U_U55X_MY2022_Tx" SG_ 395 HudLed8On_B_Rq 1;
BA_ "GenSigSendType" SG_ 395 HudLed8On_B_Rq 3;
BA_ "U_U55X_MY2022_Tx" SG_ 395 HudLed7On_B_Rq 1;
BA_ "GenSigSendType" SG_ 395 HudLed7On_B_Rq 3;
BA_ "U_U55X_MY2022_Tx" SG_ 395 HudLed6On_B_Rq 1;
BA_ "GenSigSendType" SG_ 395 HudLed6On_B_Rq 3;
BA_ "U_U55X_MY2022_Tx" SG_ 395 HudLed5On_B_Rq 1;
BA_ "GenSigSendType" SG_ 395 HudLed5On_B_Rq 3;
BA_ "U_U55X_MY2022_Tx" SG_ 395 HudLed4On_B_Rq 1;
BA_ "GenSigSendType" SG_ 395 HudLed4On_B_Rq 3;
BA_ "U_U55X_MY2022_Tx" SG_ 395 HudLed3On_B_Rq 1;
BA_ "GenSigSendType" SG_ 395 HudLed3On_B_Rq 3;
BA_ "U_U55X_MY2022_Tx" SG_ 395 HudLed2On_B_Rq 1;
BA_ "GenSigSendType" SG_ 395 HudLed2On_B_Rq 3;
BA_ "U_U55X_MY2022_Tx" SG_ 395 HudLed1On_B_Rq 1;
BA_ "GenSigSendType" SG_ 395 HudLed1On_B_Rq 3;
BA_ "U_U55X_MY2022_Tx" SG_ 395 HudLed18On_B_Rq 1;
BA_ "GenSigSendType" SG_ 395 HudLed18On_B_Rq 3;
BA_ "U_U55X_MY2022_Tx" SG_ 395 HudLed17On_B_Rq 1;
BA_ "GenSigSendType" SG_ 395 HudLed17On_B_Rq 3;
BA_ "U_U55X_MY2022_Tx" SG_ 395 HudLed16On_B_Rq 1;
BA_ "GenSigSendType" SG_ 395 HudLed16On_B_Rq 3;
BA_ "U_U55X_MY2022_Tx" SG_ 395 HudLed15On_B_Rq 1;
BA_ "GenSigSendType" SG_ 395 HudLed15On_B_Rq 3;
BA_ "U_U55X_MY2022_Tx" SG_ 395 HudLed14On_B_Rq 1;
BA_ "GenSigSendType" SG_ 395 HudLed14On_B_Rq 3;
BA_ "U_U55X_MY2022_Tx" SG_ 395 HudLed13On_B_Rq 1;
BA_ "GenSigSendType" SG_ 395 HudLed13On_B_Rq 3;
BA_ "U_U55X_MY2022_Tx" SG_ 395 HudLed12On_B_Rq 1;
BA_ "GenSigSendType" SG_ 395 HudLed12On_B_Rq 3;
BA_ "U_U55X_MY2022_Tx" SG_ 395 HudLed11On_B_Rq 1;
BA_ "GenSigSendType" SG_ 395 HudLed11On_B_Rq 3;
BA_ "U_U55X_MY2022_Tx" SG_ 395 HudLed10On_B_Rq 1;
BA_ "GenSigSendType" SG_ 395 HudLed10On_B_Rq 3;
BA_ "U_U55X_MY2022_Tx" SG_ 1438 GWM_GWOnBoardTester 1;
BA_ "U_CD542_MY2021_Tx" SG_ 1438 GWM_GWOnBoardTester 1;
BA_ "ECGUsedTxSignal" SG_ 1438 GWM_GWOnBoardTester 1;
BA_ "U_T6_MCA_MY2020_Tx" SG_ 1438 GWM_GWOnBoardTester 1;
BA_ "U_CD542_MY2021_Rx" SG_ 1438 GWM_GWOnBoardTester 1;
BA_ "U_U55X_MY2022_Rx" SG_ 1438 GWM_GWOnBoardTester 1;
BA_ "U_T6_MCA_MY2020_Rx" SG_ 1438 GWM_GWOnBoardTester 1;
BA_ "U_P702_MY2021_Rx" SG_ 1438 GWM_GWOnBoardTester 1;
BA_ "GenSigStartValue" SG_ 1438 GWM_GWOnBoardTester 255;
BA_ "ContentDependant" SG_ 1438 GWM_GWOnBoardTester 1;
BA_ "GenSigStartValueInteger" SG_ 1438 GWM_GWOnBoardTester 255;
BA_ "U_U55X_MY2022_Tx" SG_ 1438 GWM_GWNMProxy 1;
BA_ "U_CD542_MY2021_Tx" SG_ 1438 GWM_GWNMProxy 1;
BA_ "ECGUsedTxSignal" SG_ 1438 GWM_GWNMProxy 1;
BA_ "U_T6_MCA_MY2020_Tx" SG_ 1438 GWM_GWNMProxy 1;
BA_ "U_CD542_MY2021_Rx" SG_ 1438 GWM_GWNMProxy 1;
BA_ "U_U55X_MY2022_Rx" SG_ 1438 GWM_GWNMProxy 1;
BA_ "U_T6_MCA_MY2020_Rx" SG_ 1438 GWM_GWNMProxy 1;
BA_ "U_P702_MY2021_Rx" SG_ 1438 GWM_GWNMProxy 1;
BA_ "GenSigStartValue" SG_ 1438 GWM_GWNMProxy 255;
BA_ "ContentDependant" SG_ 1438 GWM_GWNMProxy 1;
BA_ "GenSigStartValueInteger" SG_ 1438 GWM_GWNMProxy 255;
BA_ "U_U55X_MY2022_Tx" SG_ 1438 GWM_AutoSarNMReserved4 1;
BA_ "U_CD542_MY2021_Tx" SG_ 1438 GWM_AutoSarNMReserved4 1;
BA_ "ECGUsedTxSignal" SG_ 1438 GWM_AutoSarNMReserved4 1;
BA_ "U_T6_MCA_MY2020_Tx" SG_ 1438 GWM_AutoSarNMReserved4 1;
BA_ "U_CD542_MY2021_Rx" SG_ 1438 GWM_AutoSarNMReserved4 1;
BA_ "U_U55X_MY2022_Rx" SG_ 1438 GWM_AutoSarNMReserved4 1;
BA_ "U_T6_MCA_MY2020_Rx" SG_ 1438 GWM_AutoSarNMReserved4 1;
BA_ "U_P702_MY2021_Rx" SG_ 1438 GWM_AutoSarNMReserved4 1;
BA_ "GenSigStartValue" SG_ 1438 GWM_AutoSarNMReserved4 255;
BA_ "ContentDependant" SG_ 1438 GWM_AutoSarNMReserved4 1;
BA_ "GenSigStartValueInteger" SG_ 1438 GWM_AutoSarNMReserved4 255;
BA_ "U_U55X_MY2022_Tx" SG_ 1438 GWM_AutoSarNMReserved3 1;
BA_ "U_CD542_MY2021_Tx" SG_ 1438 GWM_AutoSarNMReserved3 1;
BA_ "ECGUsedTxSignal" SG_ 1438 GWM_AutoSarNMReserved3 1;
BA_ "U_T6_MCA_MY2020_Tx" SG_ 1438 GWM_AutoSarNMReserved3 1;
BA_ "U_CD542_MY2021_Rx" SG_ 1438 GWM_AutoSarNMReserved3 1;
BA_ "U_U55X_MY2022_Rx" SG_ 1438 GWM_AutoSarNMReserved3 1;
BA_ "U_T6_MCA_MY2020_Rx" SG_ 1438 GWM_AutoSarNMReserved3 1;
BA_ "U_P702_MY2021_Rx" SG_ 1438 GWM_AutoSarNMReserved3 1;
BA_ "GenSigStartValue" SG_ 1438 GWM_AutoSarNMReserved3 255;
BA_ "ContentDependant" SG_ 1438 GWM_AutoSarNMReserved3 1;
BA_ "GenSigStartValueInteger" SG_ 1438 GWM_AutoSarNMReserved3 255;
BA_ "U_U55X_MY2022_Tx" SG_ 1438 GWM_AutoSarNMReserved2 1;
BA_ "U_CD542_MY2021_Tx" SG_ 1438 GWM_AutoSarNMReserved2 1;
BA_ "ECGUsedTxSignal" SG_ 1438 GWM_AutoSarNMReserved2 1;
BA_ "U_T6_MCA_MY2020_Tx" SG_ 1438 GWM_AutoSarNMReserved2 1;
BA_ "U_CD542_MY2021_Rx" SG_ 1438 GWM_AutoSarNMReserved2 1;
BA_ "U_U55X_MY2022_Rx" SG_ 1438 GWM_AutoSarNMReserved2 1;
BA_ "U_T6_MCA_MY2020_Rx" SG_ 1438 GWM_AutoSarNMReserved2 1;
BA_ "U_P702_MY2021_Rx" SG_ 1438 GWM_AutoSarNMReserved2 1;
BA_ "GenSigStartValue" SG_ 1438 GWM_AutoSarNMReserved2 255;
BA_ "ContentDependant" SG_ 1438 GWM_AutoSarNMReserved2 1;
BA_ "GenSigStartValueInteger" SG_ 1438 GWM_AutoSarNMReserved2 255;
BA_ "U_U55X_MY2022_Tx" SG_ 1438 GWM_AutoSarNMReserved1 1;
BA_ "U_CD542_MY2021_Tx" SG_ 1438 GWM_AutoSarNMReserved1 1;
BA_ "ECGUsedTxSignal" SG_ 1438 GWM_AutoSarNMReserved1 1;
BA_ "U_T6_MCA_MY2020_Tx" SG_ 1438 GWM_AutoSarNMReserved1 1;
BA_ "U_CD542_MY2021_Rx" SG_ 1438 GWM_AutoSarNMReserved1 1;
BA_ "U_U55X_MY2022_Rx" SG_ 1438 GWM_AutoSarNMReserved1 1;
BA_ "U_T6_MCA_MY2020_Rx" SG_ 1438 GWM_AutoSarNMReserved1 1;
BA_ "U_P702_MY2021_Rx" SG_ 1438 GWM_AutoSarNMReserved1 1;
BA_ "GenSigStartValue" SG_ 1438 GWM_AutoSarNMReserved1 255;
BA_ "ContentDependant" SG_ 1438 GWM_AutoSarNMReserved1 1;
BA_ "GenSigStartValueInteger" SG_ 1438 GWM_AutoSarNMReserved1 255;
BA_ "U_U55X_MY2022_Tx" SG_ 1438 GWM_AutoSarNMNodeId 1;
BA_ "U_CD542_MY2021_Tx" SG_ 1438 GWM_AutoSarNMNodeId 1;
BA_ "ECGUsedTxSignal" SG_ 1438 GWM_AutoSarNMNodeId 1;
BA_ "U_T6_MCA_MY2020_Tx" SG_ 1438 GWM_AutoSarNMNodeId 1;
BA_ "U_CD542_MY2021_Rx" SG_ 1438 GWM_AutoSarNMNodeId 1;
BA_ "U_U55X_MY2022_Rx" SG_ 1438 GWM_AutoSarNMNodeId 1;
BA_ "U_T6_MCA_MY2020_Rx" SG_ 1438 GWM_AutoSarNMNodeId 1;
BA_ "U_P702_MY2021_Rx" SG_ 1438 GWM_AutoSarNMNodeId 1;
BA_ "GenSigStartValue" SG_ 1438 GWM_AutoSarNMNodeId 158;
BA_ "ContentDependant" SG_ 1438 GWM_AutoSarNMNodeId 1;
BA_ "GenSigStartValueInteger" SG_ 1438 GWM_AutoSarNMNodeId 158;
BA_ "U_U55X_MY2022_Tx" SG_ 1438 GWM_AutoSarNMControl 1;
BA_ "U_CD542_MY2021_Tx" SG_ 1438 GWM_AutoSarNMControl 1;
BA_ "ECGUsedTxSignal" SG_ 1438 GWM_AutoSarNMControl 1;
BA_ "U_T6_MCA_MY2020_Tx" SG_ 1438 GWM_AutoSarNMControl 1;
BA_ "U_CD542_MY2021_Rx" SG_ 1438 GWM_AutoSarNMControl 1;
BA_ "U_U55X_MY2022_Rx" SG_ 1438 GWM_AutoSarNMControl 1;
BA_ "U_T6_MCA_MY2020_Rx" SG_ 1438 GWM_AutoSarNMControl 1;
BA_ "U_P702_MY2021_Rx" SG_ 1438 GWM_AutoSarNMControl 1;
BA_ "ContentDependant" SG_ 1438 GWM_AutoSarNMControl 1;
BA_ "U_U55X_MY2022_Rx" SG_ 76 RstrnPsngrOn_D_Stat 1;
BA_ "U_CD542_MY2021_Rx" SG_ 76 RstrnPsngrOn_D_Stat 1;
BA_ "U_T6_MCA_MY2020_Rx" SG_ 76 RstrnPsngrOn_D_Stat 1;
BA_ "MetaData" SG_ 76 FirstRowBuckle_No_Cs 1;
BA_ "MetaData" SG_ 76 RCMStatusMsg2_No_Cnt 1;
BA_ "U_CD542_MY2021_Rx" SG_ 76 PsngrFmidDetct_D_Actl 1;
BA_ "U_T6_MCA_MY2020_Rx" SG_ 76 PsngrFmidDetct_D_Actl 1;
BA_ "GenSigStartValue" SG_ 76 PsngrFmidDetct_D_Actl 3;
BA_ "GenSigStartValueInteger" SG_ 76 PsngrFmidDetct_D_Actl 3;
BA_ "U_U55X_MY2022_Rx" SG_ 76 FirstRowBuckleMid 1;
BA_ "U_CD542_MY2021_Rx" SG_ 76 FirstRowBuckleMid 1;
BA_ "U_T6_MCA_MY2020_Rx" SG_ 76 FirstRowBuckleMid 1;
BA_ "U_P702_MY2021_Rx" SG_ 76 FirstRowBuckleMid 1;
BA_ "GenSigStartValue" SG_ 76 FirstRowBuckleMid 3;
BA_ "GenSigStartValueInteger" SG_ 76 FirstRowBuckleMid 3;
BA_ "U_U55X_MY2022_Rx" SG_ 76 ThirdRowBucklePsngr 1;
BA_ "U_CD542_MY2021_Rx" SG_ 76 ThirdRowBucklePsngr 1;
BA_ "U_T6_MCA_MY2020_Rx" SG_ 76 ThirdRowBucklePsngr 1;
BA_ "GenSigStartValue" SG_ 76 ThirdRowBucklePsngr 3;
BA_ "GenSigStartValueInteger" SG_ 76 ThirdRowBucklePsngr 3;
BA_ "U_U55X_MY2022_Rx" SG_ 76 ThirdRowBuckleMid 1;
BA_ "U_CD542_MY2021_Rx" SG_ 76 ThirdRowBuckleMid 1;
BA_ "U_T6_MCA_MY2020_Rx" SG_ 76 ThirdRowBuckleMid 1;
BA_ "GenSigStartValue" SG_ 76 ThirdRowBuckleMid 3;
BA_ "GenSigStartValueInteger" SG_ 76 ThirdRowBuckleMid 3;
BA_ "U_U55X_MY2022_Rx" SG_ 76 ThirdRowBuckleDriver 1;
BA_ "U_CD542_MY2021_Rx" SG_ 76 ThirdRowBuckleDriver 1;
BA_ "U_T6_MCA_MY2020_Rx" SG_ 76 ThirdRowBuckleDriver 1;
BA_ "GenSigStartValue" SG_ 76 ThirdRowBuckleDriver 3;
BA_ "GenSigStartValueInteger" SG_ 76 ThirdRowBuckleDriver 3;
BA_ "U_U55X_MY2022_Rx" SG_ 76 SecondRowBucklePsngr 1;
BA_ "U_CD542_MY2021_Rx" SG_ 76 SecondRowBucklePsngr 1;
BA_ "U_T6_MCA_MY2020_Rx" SG_ 76 SecondRowBucklePsngr 1;
BA_ "U_P702_MY2021_Rx" SG_ 76 SecondRowBucklePsngr 1;
BA_ "GenSigStartValue" SG_ 76 SecondRowBucklePsngr 3;
BA_ "GenSigStartValueInteger" SG_ 76 SecondRowBucklePsngr 3;
BA_ "U_U55X_MY2022_Rx" SG_ 76 SecondRowBuckleMid 1;
BA_ "U_CD542_MY2021_Rx" SG_ 76 SecondRowBuckleMid 1;
BA_ "U_T6_MCA_MY2020_Rx" SG_ 76 SecondRowBuckleMid 1;
BA_ "U_P702_MY2021_Rx" SG_ 76 SecondRowBuckleMid 1;
BA_ "GenSigStartValue" SG_ 76 SecondRowBuckleMid 3;
BA_ "GenSigStartValueInteger" SG_ 76 SecondRowBuckleMid 3;
BA_ "U_U55X_MY2022_Rx" SG_ 76 SecondRowBuckleDriver 1;
BA_ "U_CD542_MY2021_Rx" SG_ 76 SecondRowBuckleDriver 1;
BA_ "U_T6_MCA_MY2020_Rx" SG_ 76 SecondRowBuckleDriver 1;
BA_ "U_P702_MY2021_Rx" SG_ 76 SecondRowBuckleDriver 1;
BA_ "GenSigStartValue" SG_ 76 SecondRowBuckleDriver 3;
BA_ "GenSigStartValueInteger" SG_ 76 SecondRowBuckleDriver 3;
BA_ "U_U55X_MY2022_Rx" SG_ 76 FirstRowBuckleDriver 1;
BA_ "U_CD542_MY2021_Rx" SG_ 76 FirstRowBuckleDriver 1;
BA_ "U_T6_MCA_MY2020_Rx" SG_ 76 FirstRowBuckleDriver 1;
BA_ "U_P702_MY2021_Rx" SG_ 76 FirstRowBuckleDriver 1;
BA_ "GenSigStartValue" SG_ 76 FirstRowBuckleDriver 3;
BA_ "GenSigStartValueInteger" SG_ 76 FirstRowBuckleDriver 3;
BA_ "U_U55X_MY2022_Rx" SG_ 76 RILReq 1;
BA_ "U_CD542_MY2021_Rx" SG_ 76 RILReq 1;
BA_ "U_T6_MCA_MY2020_Rx" SG_ 76 RILReq 1;
BA_ "U_P702_MY2021_Rx" SG_ 76 RILReq 1;
BA_ "U_U55X_MY2022_Rx" SG_ 76 FirstRowBucklePsngr 1;
BA_ "U_CD542_MY2021_Rx" SG_ 76 FirstRowBucklePsngr 1;
BA_ "U_T6_MCA_MY2020_Rx" SG_ 76 FirstRowBucklePsngr 1;
BA_ "U_P702_MY2021_Rx" SG_ 76 FirstRowBucklePsngr 1;
BA_ "GenSigStartValue" SG_ 76 FirstRowBucklePsngr 3;
BA_ "GenSigStartValueInteger" SG_ 76 FirstRowBucklePsngr 3;
BA_ "U_CD542_MY2021_Rx" SG_ 76 RstrnImpactEvntStatus 1;
BA_ "U_U55X_MY2022_Rx" SG_ 76 RstrnImpactEvntStatus 1;
BA_ "U_T6_MCA_MY2020_Rx" SG_ 76 RstrnImpactEvntStatus 1;
BA_ "WakeupSignal" SG_ 76 RstrnImpactEvntStatus 1;
BA_ "U_U55X_MY2022_Rx" SG_ 76 PsngrFrntDetct_D_Actl 1;
BA_ "U_CD542_MY2021_Rx" SG_ 76 PsngrFrntDetct_D_Actl 1;
BA_ "U_T6_MCA_MY2020_Rx" SG_ 76 PsngrFrntDetct_D_Actl 1;
BA_ "GenSigStartValue" SG_ 76 PsngrFrntDetct_D_Actl 3;
BA_ "GenSigStartValueInteger" SG_ 76 PsngrFrntDetct_D_Actl 3;
BA_ "GenSigStartValue" SG_ 76 PassRstrnInd_Req 3;
BA_ "GenSigStartValueInteger" SG_ 76 PassRstrnInd_Req 3;
BA_ "U_U55X_MY2022_Rx" SG_ 76 EDRTriggerEvntSync 1;
BA_ "U_CD542_MY2021_Rx" SG_ 76 EDRTriggerEvntSync 1;
BA_ "U_T6_MCA_MY2020_Rx" SG_ 76 EDRTriggerEvntSync 1;
BA_ "U_U55X_MY2022_Rx" SG_ 1034 VehicleGGCCData 1;
BA_ "U_CD542_MY2021_Rx" SG_ 1034 VehicleGGCCData 1;
BA_ "U_T6_MCA_MY2020_Rx" SG_ 1034 VehicleGGCCData 1;
BA_ "U_P702_MY2021_Rx" SG_ 1034 VehicleGGCCData 1;
BA_ "U_U55X_MY2022_Rx" SG_ 1069 IsaOffst_D_Stat 1;
BA_ "U_CD542_MY2021_Rx" SG_ 1069 IsaOffst_D_Stat 1;
BA_ "U_T6_MCA_MY2020_Rx" SG_ 1069 IsaOffst_D_Stat 1;
BA_ "U_U55X_MY2022_Rx" SG_ 1069 ReFuelSysStat_D_Dsply 1;
BA_ "U_CD542_MY2021_Rx" SG_ 1069 ReFuelSysStat_D_Dsply 1;
BA_ "U_P702_MY2021_Rx" SG_ 1069 ReFuelSysStat_D_Dsply 1;
BA_ "WakeupSignal" SG_ 1069 ReFuelSysStat_D_Dsply 1;
BA_ "U_U55X_MY2022_Rx" SG_ 1069 SlMde_D_Stat 1;
BA_ "U_CD542_MY2021_Rx" SG_ 1069 SlMde_D_Stat 1;
BA_ "U_T6_MCA_MY2020_Rx" SG_ 1069 SlMde_D_Stat 1;
BA_ "U_U55X_MY2022_Rx" SG_ 1069 SlMde_D_RqDsply 1;
BA_ "U_CD542_MY2021_Rx" SG_ 1069 SlMde_D_RqDsply 1;
BA_ "U_T6_MCA_MY2020_Rx" SG_ 1069 SlMde_D_RqDsply 1;
BA_ "U_CD542_MY2021_Rx" SG_ 1069 ULoSrcOnPlg_B_Cmd 1;
BA_ "U_CD542_MY2021_Rx" SG_ 1069 EngAirIn_Te_Actl 1;
BA_ "U_T6_MCA_MY2020_Rx" SG_ 1069 EngAirIn_Te_Actl 1;
BA_ "U_CD542_MY2021_Rx" SG_ 1069 GrllShtrPos_B_Falt 1;
BA_ "U_T6_MCA_MY2020_Rx" SG_ 1069 GrllShtrPos_B_Falt 1;
BA_ "U_U55X_MY2022_Rx" SG_ 1069 EngMsgTxt_D_Rq 1;
BA_ "U_CD542_MY2021_Rx" SG_ 1069 EngMsgTxt_D_Rq 1;
BA_ "U_T6_MCA_MY2020_Rx" SG_ 1069 EngMsgTxt_D_Rq 1;
BA_ "U_P702_MY2021_Rx" SG_ 1069 EngMsgTxt_D_Rq 1;
BA_ "ContentDependant" SG_ 1069 EngMsgTxt_D_Rq 1;
BA_ "U_CD542_MY2021_Rx" SG_ 1069 EngClnt_Te_ActlDiag 1;
BA_ "ContentDependant" SG_ 1069 EngClnt_Te_ActlDiag 1;
BA_ "U_CD542_MY2021_Rx" SG_ 1069 ThrPos_Pc_CalcDiag 1;
BA_ "U_CD542_MY2021_Rx" SG_ 1069 EngLoad_Pc_CalcDiag 1;
BA_ "ContentDependant" SG_ 1069 EngLoad_Pc_CalcDiag 1;
BA_ "U_CD542_MY2021_Rx" SG_ 1069 ApedPos_Pc_ActlDiag 1;
BA_ "ContentDependant" SG_ 1069 ApedPos_Pc_ActlDiag 1;
BA_ "U_CD542_MY2021_Rx" SG_ 1069 TracKeyMdeEnbl_B_Stat 1;
BA_ "ContentDependant" SG_ 1069 ObdWarmUp_B_Complt 1;
BA_ "U_CD542_MY2021_Rx" SG_ 1069 GrllShtrPos_D_Cmd 1;
BA_ "U_T6_MCA_MY2020_Rx" SG_ 1069 GrllShtrPos_D_Cmd 1;
BA_ "U_CD542_MY2021_Rx" SG_ 1057 FohEng_D_Rq 1;
BA_ "GenSigStartValue" SG_ 1057 FohEng_D_Rq 2;
BA_ "ContentDependant" SG_ 1057 FohEng_D_Rq 1;
BA_ "GenSigStartValueInteger" SG_ 1057 FohEng_D_Rq 2;
BA_ "U_CD542_MY2021_Rx" SG_ 1057 EngIdlShutDwnTxt_D_Rq 1;
BA_ "U_T6_MCA_MY2020_Rx" SG_ 1057 EngIdlShutDwnTxt_D_Rq 1;
BA_ "U_U55X_MY2022_Rx" SG_ 1057 EngIdlShutDown_D_Stat 1;
BA_ "U_CD542_MY2021_Rx" SG_ 1057 EngIdlShutDown_D_Stat 1;
BA_ "U_T6_MCA_MY2020_Rx" SG_ 1057 EngIdlShutDown_D_Stat 1;
BA_ "U_P702_MY2021_Rx" SG_ 1057 EngIdlShutDown_D_Stat 1;
BA_ "ContentDependant" SG_ 1057 EngIdlShutDown_D_Stat 1;
BA_ "U_CD542_MY2021_Rx" SG_ 1057 FUEL_ALCOHOL_PERCNT 1;
BA_ "U_T6_MCA_MY2020_Rx" SG_ 1057 FUEL_ALCOHOL_PERCNT 1;
BA_ "U_P702_MY2021_Rx" SG_ 1057 FUEL_ALCOHOL_PERCNT 1;
BA_ "GenSigStartValue" SG_ 1057 FUEL_ALCOHOL_PERCNT 255;
BA_ "ContentDependant" SG_ 1057 FUEL_ALCOHOL_PERCNT 1;
BA_ "GenSigStartValueInteger" SG_ 1057 FUEL_ALCOHOL_PERCNT 255;
BA_ "U_CD542_MY2021_Rx" SG_ 1057 TrnTotTq_Rt_Est 1;
BA_ "ContentDependant" SG_ 1057 TrnTotTq_Rt_Est 1;
BA_ "U_CD542_MY2021_Rx" SG_ 1057 TrnTotLss_Tq_Est 1;
BA_ "ContentDependant" SG_ 1057 TrnTotLss_Tq_Est 1;
BA_ "U_U55X_MY2022_Rx" SG_ 1057 ECMMILRequest 1;
BA_ "U_CD542_MY2021_Rx" SG_ 1057 ECMMILRequest 1;
BA_ "U_T6_MCA_MY2020_Rx" SG_ 1057 ECMMILRequest 1;
BA_ "U_P702_MY2021_Rx" SG_ 1057 ECMMILRequest 1;
BA_ "U_CD542_MY2021_Rx" SG_ 1057 AirCondFluidHi_P_Actl 1;
BA_ "U_T6_MCA_MY2020_Rx" SG_ 1057 AirCondFluidHi_P_Actl 1;
BA_ "U_U55X_MY2022_Rx" SG_ 1057 OilPressureWarning 1;
BA_ "U_CD542_MY2021_Rx" SG_ 1057 OilPressureWarning 1;
BA_ "U_T6_MCA_MY2020_Rx" SG_ 1057 OilPressureWarning 1;
BA_ "U_P702_MY2021_Rx" SG_ 1057 OilPressureWarning 1;
BA_ "U_CD542_MY2021_Rx" SG_ 1057 VehVLimStat_D_Actl 1;
BA_ "ContentDependant" SG_ 1057 VehVLimStat_D_Actl 1;
BA_ "U_CD542_MY2021_Rx" SG_ 1057 VehVLimActv_B_Actl 1;
BA_ "ContentDependant" SG_ 1057 VehVLimActv_B_Actl 1;
BA_ "U_CD542_MY2021_Rx" SG_ 1057 CoolantFanStepAct 1;
BA_ "U_T6_MCA_MY2020_Rx" SG_ 1057 CoolantFanStepAct 1;
BA_ "GenSigStartValue" SG_ 516 EngAoutNActl_D_QF 1;
BA_ "MetaData" SG_ 516 EngAoutNActl_D_QF 1;
BA_ "GenSigStartValueInteger" SG_ 516 EngAoutNActl_D_QF 1;
BA_ "U_U55X_MY2022_Rx" SG_ 516 ApedPos_PcRate_ActlArb 1;
BA_ "U_U55X_MY2022_Rx" SG_ 516 ApedPos_Pc_ActlArb 1;
BA_ "U_CD542_MY2021_Rx" SG_ 516 ApedPos_Pc_ActlArb 1;
BA_ "U_T6_MCA_MY2020_Rx" SG_ 516 ApedPos_Pc_ActlArb 1;
BA_ "U_P702_MY2021_Rx" SG_ 516 ApedPos_Pc_ActlArb 1;
BA_ "U_CD542_MY2021_Rx" SG_ 516 ApedPosPcActl_D_Qf 1;
BA_ "U_T6_MCA_MY2020_Rx" SG_ 516 ApedPosPcActl_D_Qf 1;
BA_ "U_P702_MY2021_Rx" SG_ 516 ApedPosPcActl_D_Qf 1;
BA_ "GenSigStartValue" SG_ 516 ApedPosPcActl_D_Qf 1;
BA_ "MetaData" SG_ 516 ApedPosPcActl_D_Qf 1;
BA_ "GenSigStartValueInteger" SG_ 516 ApedPosPcActl_D_Qf 1;
BA_ "U_U55X_MY2022_Rx" SG_ 516 EngAout_N_Actl 1;
BA_ "U_CD542_MY2021_Rx" SG_ 516 EngAout_N_Actl 1;
BA_ "U_T6_MCA_MY2020_Rx" SG_ 516 EngAout_N_Actl 1;
BA_ "U_P702_MY2021_Rx" SG_ 516 EngAout_N_Actl 1;
BA_ "MetaData" SG_ 516 ApedPosPcActl_No_Cs 1;
BA_ "ContentDependant" SG_ 516 ApedPosPcActl_No_Cs 1;
BA_ "ContentDependant" SG_ 516 EngAout3_N_Actl 1;
BA_ "MetaData" SG_ 516 ApedPosPcActl_No_Cnt 1;
BA_ "ContentDependant" SG_ 516 ApedPosPcActl_No_Cnt 1;
BA_ "U_U55X_MY2022_Rx" SG_ 514 StrtrMtrCtlMsgTxt_D_Rq 1;
BA_ "U_CD542_MY2021_Rx" SG_ 514 StrtrMtrCtlMsgTxt_D_Rq 1;
BA_ "U_T6_MCA_MY2020_Rx" SG_ 514 StrtrMtrCtlMsgTxt_D_Rq 1;
BA_ "U_P702_MY2021_Rx" SG_ 514 StrtrMtrCtlMsgTxt_D_Rq 1;
BA_ "MetaData" SG_ 514 VehVActlEng_No_Cs 1;
BA_ "MetaData" SG_ 514 VehVActlEng_No_Cnt 1;
BA_ "U_U55X_MY2022_Rx" SG_ 514 GearRvrse_D_Actl 1;
BA_ "U_CD542_MY2021_Rx" SG_ 514 GearRvrse_D_Actl 1;
BA_ "U_T6_MCA_MY2020_Rx" SG_ 514 GearRvrse_D_Actl 1;
BA_ "U_P702_MY2021_Rx" SG_ 514 GearRvrse_D_Actl 1;
BA_ "GenSigStartValue" SG_ 514 GearRvrse_D_Actl 7;
BA_ "GenSigStartValueInteger" SG_ 514 GearRvrse_D_Actl 7;
BA_ "U_U55X_MY2022_Rx" SG_ 514 Veh_V_RqCcSet 1;
BA_ "U_CD542_MY2021_Rx" SG_ 514 Veh_V_RqCcSet 1;
BA_ "U_T6_MCA_MY2020_Rx" SG_ 514 Veh_V_RqCcSet 1;
BA_ "U_P702_MY2021_Rx" SG_ 514 Veh_V_RqCcSet 1;
BA_ "U_U55X_MY2022_Rx" SG_ 514 VehVActlEng_D_Qf 1;
BA_ "U_CD542_MY2021_Rx" SG_ 514 VehVActlEng_D_Qf 1;
BA_ "U_T6_MCA_MY2020_Rx" SG_ 514 VehVActlEng_D_Qf 1;
BA_ "U_P702_MY2021_Rx" SG_ 514 VehVActlEng_D_Qf 1;
BA_ "MetaData" SG_ 514 VehVActlEng_D_Qf 1;
BA_ "U_U55X_MY2022_Rx" SG_ 514 Veh_V_ActlEng 1;
BA_ "U_CD542_MY2021_Rx" SG_ 514 Veh_V_ActlEng 1;
BA_ "U_T6_MCA_MY2020_Rx" SG_ 514 Veh_V_ActlEng 1;
BA_ "U_P702_MY2021_Rx" SG_ 514 Veh_V_ActlEng 1;
BA_ "ContentDependant" SG_ 514 EngAout_Tq_VacLimSpcN 1;
BA_ "ContentDependant" SG_ 514 EngCylSync_No_Ctr 1;
BA_ "U_U55X_MY2022_Rx" SG_ 514 StrtrMtrCtlMsgTxt_D2_Rq 1;
BA_ "U_CD542_MY2021_Rx" SG_ 514 StrtrMtrCtlMsgTxt_D2_Rq 1;
BA_ "U_T6_MCA_MY2020_Rx" SG_ 514 StrtrMtrCtlMsgTxt_D2_Rq 1;
BA_ "U_U55X_MY2022_Rx" SG_ 381 EngOilLife_T_Actl 1;
BA_ "U_CD542_MY2021_Rx" SG_ 381 EngOilLife_T_Actl 1;
BA_ "U_T6_MCA_MY2020_Rx" SG_ 381 EngOilLife_T_Actl 1;
BA_ "U_U55X_MY2022_Rx" SG_ 381 EngOilSrvcMsgTxt_D_Rq 1;
BA_ "U_CD542_MY2021_Rx" SG_ 381 EngOilSrvcMsgTxt_D_Rq 1;
BA_ "U_T6_MCA_MY2020_Rx" SG_ 381 EngOilSrvcMsgTxt_D_Rq 1;
BA_ "U_CD542_MY2021_Rx" SG_ 381 RunDryPrevent_B_Stat 1;
BA_ "U_T6_MCA_MY2020_Rx" SG_ 381 RunDryPrevent_B_Stat 1;
BA_ "U_P702_MY2021_Rx" SG_ 381 RunDryPrevent_B_Stat 1;
BA_ "U_U55X_MY2022_Rx" SG_ 381 DistToNextOilChange 1;
BA_ "U_CD542_MY2021_Rx" SG_ 381 DistToNextOilChange 1;
BA_ "U_T6_MCA_MY2020_Rx" SG_ 381 DistToNextOilChange 1;
BA_ "U_CD542_MY2021_Rx" SG_ 381 Eng_Aa_CalcEvntCyc 1;
BA_ "U_T6_MCA_MY2020_Rx" SG_ 381 WaterInFuel 1;
BA_ "U_P702_MY2021_Rx" SG_ 381 WaterInFuel 1;
BA_ "U_CD542_MY2021_Rx" SG_ 381 GlowIndication 1;
BA_ "U_T6_MCA_MY2020_Rx" SG_ 381 GlowIndication 1;
BA_ "U_P702_MY2021_Rx" SG_ 381 GlowIndication 1;
BA_ "U_CD542_MY2021_Rx" SG_ 380 GrdAsstAllw_D_DsplyPt 1;
BA_ "U_T6_MCA_MY2020_Rx" SG_ 380 GrdAsstAllw_D_DsplyPt 1;
BA_ "GenSigStartValue" SG_ 380 GrdAsstAllw_D_DsplyPt 1;
BA_ "GenSigStartValueInteger" SG_ 380 GrdAsstAllw_D_DsplyPt 1;
BA_ "U_U55X_MY2022_Rx" SG_ 380 EngOilLvlWarn_D_Rq1 1;
BA_ "U_CD542_MY2021_Rx" SG_ 380 EngOilLvlWarn_D_Rq1 1;
BA_ "U_T6_MCA_MY2020_Rx" SG_ 380 EngOilLvlWarn_D_Rq1 1;
BA_ "U_P702_MY2021_Rx" SG_ 380 EngOilLvlWarn_D_Rq1 1;
BA_ "WakeupSignal" SG_ 380 EngOilLvlWarn_D_Rq1 1;
BA_ "U_U55X_MY2022_Rx" SG_ 380 EngExhBrkOnLamp_B_Rq 1;
BA_ "U_CD542_MY2021_Rx" SG_ 380 EngExhBrkOnLamp_B_Rq 1;
BA_ "U_T6_MCA_MY2020_Rx" SG_ 380 EngExhBrkOnLamp_B_Rq 1;
BA_ "U_P702_MY2021_Rx" SG_ 380 EngExhBrkOnLamp_B_Rq 1;
BA_ "U_U55X_MY2022_Rx" SG_ 380 EngExhBrkAutoLamp_B_Rq 1;
BA_ "U_CD542_MY2021_Rx" SG_ 380 EngExhBrkAutoLamp_B_Rq 1;
BA_ "U_T6_MCA_MY2020_Rx" SG_ 380 EngExhBrkAutoLamp_B_Rq 1;
BA_ "U_P702_MY2021_Rx" SG_ 380 EngExhBrkAutoLamp_B_Rq 1;
BA_ "U_CD542_MY2021_Rx" SG_ 380 EngAout_N_MxAllw 1;
BA_ "MetaData" SG_ 380 EngAoutIdlRqEc_No_Cs 1;
BA_ "MetaData" SG_ 380 EngAoutIdlRqEc_No_Cnt 1;
BA_ "U_CD542_MY2021_Rx" SG_ 380 EngExhBrkMde_D_Actl 1;
BA_ "U_U55X_MY2022_Rx" SG_ 377 TrnManShif_D_IndDrv 1;
BA_ "U_CD542_MY2021_Rx" SG_ 377 TrnManShif_D_IndDrv 1;
BA_ "U_T6_MCA_MY2020_Rx" SG_ 377 TrnManShif_D_IndDrv 1;
BA_ "U_CD542_MY2021_Rx" SG_ 377 EngFuelCutFull_B_Inhbt 1;
BA_ "ContentDependant" SG_ 377 EngFuelCutFull_B_Inhbt 1;
BA_ "U_CD542_MY2021_Rx" SG_ 377 EngDecelFuelCut_B_Allw 1;
BA_ "U_P702_MY2021_Rx" SG_ 377 EngAout_Tq_Actl 1;
BA_ "U_U55X_MY2022_Rx" SG_ 377 EngAout_Tq_Actl 1;
BA_ "U_CD542_MY2021_Rx" SG_ 377 EngAout_Tq_Actl 1;
BA_ "U_U55X_MY2022_Rx" SG_ 377 TrnManShifGear_D_IndDrv 1;
BA_ "U_CD542_MY2021_Rx" SG_ 377 TrnManShifGear_D_IndDrv 1;
BA_ "U_T6_MCA_MY2020_Rx" SG_ 377 TrnManShifGear_D_IndDrv 1;
BA_ "U_U55X_MY2022_Rx" SG_ 377 FuelFlw_Vl_Dsply 1;
BA_ "U_CD542_MY2021_Rx" SG_ 377 FuelFlw_Vl_Dsply 1;
BA_ "U_T6_MCA_MY2020_Rx" SG_ 377 FuelFlw_Vl_Dsply 1;
BA_ "U_P702_MY2021_Rx" SG_ 377 FuelFlw_Vl_Dsply 1;
BA_ "ContentDependant" SG_ 377 FuelFlw_Vl_Dsply 1;
BA_ "U_U55X_MY2022_Rx" SG_ 377 FuelFillInlet_B_Dsply 1;
BA_ "U_CD542_MY2021_Rx" SG_ 377 FuelFillInlet_B_Dsply 1;
BA_ "U_T6_MCA_MY2020_Rx" SG_ 377 FuelFillInlet_B_Dsply 1;
BA_ "U_P702_MY2021_Rx" SG_ 377 FuelFillInlet_B_Dsply 1;
BA_ "ContentDependant" SG_ 377 FuelFillInlet_B_Dsply 1;
BA_ "U_U55X_MY2022_Rx" SG_ 377 EngSrvcRqd_B_Rq 1;
BA_ "U_CD542_MY2021_Rx" SG_ 377 EngSrvcRqd_B_Rq 1;
BA_ "U_T6_MCA_MY2020_Rx" SG_ 377 EngSrvcRqd_B_Rq 1;
BA_ "U_U55X_MY2022_Rx" SG_ 377 OdoCount 1;
BA_ "U_CD542_MY2021_Rx" SG_ 377 OdoCount 1;
BA_ "U_T6_MCA_MY2020_Rx" SG_ 377 OdoCount 1;
BA_ "U_P702_MY2021_Rx" SG_ 377 OdoCount 1;
BA_ "ContentDependant" SG_ 377 OdoCount 1;
BA_ "U_U55X_MY2022_Rx" SG_ 377 EngOilLife_Pc_Actl 1;
BA_ "U_CD542_MY2021_Rx" SG_ 377 EngOilLife_Pc_Actl 1;
BA_ "U_T6_MCA_MY2020_Rx" SG_ 377 EngOilLife_Pc_Actl 1;
BA_ "U_P702_MY2021_Rx" SG_ 377 EngOilLife_Pc_Actl 1;
BA_ "ContentDependant" SG_ 377 EngOilLife_Pc_Actl 1;
BA_ "U_CD542_MY2021_Rx" SG_ 377 TrnKickDown_B_RqDrv 1;
BA_ "ContentDependant" SG_ 377 TrnKickDown_B_RqDrv 1;
BA_ "U_U55X_MY2022_Rx" SG_ 377 FuelFilterLamp_B_Dsply 1;
BA_ "U_CD542_MY2021_Rx" SG_ 377 FuelFilterLamp_B_Dsply 1;
BA_ "U_T6_MCA_MY2020_Rx" SG_ 377 FuelFilterLamp_B_Dsply 1;
BA_ "U_P702_MY2021_Rx" SG_ 377 FuelFilterLamp_B_Dsply 1;
BA_ "U_CD542_MY2021_Rx" SG_ 377 AirCondRec_B_Rq 1;
BA_ "U_T6_MCA_MY2020_Rx" SG_ 377 AirCondRec_B_Rq 1;
BA_ "ContentDependant" SG_ 377 AirCondRec_B_Rq 1;
BA_ "U_U55X_MY2022_Rx" SG_ 377 AirCondClutch_B_Stats 1;
BA_ "U_CD542_MY2021_Rx" SG_ 377 AirCondClutch_B_Stats 1;
BA_ "U_T6_MCA_MY2020_Rx" SG_ 377 AirCondClutch_B_Stats 1;
BA_ "ContentDependant" SG_ 377 AirCondClutch_B_Stats 1;
BA_ "U_CD542_MY2021_Rx" SG_ 377 EngAoutTqActl_D_Qf 1;
BA_ "MetaData" SG_ 377 EngAoutTqActl_D_Qf 1;
BA_ "U_U55X_MY2022_Rx" SG_ 376 GasPrtc_D_RqDsply 1;
BA_ "U_CD542_MY2021_Rx" SG_ 376 GasPrtc_D_RqDsply 1;
BA_ "U_T6_MCA_MY2020_Rx" SG_ 376 GasPrtc_D_RqDsply 1;
BA_ "U_CD542_MY2021_Rx" SG_ 376 LnchCtlSys_D_Stat 1;
BA_ "U_T6_MCA_MY2020_Rx" SG_ 376 LnchCtlSys_D_Stat 1;
BA_ "ContentDependant" SG_ 376 EngAout_Aa_Actl 1;
BA_ "U_U55X_MY2022_Rx" SG_ 376 AslIconDsply_D_Rq 1;
BA_ "U_CD542_MY2021_Rx" SG_ 376 AslIconDsply_D_Rq 1;
BA_ "U_T6_MCA_MY2020_Rx" SG_ 376 AslIconDsply_D_Rq 1;
BA_ "U_P702_MY2021_Rx" SG_ 376 AslIconDsply_D_Rq 1;
BA_ "U_U55X_MY2022_Rx" SG_ 376 AslChime_B_Rq 1;
BA_ "U_CD542_MY2021_Rx" SG_ 376 AslChime_B_Rq 1;
BA_ "U_T6_MCA_MY2020_Rx" SG_ 376 AslChime_B_Rq 1;
BA_ "U_P702_MY2021_Rx" SG_ 376 AslChime_B_Rq 1;
BA_ "U_U55X_MY2022_Rx" SG_ 376 HvacHtrCore2_Te_Actl 1;
BA_ "U_CD542_MY2021_Rx" SG_ 376 HvacHtrCore2_Te_Actl 1;
BA_ "U_T6_MCA_MY2020_Rx" SG_ 376 HvacHtrCore2_Te_Actl 1;
BA_ "U_P702_MY2021_Rx" SG_ 376 HvacHtrCore2_Te_Actl 1;
BA_ "GenSigStartValueInteger" SG_ 376 HvacHtrCore2_Te_Actl 200;
BA_ "U_U55X_MY2022_Rx" SG_ 376 EcssLamp_D_RqDsply 1;
BA_ "U_CD542_MY2021_Rx" SG_ 376 EcssLamp_D_RqDsply 1;
BA_ "U_T6_MCA_MY2020_Rx" SG_ 376 EcssLamp_D_RqDsply 1;
BA_ "U_P702_MY2021_Rx" SG_ 376 EcssLamp_D_RqDsply 1;
BA_ "U_CD542_MY2021_Rx" SG_ 376 AirAmbTe_D_Qf 1;
BA_ "U_T6_MCA_MY2020_Rx" SG_ 376 AirAmbTe_D_Qf 1;
BA_ "GenSigStartValue" SG_ 376 AirAmbTe_D_Qf 1;
BA_ "MetaData" SG_ 376 AirAmbTe_D_Qf 1;
BA_ "GenSigStartValueInteger" SG_ 376 AirAmbTe_D_Qf 1;
BA_ "U_CD542_MY2021_Rx" SG_ 376 AirAmb_Te_ActlFilt 1;
BA_ "U_T6_MCA_MY2020_Rx" SG_ 376 AirAmb_Te_ActlFilt 1;
BA_ "GenSigStartValueInteger" SG_ 376 AirAmb_Te_ActlFilt 512;
BA_ "U_CD542_MY2021_Rx" SG_ 376 AirAmb_Te_Actl 1;
BA_ "U_T6_MCA_MY2020_Rx" SG_ 376 AirAmb_Te_Actl 1;
BA_ "GenSigStartValueInteger" SG_ 376 AirAmb_Te_Actl 512;
BA_ "U_CD542_MY2021_Rx" SG_ 376 AirAmb_P_Actl 1;
BA_ "U_T6_MCA_MY2020_Rx" SG_ 376 AirAmb_P_Actl 1;
BA_ "U_T6_MCA_MY2020_Rx" SG_ 373 DieslPrtc2_D_RqDsply 1;
BA_ "U_P702_MY2021_Rx" SG_ 373 DieslPrtc2_D_RqDsply 1;
BA_ "U_T6_MCA_MY2020_Rx" SG_ 373 DieslPrtc_D_RqDsply 1;
BA_ "U_T6_MCA_MY2020_Rx" SG_ 373 DieslPrtcRgen_D_Actl 1;
BA_ "U_T6_MCA_MY2020_Rx" SG_ 373 DieslPrtcRgen_D_Rq 1;
BA_ "ContentDependant" SG_ 373 EngFuelCutFull_B_Allw 1;
BA_ "U_CD542_MY2021_Rx" SG_ 373 EngTurboMde_D_Actl 1;
BA_ "U_T6_MCA_MY2020_Rx" SG_ 373 EngTurboMde_D_Actl 1;
BA_ "U_CD542_MY2021_Rx" SG_ 373 EngTeColdPrtct_D_Stats 1;
BA_ "U_T6_MCA_MY2020_Rx" SG_ 373 EngTeColdPrtct_D_Stats 1;
BA_ "U_P702_MY2021_Rx" SG_ 373 EngTeColdPrtct_D_Stats 1;
BA_ "U_CD542_MY2021_Rx" SG_ 373 EngExhOvrTe_B_RqDsply 1;
BA_ "U_T6_MCA_MY2020_Rx" SG_ 373 EngExhOvrTe_B_RqDsply 1;
BA_ "U_P702_MY2021_Rx" SG_ 373 EngExhOvrTe_B_RqDsply 1;
BA_ "U_CD542_MY2021_Rx" SG_ 373 EngPtoMde_D_Rq 1;
BA_ "U_T6_MCA_MY2020_Rx" SG_ 373 EngPtoMde_D_Rq 1;
BA_ "U_CD542_MY2021_Rx" SG_ 355 AutoRgenTxt_B_RqDsply 1;
BA_ "U_T6_MCA_MY2020_Rx" SG_ 355 AutoRgenTxt_B_RqDsply 1;
BA_ "U_P702_MY2021_Rx" SG_ 355 AutoRgenTxt_B_RqDsply 1;
BA_ "U_T6_MCA_MY2020_Rx" SG_ 355 EngPtoMde_D_Actl 1;
BA_ "U_CD542_MY2021_Rx" SG_ 355 ManRgenVeh_V_MinAllw 1;
BA_ "U_T6_MCA_MY2020_Rx" SG_ 355 ManRgenVeh_V_MinAllw 1;
BA_ "U_P702_MY2021_Rx" SG_ 355 ManRgenVeh_V_MinAllw 1;
BA_ "U_CD542_MY2021_Rx" SG_ 355 ManRgenTxt_D_RqDsply 1;
BA_ "U_T6_MCA_MY2020_Rx" SG_ 355 ManRgenTxt_D_RqDsply 1;
BA_ "U_P702_MY2021_Rx" SG_ 355 ManRgenTxt_D_RqDsply 1;
BA_ "U_CD542_MY2021_Rx" SG_ 355 ManRgenSoot_Pc_RqDsply 1;
BA_ "U_T6_MCA_MY2020_Rx" SG_ 355 ManRgenSoot_Pc_RqDsply 1;
BA_ "U_P702_MY2021_Rx" SG_ 355 ManRgenSoot_Pc_RqDsply 1;
BA_ "U_CD542_MY2021_Rx" SG_ 355 ManRgenInhbt_T_RqDsply 1;
BA_ "U_T6_MCA_MY2020_Rx" SG_ 355 ManRgenInhbt_T_RqDsply 1;
BA_ "U_P702_MY2021_Rx" SG_ 355 ManRgenInhbt_T_RqDsply 1;
BA_ "U_CD542_MY2021_Rx" SG_ 355 ManRgenInhbt_Pc_Soot 1;
BA_ "U_T6_MCA_MY2020_Rx" SG_ 355 ManRgenInhbt_Pc_Soot 1;
BA_ "U_P702_MY2021_Rx" SG_ 355 ManRgenInhbt_Pc_Soot 1;
BA_ "U_CD542_MY2021_Rx" SG_ 355 DieslMsgTxt_D_Rq 1;
BA_ "U_T6_MCA_MY2020_Rx" SG_ 355 DieslMsgTxt_D_Rq 1;
BA_ "U_P702_MY2021_Rx" SG_ 355 DieslMsgTxt_D_Rq 1;
BA_ "U_CD542_MY2021_Rx" SG_ 355 ManRgenInhbt_L_RqDsply 1;
BA_ "U_T6_MCA_MY2020_Rx" SG_ 355 ManRgenInhbt_L_RqDsply 1;
BA_ "U_P702_MY2021_Rx" SG_ 355 ManRgenInhbt_L_RqDsply 1;
BA_ "U_T6_MCA_MY2020_Rx" SG_ 342 FuelRange_L2_DsplyEng 1;
BA_ "U_CD542_MY2021_Rx" SG_ 342 HtrLoop_B_Stat 1;
BA_ "U_CD542_MY2021_Rx" SG_ 342 TqmTerrMdeChng_D_Rdy 1;
BA_ "U_T6_MCA_MY2020_Rx" SG_ 342 TqmTerrMdeChng_D_Rdy 1;
BA_ "U_CD542_MY2021_Rx" SG_ 342 TqmTerrMde_D_Actl 1;
BA_ "U_T6_MCA_MY2020_Rx" SG_ 342 TqmTerrMde_D_Actl 1;
BA_ "U_U55X_MY2022_Rx" SG_ 342 EngOvrhtMitgActv_D_Ind 1;
BA_ "U_CD542_MY2021_Rx" SG_ 342 EngOvrhtMitgActv_D_Ind 1;
BA_ "U_T6_MCA_MY2020_Rx" SG_ 342 EngOvrhtMitgActv_D_Ind 1;
BA_ "U_P702_MY2021_Rx" SG_ 342 EngOvrhtMitgActv_D_Ind 1;
BA_ "ContentDependant" SG_ 342 EngOvrhtMitgActv_D_Ind 1;
BA_ "U_CD542_MY2021_Rx" SG_ 342 EngGoutLss_Tq_Est 1;
BA_ "ContentDependant" SG_ 342 EngGoutLss_Tq_Est 1;
BA_ "U_U55X_MY2022_Rx" SG_ 342 EngClntTe_D_Qf 1;
BA_ "U_CD542_MY2021_Rx" SG_ 342 EngClntTe_D_Qf 1;
BA_ "U_T6_MCA_MY2020_Rx" SG_ 342 EngClntTe_D_Qf 1;
BA_ "U_P702_MY2021_Rx" SG_ 342 EngClntTe_D_Qf 1;
BA_ "MetaData" SG_ 342 EngClntTe_D_Qf 1;
BA_ "U_CD542_MY2021_Rx" SG_ 342 EngAcsyArcPmp_Tq_Actl 1;
BA_ "U_CD542_MY2021_Rx" SG_ 342 EngOilLvlDsply_D_Rq 1;
BA_ "U_U55X_MY2022_Rx" SG_ 342 EngOil_Te_Actl 1;
BA_ "U_P702_MY2021_Rx" SG_ 342 EngOil_Te_Actl 1;
BA_ "U_CD542_MY2021_Rx" SG_ 342 EngOil_Te_Actl 1;
BA_ "U_T6_MCA_MY2020_Rx" SG_ 342 EngOil_Te_Actl 1;
BA_ "U_U55X_MY2022_Rx" SG_ 342 EngClnt_Te_Actl 1;
BA_ "U_CD542_MY2021_Rx" SG_ 342 EngClnt_Te_Actl 1;
BA_ "U_T6_MCA_MY2020_Rx" SG_ 342 EngClnt_Te_Actl 1;
BA_ "U_P702_MY2021_Rx" SG_ 342 EngClnt_Te_Actl 1;
BA_ "U_U55X_MY2022_Tx" SG_ 530 PiCode_No_Rq 1;
BA_ "U_CD542_MY2021_Tx" SG_ 530 PiCode_No_Rq 1;
BA_ "U_T6_MCA_MY2020_Tx" SG_ 530 PiCode_No_Rq 1;
BA_ "U_U55X_MY2022_Rx" SG_ 530 PiCode_No_Rq 1;
BA_ "U_T6_MCA_MY2020_Rx" SG_ 530 PiCode_No_Rq 1;
BA_ "U_U55X_MY2022_Tx" SG_ 530 StationTypeSel_D_Rq 1;
BA_ "U_CD542_MY2021_Tx" SG_ 530 StationTypeSel_D_Rq 1;
BA_ "U_T6_MCA_MY2020_Tx" SG_ 530 StationTypeSel_D_Rq 1;
BA_ "U_U55X_MY2022_Rx" SG_ 530 StationTypeSel_D_Rq 1;
BA_ "U_T6_MCA_MY2020_Rx" SG_ 530 StationTypeSel_D_Rq 1;
BA_ "GenSigSendType" SG_ 530 StationTypeSel_D_Rq 3;
BA_ "U_U55X_MY2022_Tx" SG_ 530 DabExtndCntryCode_No_Rq 1;
BA_ "U_CD542_MY2021_Tx" SG_ 530 DabExtndCntryCode_No_Rq 1;
BA_ "U_T6_MCA_MY2020_Tx" SG_ 530 DabExtndCntryCode_No_Rq 1;
BA_ "U_U55X_MY2022_Rx" SG_ 530 DabExtndCntryCode_No_Rq 1;
BA_ "U_T6_MCA_MY2020_Rx" SG_ 530 DabExtndCntryCode_No_Rq 1;
BA_ "U_U55X_MY2022_Tx" SG_ 530 DabStationCodeId_No_Rq 1;
BA_ "U_CD542_MY2021_Tx" SG_ 530 DabStationCodeId_No_Rq 1;
BA_ "U_T6_MCA_MY2020_Tx" SG_ 530 DabStationCodeId_No_Rq 1;
BA_ "U_U55X_MY2022_Rx" SG_ 530 DabStationCodeId_No_Rq 1;
BA_ "U_T6_MCA_MY2020_Rx" SG_ 530 DabStationCodeId_No_Rq 1;
BA_ "U_U55X_MY2022_Tx" SG_ 530 DabStationId_No_Rq 1;
BA_ "U_CD542_MY2021_Tx" SG_ 530 DabStationId_No_Rq 1;
BA_ "U_T6_MCA_MY2020_Tx" SG_ 530 DabStationId_No_Rq 1;
BA_ "U_U55X_MY2022_Rx" SG_ 530 DabStationId_No_Rq 1;
BA_ "U_T6_MCA_MY2020_Rx" SG_ 530 DabStationId_No_Rq 1;
BA_ "U_U55X_MY2022_Rx" SG_ 897 VehElAvgTrip2_Eff_Dsply 1;
BA_ "U_CD542_MY2021_Rx" SG_ 897 VehElAvgTrip2_Eff_Dsply 1;
BA_ "GenSigStartValue" SG_ 897 VehElAvgTrip2_Eff_Dsply 126;
BA_ "GenSigStartValueInteger" SG_ 897 VehElAvgTrip2_Eff_Dsply 126;
BA_ "U_U55X_MY2022_Rx" SG_ 897 Trip2SumDrvE_Pc_Dsply 1;
BA_ "U_CD542_MY2021_Rx" SG_ 897 Trip2SumDrvE_Pc_Dsply 1;
BA_ "GenSigStartValue" SG_ 897 Trip2SumDrvE_Pc_Dsply 1022;
BA_ "GenSigStartValueInteger" SG_ 897 Trip2SumDrvE_Pc_Dsply 1022;
BA_ "U_U55X_MY2022_Rx" SG_ 897 Trip2ExtFctrE_Pc_Dsply 1;
BA_ "U_CD542_MY2021_Rx" SG_ 897 Trip2ExtFctrE_Pc_Dsply 1;
BA_ "GenSigStartValue" SG_ 897 Trip2ExtFctrE_Pc_Dsply 1022;
BA_ "GenSigStartValueInteger" SG_ 897 Trip2ExtFctrE_Pc_Dsply 1022;
BA_ "U_U55X_MY2022_Rx" SG_ 897 Trip2ClimE_Pc_Dsply 1;
BA_ "U_CD542_MY2021_Rx" SG_ 897 Trip2ClimE_Pc_Dsply 1;
BA_ "GenSigStartValue" SG_ 897 Trip2ClimE_Pc_Dsply 1022;
BA_ "GenSigStartValueInteger" SG_ 897 Trip2ClimE_Pc_Dsply 1022;
BA_ "U_U55X_MY2022_Rx" SG_ 897 Trip2BattULoE_Pc_Dsply 1;
BA_ "U_CD542_MY2021_Rx" SG_ 897 Trip2BattULoE_Pc_Dsply 1;
BA_ "GenSigStartValue" SG_ 897 Trip2BattULoE_Pc_Dsply 1022;
BA_ "GenSigStartValueInteger" SG_ 897 Trip2BattULoE_Pc_Dsply 1022;
BA_ "U_U55X_MY2022_Tx" SG_ 707 SSPClnt_SSPSrv_WORD_Tx 1;
BA_ "U_CD542_MY2021_Tx" SG_ 707 SSPClnt_SSPSrv_WORD_Tx 1;
BA_ "U_T6_MCA_MY2020_Tx" SG_ 707 SSPClnt_SSPSrv_WORD_Tx 1;
BA_ "U_P702_MY2021_Tx" SG_ 707 SSPClnt_SSPSrv_WORD_Tx 1;
BA_ "U_U55X_MY2022_Rx" SG_ 707 SSPClnt_SSPSrv_WORD_Tx 1;
BA_ "U_CD542_MY2021_Rx" SG_ 707 SSPClnt_SSPSrv_WORD_Tx 1;
BA_ "U_T6_MCA_MY2020_Rx" SG_ 707 SSPClnt_SSPSrv_WORD_Tx 1;
BA_ "U_P702_MY2021_Rx" SG_ 707 SSPClnt_SSPSrv_WORD_Tx 1;
BA_ "U_FNV2_IVI_Rx" SG_ 1102 SelDrvMdePos12_D_Stat 1;
BA_ "U_U55X_MY2022_Rx" SG_ 1102 SelDrvMdePos12_D_Stat 1;
BA_ "U_CD542_MY2021_Rx" SG_ 1102 SelDrvMdePos12_D_Stat 1;
BA_ "U_T6_MCA_MY2020_Rx" SG_ 1102 SelDrvMdePos12_D_Stat 1;
BA_ "U_P702_MY2021_Rx" SG_ 1102 SelDrvMdePos12_D_Stat 1;
BA_ "GenSigStartValue" SG_ 1102 SelDrvMdePos12_D_Stat 31;
BA_ "GenSigStartValueInteger" SG_ 1102 SelDrvMdePos12_D_Stat 31;
BA_ "U_FNV2_IVI_Rx" SG_ 1102 SelDrvMdePos11_D_Stat 1;
BA_ "U_U55X_MY2022_Rx" SG_ 1102 SelDrvMdePos11_D_Stat 1;
BA_ "U_CD542_MY2021_Rx" SG_ 1102 SelDrvMdePos11_D_Stat 1;
BA_ "U_T6_MCA_MY2020_Rx" SG_ 1102 SelDrvMdePos11_D_Stat 1;
BA_ "U_P702_MY2021_Rx" SG_ 1102 SelDrvMdePos11_D_Stat 1;
BA_ "GenSigStartValue" SG_ 1102 SelDrvMdePos11_D_Stat 31;
BA_ "GenSigStartValueInteger" SG_ 1102 SelDrvMdePos11_D_Stat 31;
BA_ "U_FNV2_IVI_Rx" SG_ 1102 SelDrvMdePos10_D_Stat 1;
BA_ "U_U55X_MY2022_Rx" SG_ 1102 SelDrvMdePos10_D_Stat 1;
BA_ "U_CD542_MY2021_Rx" SG_ 1102 SelDrvMdePos10_D_Stat 1;
BA_ "U_T6_MCA_MY2020_Rx" SG_ 1102 SelDrvMdePos10_D_Stat 1;
BA_ "U_P702_MY2021_Rx" SG_ 1102 SelDrvMdePos10_D_Stat 1;
BA_ "GenSigStartValue" SG_ 1102 SelDrvMdePos10_D_Stat 31;
BA_ "GenSigStartValueInteger" SG_ 1102 SelDrvMdePos10_D_Stat 31;
BA_ "U_FNV2_IVI_Rx" SG_ 1102 SelDrvMdePos09_D_Stat 1;
BA_ "U_U55X_MY2022_Rx" SG_ 1102 SelDrvMdePos09_D_Stat 1;
BA_ "U_CD542_MY2021_Rx" SG_ 1102 SelDrvMdePos09_D_Stat 1;
BA_ "U_T6_MCA_MY2020_Rx" SG_ 1102 SelDrvMdePos09_D_Stat 1;
BA_ "U_P702_MY2021_Rx" SG_ 1102 SelDrvMdePos09_D_Stat 1;
BA_ "GenSigStartValue" SG_ 1102 SelDrvMdePos09_D_Stat 31;
BA_ "GenSigStartValueInteger" SG_ 1102 SelDrvMdePos09_D_Stat 31;
BA_ "U_FNV2_IVI_Rx" SG_ 1102 SelDrvMdePos08_D_Stat 1;
BA_ "U_U55X_MY2022_Rx" SG_ 1102 SelDrvMdePos08_D_Stat 1;
BA_ "U_CD542_MY2021_Rx" SG_ 1102 SelDrvMdePos08_D_Stat 1;
BA_ "U_T6_MCA_MY2020_Rx" SG_ 1102 SelDrvMdePos08_D_Stat 1;
BA_ "U_P702_MY2021_Rx" SG_ 1102 SelDrvMdePos08_D_Stat 1;
BA_ "GenSigStartValue" SG_ 1102 SelDrvMdePos08_D_Stat 31;
BA_ "GenSigStartValueInteger" SG_ 1102 SelDrvMdePos08_D_Stat 31;
BA_ "U_FNV2_IVI_Rx" SG_ 1102 SelDrvMdePos07_D_Stat 1;
BA_ "U_U55X_MY2022_Rx" SG_ 1102 SelDrvMdePos07_D_Stat 1;
BA_ "U_CD542_MY2021_Rx" SG_ 1102 SelDrvMdePos07_D_Stat 1;
BA_ "U_T6_MCA_MY2020_Rx" SG_ 1102 SelDrvMdePos07_D_Stat 1;
BA_ "U_P702_MY2021_Rx" SG_ 1102 SelDrvMdePos07_D_Stat 1;
BA_ "GenSigStartValue" SG_ 1102 SelDrvMdePos07_D_Stat 31;
BA_ "GenSigStartValueInteger" SG_ 1102 SelDrvMdePos07_D_Stat 31;
BA_ "U_FNV2_IVI_Rx" SG_ 1102 SelDrvMdePos06_D_Stat 1;
BA_ "U_U55X_MY2022_Rx" SG_ 1102 SelDrvMdePos06_D_Stat 1;
BA_ "U_CD542_MY2021_Rx" SG_ 1102 SelDrvMdePos06_D_Stat 1;
BA_ "U_T6_MCA_MY2020_Rx" SG_ 1102 SelDrvMdePos06_D_Stat 1;
BA_ "U_P702_MY2021_Rx" SG_ 1102 SelDrvMdePos06_D_Stat 1;
BA_ "GenSigStartValue" SG_ 1102 SelDrvMdePos06_D_Stat 31;
BA_ "GenSigStartValueInteger" SG_ 1102 SelDrvMdePos06_D_Stat 31;
BA_ "U_FNV2_IVI_Rx" SG_ 1102 SelDrvMdePos05_D_Stat 1;
BA_ "U_U55X_MY2022_Rx" SG_ 1102 SelDrvMdePos05_D_Stat 1;
BA_ "U_CD542_MY2021_Rx" SG_ 1102 SelDrvMdePos05_D_Stat 1;
BA_ "U_T6_MCA_MY2020_Rx" SG_ 1102 SelDrvMdePos05_D_Stat 1;
BA_ "U_P702_MY2021_Rx" SG_ 1102 SelDrvMdePos05_D_Stat 1;
BA_ "GenSigStartValue" SG_ 1102 SelDrvMdePos05_D_Stat 31;
BA_ "GenSigStartValueInteger" SG_ 1102 SelDrvMdePos05_D_Stat 31;
BA_ "U_FNV2_IVI_Rx" SG_ 1102 SelDrvMdePos04_D_Stat 1;
BA_ "U_U55X_MY2022_Rx" SG_ 1102 SelDrvMdePos04_D_Stat 1;
BA_ "U_CD542_MY2021_Rx" SG_ 1102 SelDrvMdePos04_D_Stat 1;
BA_ "U_T6_MCA_MY2020_Rx" SG_ 1102 SelDrvMdePos04_D_Stat 1;
BA_ "U_P702_MY2021_Rx" SG_ 1102 SelDrvMdePos04_D_Stat 1;
BA_ "GenSigStartValue" SG_ 1102 SelDrvMdePos04_D_Stat 31;
BA_ "GenSigStartValueInteger" SG_ 1102 SelDrvMdePos04_D_Stat 31;
BA_ "U_FNV2_IVI_Rx" SG_ 1102 SelDrvMdePos03_D_Stat 1;
BA_ "U_U55X_MY2022_Rx" SG_ 1102 SelDrvMdePos03_D_Stat 1;
BA_ "U_CD542_MY2021_Rx" SG_ 1102 SelDrvMdePos03_D_Stat 1;
BA_ "U_T6_MCA_MY2020_Rx" SG_ 1102 SelDrvMdePos03_D_Stat 1;
BA_ "U_P702_MY2021_Rx" SG_ 1102 SelDrvMdePos03_D_Stat 1;
BA_ "GenSigStartValue" SG_ 1102 SelDrvMdePos03_D_Stat 31;
BA_ "GenSigStartValueInteger" SG_ 1102 SelDrvMdePos03_D_Stat 31;
BA_ "U_FNV2_IVI_Rx" SG_ 1102 SelDrvMdePos02_D_Stat 1;
BA_ "U_U55X_MY2022_Rx" SG_ 1102 SelDrvMdePos02_D_Stat 1;
BA_ "U_CD542_MY2021_Rx" SG_ 1102 SelDrvMdePos02_D_Stat 1;
BA_ "U_T6_MCA_MY2020_Rx" SG_ 1102 SelDrvMdePos02_D_Stat 1;
BA_ "U_P702_MY2021_Rx" SG_ 1102 SelDrvMdePos02_D_Stat 1;
BA_ "GenSigStartValue" SG_ 1102 SelDrvMdePos02_D_Stat 31;
BA_ "GenSigStartValueInteger" SG_ 1102 SelDrvMdePos02_D_Stat 31;
BA_ "U_FNV2_IVI_Rx" SG_ 1102 SelDrvMdePos01_D_Stat 1;
BA_ "U_U55X_MY2022_Rx" SG_ 1102 SelDrvMdePos01_D_Stat 1;
BA_ "U_CD542_MY2021_Rx" SG_ 1102 SelDrvMdePos01_D_Stat 1;
BA_ "U_T6_MCA_MY2020_Rx" SG_ 1102 SelDrvMdePos01_D_Stat 1;
BA_ "U_P702_MY2021_Rx" SG_ 1102 SelDrvMdePos01_D_Stat 1;
BA_ "GenSigStartValue" SG_ 1102 SelDrvMdePos01_D_Stat 31;
BA_ "GenSigStartValueInteger" SG_ 1102 SelDrvMdePos01_D_Stat 31;
BA_ "U_T6_MCA_MY2020_Tx" SG_ 551 Rba_D_Rq 1;
BA_ "U_P702_MY2021_Tx" SG_ 551 Rba_D_Rq 1;
BA_ "U_U55X_MY2022_Tx" SG_ 551 Rba_D_Rq 1;
BA_ "U_CD542_MY2021_Tx" SG_ 551 Rba_D_Rq 1;
BA_ "GenSigSendType" SG_ 551 Rba_D_Rq 3;
BA_ "U_U55X_MY2022_Tx" SG_ 551 PrcondEdit_D_RqMnu 1;
BA_ "U_CD542_MY2021_Tx" SG_ 551 PrcondEdit_D_RqMnu 1;
BA_ "U_T6_MCA_MY2020_Tx" SG_ 551 PrcondEdit_D_RqMnu 1;
BA_ "GenSigSendType" SG_ 551 PrcondEdit_D_RqMnu 3;
BA_ "U_U55X_MY2022_Tx" SG_ 551 ChrgToPcEdit_Pc_RqMnu 1;
BA_ "U_CD542_MY2021_Tx" SG_ 551 ChrgToPcEdit_Pc_RqMnu 1;
BA_ "U_T6_MCA_MY2020_Tx" SG_ 551 ChrgToPcEdit_Pc_RqMnu 1;
BA_ "GenSigSendType" SG_ 551 ChrgToPcEdit_Pc_RqMnu 3;
BA_ "GenSigStartValue" SG_ 551 ChrgToPcEdit_Pc_RqMnu 126;
BA_ "U_U55X_MY2022_Tx" SG_ 551 EcoIdl_D_Rq 1;
BA_ "U_CD542_MY2021_Tx" SG_ 551 EcoIdl_D_Rq 1;
BA_ "U_T6_MCA_MY2020_Tx" SG_ 551 EcoIdl_D_Rq 1;
BA_ "GenSigSendType" SG_ 551 EcoIdl_D_Rq 3;
BA_ "U_U55X_MY2022_Tx" SG_ 551 PwRnngBoardT_D_Rq 1;
BA_ "U_CD542_MY2021_Tx" SG_ 551 PwRnngBoardT_D_Rq 1;
BA_ "U_T6_MCA_MY2020_Tx" SG_ 551 PwRnngBoardT_D_Rq 1;
BA_ "GenSigSendType" SG_ 551 PwRnngBoardT_D_Rq 3;
BA_ "U_U55X_MY2022_Tx" SG_ 551 PwRnngBoardSwtch_D_Rq 1;
BA_ "U_CD542_MY2021_Tx" SG_ 551 PwRnngBoardSwtch_D_Rq 1;
BA_ "U_T6_MCA_MY2020_Tx" SG_ 551 PwRnngBoardSwtch_D_Rq 1;
BA_ "GenSigSendType" SG_ 551 PwRnngBoardSwtch_D_Rq 3;
BA_ "U_U55X_MY2022_Tx" SG_ 551 PwRnngBoardMde_D_Rq 1;
BA_ "U_CD542_MY2021_Tx" SG_ 551 PwRnngBoardMde_D_Rq 1;
BA_ "U_T6_MCA_MY2020_Tx" SG_ 551 PwRnngBoardMde_D_Rq 1;
BA_ "GenSigSendType" SG_ 551 PwRnngBoardMde_D_Rq 3;
BA_ "U_U55X_MY2022_Tx" SG_ 551 GoTElementEdit_No_RqMnu 1;
BA_ "U_CD542_MY2021_Tx" SG_ 551 GoTElementEdit_No_RqMnu 1;
BA_ "U_T6_MCA_MY2020_Tx" SG_ 551 GoTElementEdit_No_RqMnu 1;
BA_ "U_U55X_MY2022_Rx" SG_ 551 GoTElementEdit_No_RqMnu 1;
BA_ "U_CD542_MY2021_Rx" SG_ 551 GoTElementEdit_No_RqMnu 1;
BA_ "ECGUsedRxSignal" SG_ 551 GoTElementEdit_No_RqMnu 1;
BA_ "U_T6_MCA_MY2020_Rx" SG_ 551 GoTElementEdit_No_RqMnu 1;
BA_ "GenSigSendType" SG_ 551 GoTElementEdit_No_RqMnu 3;
BA_ "U_U55X_MY2022_Tx" SG_ 551 OneTEditActv_B_RqMnu 1;
BA_ "U_CD542_MY2021_Tx" SG_ 551 OneTEditActv_B_RqMnu 1;
BA_ "U_T6_MCA_MY2020_Tx" SG_ 551 OneTEditActv_B_RqMnu 1;
BA_ "U_U55X_MY2022_Rx" SG_ 551 OneTEditActv_B_RqMnu 1;
BA_ "U_CD542_MY2021_Rx" SG_ 551 OneTEditActv_B_RqMnu 1;
BA_ "ECGUsedRxSignal" SG_ 551 OneTEditActv_B_RqMnu 1;
BA_ "U_T6_MCA_MY2020_Rx" SG_ 551 OneTEditActv_B_RqMnu 1;
BA_ "GenSigSendType" SG_ 551 OneTEditActv_B_RqMnu 3;
BA_ "U_U55X_MY2022_Tx" SG_ 551 Cntr_Plg_Mode_Cmd 1;
BA_ "U_CD542_MY2021_Tx" SG_ 551 Cntr_Plg_Mode_Cmd 1;
BA_ "U_T6_MCA_MY2020_Tx" SG_ 551 Cntr_Plg_Mode_Cmd 1;
BA_ "GenSigSendType" SG_ 551 Cntr_Plg_Mode_Cmd 3;
BA_ "WakeupSignal" SG_ 551 Cntr_Plg_Mode_Cmd 1;
BA_ "U_U55X_MY2022_Tx" SG_ 551 BattTracLoThres_D_Rq 1;
BA_ "U_CD542_MY2021_Tx" SG_ 551 BattTracLoThres_D_Rq 1;
BA_ "U_T6_MCA_MY2020_Tx" SG_ 551 BattTracLoThres_D_Rq 1;
BA_ "GenSigSendType" SG_ 551 BattTracLoThres_D_Rq 3;
BA_ "U_T6_MCA_MY2020_Tx" SG_ 551 EmPrflNo_D_Rq 1;
BA_ "U_P702_MY2021_Tx" SG_ 551 EmPrflNo_D_Rq 1;
BA_ "U_U55X_MY2022_Tx" SG_ 551 EmPrflNo_D_Rq 1;
BA_ "U_CD542_MY2021_Tx" SG_ 551 EmPrflNo_D_Rq 1;
BA_ "GenSigSendType" SG_ 551 EmPrflNo_D_Rq 3;
BA_ "U_U55X_MY2022_Tx" SG_ 551 EmPrflButtnAssoc_D_Rq 1;
BA_ "U_CD542_MY2021_Tx" SG_ 551 EmPrflButtnAssoc_D_Rq 1;
BA_ "U_T6_MCA_MY2020_Tx" SG_ 551 EmPrflButtnAssoc_D_Rq 1;
BA_ "U_P702_MY2021_Tx" SG_ 551 EmPrflButtnAssoc_D_Rq 1;
BA_ "GenSigSendType" SG_ 551 EmPrflButtnAssoc_D_Rq 3;
BA_ "U_U55X_MY2022_Tx" SG_ 551 EmPrflKeyAssoc_D_Rq 1;
BA_ "U_CD542_MY2021_Tx" SG_ 551 EmPrflKeyAssoc_D_Rq 1;
BA_ "U_T6_MCA_MY2020_Tx" SG_ 551 EmPrflKeyAssoc_D_Rq 1;
BA_ "U_P702_MY2021_Tx" SG_ 551 EmPrflKeyAssoc_D_Rq 1;
BA_ "GenSigSendType" SG_ 551 EmPrflKeyAssoc_D_Rq 3;
BA_ "U_U55X_MY2022_Tx" SG_ 551 Em_D_Stat 1;
BA_ "U_CD542_MY2021_Tx" SG_ 551 Em_D_Stat 1;
BA_ "U_T6_MCA_MY2020_Tx" SG_ 551 Em_D_Stat 1;
BA_ "U_P702_MY2021_Tx" SG_ 551 Em_D_Stat 1;
BA_ "GenSigSendType" SG_ 551 Em_D_Stat 3;
BA_ "WakeupSignal" SG_ 551 Em_D_Stat 1;
BA_ "U_U55X_MY2022_Tx" SG_ 551 PmCabnLvl_D_Stat 1;
BA_ "U_CD542_MY2021_Tx" SG_ 551 PmCabnLvl_D_Stat 1;
BA_ "U_T6_MCA_MY2020_Tx" SG_ 551 PmCabnLvl_D_Stat 1;
BA_ "U_U55X_MY2022_Rx" SG_ 551 PmCabnLvl_D_Stat 1;
BA_ "GenSigSendType" SG_ 551 PmCabnLvl_D_Stat 3;
BA_ "U_U55X_MY2022_Tx" SG_ 551 PmCabn_D_Stat 1;
BA_ "U_CD542_MY2021_Tx" SG_ 551 PmCabn_D_Stat 1;
BA_ "U_T6_MCA_MY2020_Tx" SG_ 551 PmCabn_D_Stat 1;
BA_ "U_U55X_MY2022_Rx" SG_ 551 PmCabn_D_Stat 1;
BA_ "GenSigSendType" SG_ 551 PmCabn_D_Stat 3;
BA_ "U_U55X_MY2022_Tx" SG_ 551 ChrgCrdLckEnbl_B_Stat 1;
BA_ "U_CD542_MY2021_Tx" SG_ 551 ChrgCrdLckEnbl_B_Stat 1;
BA_ "U_T6_MCA_MY2020_Tx" SG_ 551 ChrgCrdLckEnbl_B_Stat 1;
BA_ "GenSigSendType" SG_ 551 ChrgCrdLckEnbl_B_Stat 3;
BA_ "U_U55X_MY2022_Tx" SG_ 551 ChrgOvrdExitScrn_D_Rq 1;
BA_ "U_CD542_MY2021_Tx" SG_ 551 ChrgOvrdExitScrn_D_Rq 1;
BA_ "U_T6_MCA_MY2020_Tx" SG_ 551 ChrgOvrdExitScrn_D_Rq 1;
BA_ "U_P702_MY2021_Tx" SG_ 551 ChrgOvrdExitScrn_D_Rq 1;
BA_ "GenSigSendType" SG_ 551 ChrgOvrdExitScrn_D_Rq 3;
BA_ "U_U55X_MY2022_Tx" SG_ 551 Btt_L_Actl2 1;
BA_ "U_CD542_MY2021_Tx" SG_ 551 Btt_L_Actl2 1;
BA_ "U_T6_MCA_MY2020_Tx" SG_ 551 Btt_L_Actl2 1;
BA_ "GenSigStartValue" SG_ 551 Btt_L_Actl2 126;
BA_ "GenSigStartValueInteger" SG_ 551 Btt_L_Actl2 126;
BA_ "U_U55X_MY2022_Rx" SG_ 673 ICI_Coding_BtnID_D 1;
BA_ "U_CD542_MY2021_Rx" SG_ 673 ICI_Coding_BtnID_D 1;
BA_ "U_T6_MCA_MY2020_Rx" SG_ 673 ICI_Coding_BtnID_D 1;
BA_ "U_P702_MY2021_Rx" SG_ 673 ICI_Coding_BtnID_D 1;
BA_ "U_U55X_MY2022_Rx" SG_ 673 ICI_Coding_BtnID_C 1;
BA_ "U_CD542_MY2021_Rx" SG_ 673 ICI_Coding_BtnID_C 1;
BA_ "U_T6_MCA_MY2020_Rx" SG_ 673 ICI_Coding_BtnID_C 1;
BA_ "U_P702_MY2021_Rx" SG_ 673 ICI_Coding_BtnID_C 1;
BA_ "U_U55X_MY2022_Rx" SG_ 673 ICI_Coding_BtnID_B 1;
BA_ "U_CD542_MY2021_Rx" SG_ 673 ICI_Coding_BtnID_B 1;
BA_ "U_T6_MCA_MY2020_Rx" SG_ 673 ICI_Coding_BtnID_B 1;
BA_ "U_P702_MY2021_Rx" SG_ 673 ICI_Coding_BtnID_B 1;
BA_ "U_U55X_MY2022_Rx" SG_ 673 ICI_Coding_BtnID_A 1;
BA_ "U_CD542_MY2021_Rx" SG_ 673 ICI_Coding_BtnID_A 1;
BA_ "U_T6_MCA_MY2020_Rx" SG_ 673 ICI_Coding_BtnID_A 1;
BA_ "U_P702_MY2021_Rx" SG_ 673 ICI_Coding_BtnID_A 1;
BA_ "U_U55X_MY2022_Rx" SG_ 673 ICI_BtnID_D 1;
BA_ "U_CD542_MY2021_Rx" SG_ 673 ICI_BtnID_D 1;
BA_ "U_T6_MCA_MY2020_Rx" SG_ 673 ICI_BtnID_D 1;
BA_ "U_P702_MY2021_Rx" SG_ 673 ICI_BtnID_D 1;
BA_ "GenSigStartValue" SG_ 673 ICI_BtnID_D 255;
BA_ "GenSigStartValueInteger" SG_ 673 ICI_BtnID_D 255;
BA_ "U_U55X_MY2022_Rx" SG_ 673 ICI_BtnID_C 1;
BA_ "U_CD542_MY2021_Rx" SG_ 673 ICI_BtnID_C 1;
BA_ "U_T6_MCA_MY2020_Rx" SG_ 673 ICI_BtnID_C 1;
BA_ "U_P702_MY2021_Rx" SG_ 673 ICI_BtnID_C 1;
BA_ "GenSigStartValue" SG_ 673 ICI_BtnID_C 255;
BA_ "GenSigStartValueInteger" SG_ 673 ICI_BtnID_C 255;
BA_ "U_U55X_MY2022_Rx" SG_ 673 ICI_BtnID_B 1;
BA_ "U_CD542_MY2021_Rx" SG_ 673 ICI_BtnID_B 1;
BA_ "U_T6_MCA_MY2020_Rx" SG_ 673 ICI_BtnID_B 1;
BA_ "U_P702_MY2021_Rx" SG_ 673 ICI_BtnID_B 1;
BA_ "GenSigStartValue" SG_ 673 ICI_BtnID_B 255;
BA_ "GenSigStartValueInteger" SG_ 673 ICI_BtnID_B 255;
BA_ "U_U55X_MY2022_Rx" SG_ 673 ICI_BtnID_A 1;
BA_ "U_CD542_MY2021_Rx" SG_ 673 ICI_BtnID_A 1;
BA_ "U_T6_MCA_MY2020_Rx" SG_ 673 ICI_BtnID_A 1;
BA_ "U_P702_MY2021_Rx" SG_ 673 ICI_BtnID_A 1;
BA_ "GenSigStartValue" SG_ 673 ICI_BtnID_A 255;
BA_ "GenSigStartValueInteger" SG_ 673 ICI_BtnID_A 255;
BA_ "WakeupSignal" SG_ 963 ImpactEvntFdbck_D_Stat 1;
BA_ "U_U55X_MY2022_Rx" SG_ 963 WrlssAcsyChrgInhbt_B_Rq 1;
BA_ "U_CD542_MY2021_Rx" SG_ 963 WrlssAcsyChrgInhbt_B_Rq 1;
BA_ "U_T6_MCA_MY2020_Rx" SG_ 963 WrlssAcsyChrgInhbt_B_Rq 1;
BA_ "U_P702_MY2021_Rx" SG_ 963 WrlssAcsyChrgInhbt_B_Rq 1;
BA_ "U_CX727_MY2021_Rx" SG_ 963 WrlssAcsyChrgInhbt_B_Rq 1;
BA_ "U_U55X_MY2022_Rx" SG_ 963 HeadLampLoOut_B_Stat 1;
BA_ "U_CD542_MY2021_Rx" SG_ 963 HeadLampLoOut_B_Stat 1;
BA_ "U_T6_MCA_MY2020_Rx" SG_ 963 HeadLampLoOut_B_Stat 1;
BA_ "U_U55X_MY2022_Rx" SG_ 963 PrkLightChime_B_Rq 1;
BA_ "U_CD542_MY2021_Rx" SG_ 963 PrkLightChime_B_Rq 1;
BA_ "U_T6_MCA_MY2020_Rx" SG_ 963 PrkLightChime_B_Rq 1;
BA_ "U_P702_MY2021_Rx" SG_ 963 PrkLightChime_B_Rq 1;
BA_ "U_CD542_MY2021_Rx" SG_ 963 TrnNotInPrkChime_B_Rq 1;
BA_ "U_T6_MCA_MY2020_Rx" SG_ 963 TrnNotInPrkChime_B_Rq 1;
BA_ "U_U55X_MY2022_Rx" SG_ 963 KeyInIgnWarn_B_Cmd 1;
BA_ "U_CD542_MY2021_Rx" SG_ 963 KeyInIgnWarn_B_Cmd 1;
BA_ "U_T6_MCA_MY2020_Rx" SG_ 963 KeyInIgnWarn_B_Cmd 1;
BA_ "U_P702_MY2021_Rx" SG_ 963 KeyInIgnWarn_B_Cmd 1;
BA_ "WakeupSignal" SG_ 963 KeyInIgnWarn_B_Cmd 1;
BA_ "U_U55X_MY2022_Rx" SG_ 963 HomeSafeLtChime_B_Rq 1;
BA_ "U_CD542_MY2021_Rx" SG_ 963 HomeSafeLtChime_B_Rq 1;
BA_ "U_T6_MCA_MY2020_Rx" SG_ 963 HomeSafeLtChime_B_Rq 1;
BA_ "U_P702_MY2021_Rx" SG_ 963 HomeSafeLtChime_B_Rq 1;
BA_ "WakeupSignal" SG_ 963 HomeSafeLtChime_B_Rq 1;
BA_ "U_U55X_MY2022_Rx" SG_ 963 StopLghtOn_B_Stat 1;
BA_ "U_T6_MCA_MY2020_Rx" SG_ 963 StopLghtOn_B_Stat 1;
BA_ "U_P702_MY2021_Rx" SG_ 963 StopLghtOn_B_Stat 1;
BA_ "WakeupSignal" SG_ 963 StopLghtOn_B_Stat 1;
BA_ "U_U55X_MY2022_Rx" SG_ 963 RvrseLghtOn_B_Stat 1;
BA_ "U_CD542_MY2021_Rx" SG_ 963 RvrseLghtOn_B_Stat 1;
BA_ "U_T6_MCA_MY2020_Rx" SG_ 963 RvrseLghtOn_B_Stat 1;
BA_ "WakeupSignal" SG_ 963 PrkLght_D_Stat 1;
BA_ "U_CD542_MY2021_Rx" SG_ 963 HeadLghtSwtch_D_Stat 1;
BA_ "U_T6_MCA_MY2020_Rx" SG_ 963 HeadLghtSwtch_D_Stat 1;
BA_ "GenSigStartValue" SG_ 963 HeadLghtSwtch_D_Stat 2;
BA_ "GenSigStartValueInteger" SG_ 963 HeadLghtSwtch_D_Stat 2;
BA_ "WakeupSignal" SG_ 963 HeadLghtSwtch_D_Stat 1;
BA_ "GenSigStartValue" SG_ 963 HeadLampLoFrOn_B_Stat 1;
BA_ "GenSigStartValueInteger" SG_ 963 HeadLampLoFrOn_B_Stat 1;
BA_ "GenSigStartValue" SG_ 963 HeadLampLoFlOn_B_Stat 1;
BA_ "GenSigStartValueInteger" SG_ 963 HeadLampLoFlOn_B_Stat 1;
BA_ "U_U55X_MY2022_Rx" SG_ 963 HeadLampLoActv_B_Stat 1;
BA_ "U_CD542_MY2021_Rx" SG_ 963 HeadLampLoActv_B_Stat 1;
BA_ "U_T6_MCA_MY2020_Rx" SG_ 963 HeadLampLoActv_B_Stat 1;
BA_ "U_P702_MY2021_Rx" SG_ 963 HeadLampLoActv_B_Stat 1;
BA_ "GenSigStartValue" SG_ 963 HeadLampLoActv_B_Stat 1;
BA_ "GenSigStartValueInteger" SG_ 963 HeadLampLoActv_B_Stat 1;
BA_ "U_U55X_MY2022_Rx" SG_ 963 Headlamp_On_Wrning_Cmd 1;
BA_ "U_CD542_MY2021_Rx" SG_ 963 Headlamp_On_Wrning_Cmd 1;
BA_ "U_T6_MCA_MY2020_Rx" SG_ 963 Headlamp_On_Wrning_Cmd 1;
BA_ "U_P702_MY2021_Rx" SG_ 963 Headlamp_On_Wrning_Cmd 1;
BA_ "WakeupSignal" SG_ 963 Headlamp_On_Wrning_Cmd 1;
BA_ "U_U55X_MY2022_Rx" SG_ 963 HeadLghtHiOn_B_Stat 1;
BA_ "U_CD542_MY2021_Rx" SG_ 963 HeadLghtHiOn_B_Stat 1;
BA_ "U_T6_MCA_MY2020_Rx" SG_ 963 HeadLghtHiOn_B_Stat 1;
BA_ "U_P702_MY2021_Rx" SG_ 963 HeadLghtHiOn_B_Stat 1;
BA_ "WakeupSignal" SG_ 963 HeadLghtHiOn_B_Stat 1;
BA_ "U_U55X_MY2022_Rx" SG_ 963 Park_Brake_Chime_Rqst 1;
BA_ "U_CD542_MY2021_Rx" SG_ 963 Park_Brake_Chime_Rqst 1;
BA_ "U_T6_MCA_MY2020_Rx" SG_ 963 Park_Brake_Chime_Rqst 1;
BA_ "U_P702_MY2021_Rx" SG_ 963 Park_Brake_Chime_Rqst 1;
BA_ "U_U55X_MY2022_Rx" SG_ 963 BrkWarnInd_B_Rq 1;
BA_ "U_CD542_MY2021_Rx" SG_ 963 BrkWarnInd_B_Rq 1;
BA_ "U_T6_MCA_MY2020_Rx" SG_ 963 BrkWarnInd_B_Rq 1;
BA_ "U_P702_MY2021_Rx" SG_ 963 BrkWarnInd_B_Rq 1;
BA_ "U_U55X_MY2022_Rx" SG_ 963 Brk_Fluid_Lvl_Low 1;
BA_ "U_CD542_MY2021_Rx" SG_ 963 Brk_Fluid_Lvl_Low 1;
BA_ "U_T6_MCA_MY2020_Rx" SG_ 963 Brk_Fluid_Lvl_Low 1;
BA_ "U_P702_MY2021_Rx" SG_ 963 Brk_Fluid_Lvl_Low 1;
BA_ "U_U55X_MY2022_Rx" SG_ 963 ReducedGuard_D_Stat 1;
BA_ "U_CD542_MY2021_Rx" SG_ 963 ReducedGuard_D_Stat 1;
BA_ "U_T6_MCA_MY2020_Rx" SG_ 963 ReducedGuard_D_Stat 1;
BA_ "U_P702_MY2021_Rx" SG_ 963 ReducedGuard_D_Stat 1;
BA_ "U_CD542_MY2021_Rx" SG_ 963 Courtesy_BSave_Stat 1;
BA_ "U_T6_MCA_MY2020_Rx" SG_ 963 Courtesy_BSave_Stat 1;
BA_ "U_P702_MY2021_Rx" SG_ 963 Courtesy_BSave_Stat 1;
BA_ "GenSigStartValue" SG_ 963 Courtesy_BSave_Stat 1;
BA_ "GenSigStartValueInteger" SG_ 963 Courtesy_BSave_Stat 1;
BA_ "WakeupSignal" SG_ 963 Courtesy_BSave_Stat 1;
BA_ "U_CD542_MY2021_Rx" SG_ 963 DayRnngLampOn_B_Stat 1;
BA_ "U_T6_MCA_MY2020_Rx" SG_ 963 DayRnngLampOn_B_Stat 1;
BA_ "U_U55X_MY2022_Rx" SG_ 963 PerimeterAlarmChimeRq 1;
BA_ "U_CD542_MY2021_Rx" SG_ 963 PerimeterAlarmChimeRq 1;
BA_ "U_T6_MCA_MY2020_Rx" SG_ 963 PerimeterAlarmChimeRq 1;
BA_ "U_P702_MY2021_Rx" SG_ 963 PerimeterAlarmChimeRq 1;
BA_ "WakeupSignal" SG_ 963 PerimeterAlarmChimeRq 1;
BA_ "U_U55X_MY2022_Rx" SG_ 963 Perimeter_Alarm_Status 1;
BA_ "U_T6_MCA_MY2020_Rx" SG_ 963 Perimeter_Alarm_Status 1;
BA_ "U_P702_MY2021_Rx" SG_ 963 Perimeter_Alarm_Status 1;
BA_ "WakeupSignal" SG_ 963 Perimeter_Alarm_Status 1;
BA_ "WakeupSignal" SG_ 963 WndwGlbl_D_Cmd 1;
BA_ "U_CD542_MY2021_Rx" SG_ 963 DrTgateLck_D_Stat 1;
BA_ "U_T6_MCA_MY2020_Rx" SG_ 963 DrTgateLck_D_Stat 1;
BA_ "U_U55X_MY2022_Rx" SG_ 963 PudLamp_D_Rq 1;
BA_ "U_CD542_MY2021_Rx" SG_ 963 PudLamp_D_Rq 1;
BA_ "U_T6_MCA_MY2020_Rx" SG_ 963 PudLamp_D_Rq 1;
BA_ "WakeupSignal" SG_ 963 PudLamp_D_Rq 1;
BA_ "U_P702_MY2021_Rx" SG_ 949 Tire_Press_RR_ORR_Data 1;
BA_ "U_U55X_MY2022_Rx" SG_ 949 Tire_Press_RR_ORR_Data 1;
BA_ "U_CD542_MY2021_Rx" SG_ 949 Tire_Press_RR_ORR_Data 1;
BA_ "U_T6_MCA_MY2020_Rx" SG_ 949 Tire_Press_RR_ORR_Data 1;
BA_ "GenSigStartValue" SG_ 949 Tire_Press_RR_ORR_Data 65533;
BA_ "GenSigStartValueInteger" SG_ 949 Tire_Press_RR_ORR_Data 65533;
BA_ "U_P702_MY2021_Rx" SG_ 949 Tire_Press_LR_OLR_Data 1;
BA_ "U_U55X_MY2022_Rx" SG_ 949 Tire_Press_LR_OLR_Data 1;
BA_ "U_CD542_MY2021_Rx" SG_ 949 Tire_Press_LR_OLR_Data 1;
BA_ "U_T6_MCA_MY2020_Rx" SG_ 949 Tire_Press_LR_OLR_Data 1;
BA_ "GenSigStartValue" SG_ 949 Tire_Press_LR_OLR_Data 65533;
BA_ "GenSigStartValueInteger" SG_ 949 Tire_Press_LR_OLR_Data 65533;
BA_ "U_P702_MY2021_Rx" SG_ 949 Tire_Press_LF_Data 1;
BA_ "U_U55X_MY2022_Rx" SG_ 949 Tire_Press_LF_Data 1;
BA_ "U_CD542_MY2021_Rx" SG_ 949 Tire_Press_LF_Data 1;
BA_ "U_T6_MCA_MY2020_Rx" SG_ 949 Tire_Press_LF_Data 1;
BA_ "GenSigStartValue" SG_ 949 Tire_Press_LF_Data 65533;
BA_ "GenSigStartValueInteger" SG_ 949 Tire_Press_LF_Data 65533;
BA_ "U_P702_MY2021_Rx" SG_ 949 Tire_Press_RF_Data 1;
BA_ "U_U55X_MY2022_Rx" SG_ 949 Tire_Press_RF_Data 1;
BA_ "U_CD542_MY2021_Rx" SG_ 949 Tire_Press_RF_Data 1;
BA_ "U_T6_MCA_MY2020_Rx" SG_ 949 Tire_Press_RF_Data 1;
BA_ "GenSigStartValue" SG_ 949 Tire_Press_RF_Data 65533;
BA_ "GenSigStartValueInteger" SG_ 949 Tire_Press_RF_Data 65533;
BA_ "ECGUsedRxSignal" SG_ 2015 TesterFunctionalReq 1;
BA_ "U_CX727_MY2021_Rx" SG_ 2015 TesterFunctionalReq 1;
BA_ "U_U55X_MY2022_Rx" SG_ 2015 TesterFunctionalReq 1;
BA_ "U_CD542_MY2021_Rx" SG_ 2015 TesterFunctionalReq 1;
BA_ "U_T6_MCA_MY2020_Rx" SG_ 2015 TesterFunctionalReq 1;
BA_ "U_P702_MY2021_Rx" SG_ 2015 TesterFunctionalReq 1;
BA_ "GenSigSendType" SG_ 2015 TesterFunctionalReq 3;
BA_ "U_U55X_MY2022_Tx" SG_ 1076 AutoRgen_D_Rq 1;
BA_ "U_CD542_MY2021_Tx" SG_ 1076 AutoRgen_D_Rq 1;
BA_ "U_T6_MCA_MY2020_Tx" SG_ 1076 AutoRgen_D_Rq 1;
BA_ "U_P702_MY2021_Tx" SG_ 1076 AutoRgen_D_Rq 1;
BA_ "GenSigSendType" SG_ 1076 AutoRgen_D_Rq 3;
BA_ "U_U55X_MY2022_Tx" SG_ 1076 W2S_LAMP_OK 1;
BA_ "U_CD542_MY2021_Tx" SG_ 1076 W2S_LAMP_OK 1;
BA_ "U_T6_MCA_MY2020_Tx" SG_ 1076 W2S_LAMP_OK 1;
BA_ "U_P702_MY2021_Tx" SG_ 1076 W2S_LAMP_OK 1;
BA_ "GenSigSendType" SG_ 1076 W2S_LAMP_OK 3;
BA_ "GenSigStartValue" SG_ 1076 W2S_LAMP_OK 1;
BA_ "GenSigStartValueInteger" SG_ 1076 W2S_LAMP_OK 1;
BA_ "U_U55X_MY2022_Tx" SG_ 1076 OdoTripRx_B_Actl 1;
BA_ "U_CD542_MY2021_Tx" SG_ 1076 OdoTripRx_B_Actl 1;
BA_ "U_T6_MCA_MY2020_Tx" SG_ 1076 OdoTripRx_B_Actl 1;
BA_ "U_P702_MY2021_Tx" SG_ 1076 OdoTripRx_B_Actl 1;
BA_ "GenSigSendType" SG_ 1076 OdoTripRx_B_Actl 3;
BA_ "U_U55X_MY2022_Tx" SG_ 1076 Veh_V_CompLimMx 1;
BA_ "U_CD542_MY2021_Tx" SG_ 1076 Veh_V_CompLimMx 1;
BA_ "U_T6_MCA_MY2020_Tx" SG_ 1076 Veh_V_CompLimMx 1;
BA_ "U_P702_MY2021_Tx" SG_ 1076 Veh_V_CompLimMx 1;
BA_ "GenSigStartValue" SG_ 1076 Veh_V_CompLimMx 4093;
BA_ "GenSigStartValueInteger" SG_ 1076 Veh_V_CompLimMx 4095;
BA_ "U_U55X_MY2022_Tx" SG_ 1076 DrvSlipCtlMde_B_RqMyKey 1;
BA_ "U_CD542_MY2021_Tx" SG_ 1076 DrvSlipCtlMde_B_RqMyKey 1;
BA_ "U_T6_MCA_MY2020_Tx" SG_ 1076 DrvSlipCtlMde_B_RqMyKey 1;
BA_ "U_P702_MY2021_Tx" SG_ 1076 DrvSlipCtlMde_B_RqMyKey 1;
BA_ "GenSigSendType" SG_ 1076 DrvSlipCtlMde_B_RqMyKey 3;
BA_ "U_U55X_MY2022_Tx" SG_ 1076 FuelLvlWarn_D_Actl 1;
BA_ "U_CD542_MY2021_Tx" SG_ 1076 FuelLvlWarn_D_Actl 1;
BA_ "U_T6_MCA_MY2020_Tx" SG_ 1076 FuelLvlWarn_D_Actl 1;
BA_ "U_P702_MY2021_Tx" SG_ 1076 FuelLvlWarn_D_Actl 1;
BA_ "ECGUsedRxSignal" SG_ 1076 FuelLvlWarn_D_Actl 1;
BA_ "U_U55X_MY2022_Rx" SG_ 1076 FuelLvlWarn_D_Actl 1;
BA_ "U_CD542_MY2021_Rx" SG_ 1076 FuelLvlWarn_D_Actl 1;
BA_ "U_T6_MCA_MY2020_Rx" SG_ 1076 FuelLvlWarn_D_Actl 1;
BA_ "GenSigSendType" SG_ 1076 FuelLvlWarn_D_Actl 3;
BA_ "U_CD542_MY2021_Tx" SG_ 1076 DieslFuelBio_B_ActlDrv 1;
BA_ "U_T6_MCA_MY2020_Tx" SG_ 1076 DieslFuelBio_B_ActlDrv 1;
BA_ "GenSigSendType" SG_ 1076 DieslFuelBio_B_ActlDrv 3;
BA_ "U_U55X_MY2022_Tx" SG_ 1076 FuelSecndActv_B_Actl 1;
BA_ "U_CD542_MY2021_Tx" SG_ 1076 FuelSecndActv_B_Actl 1;
BA_ "U_T6_MCA_MY2020_Tx" SG_ 1076 FuelSecndActv_B_Actl 1;
BA_ "U_P702_MY2021_Tx" SG_ 1076 FuelSecndActv_B_Actl 1;
BA_ "GenSigSendType" SG_ 1076 FuelSecndActv_B_Actl 3;
BA_ "U_U55X_MY2022_Tx" SG_ 1076 HILL_DESC_SW 1;
BA_ "U_T6_MCA_MY2020_Tx" SG_ 1076 HILL_DESC_SW 1;
BA_ "U_P702_MY2021_Tx" SG_ 1076 HILL_DESC_SW 1;
BA_ "GenSigSendType" SG_ 1076 HILL_DESC_SW 3;
BA_ "U_U55X_MY2022_Tx" SG_ 1076 FuelLvlPssvSide_No_Raw 1;
BA_ "U_CD542_MY2021_Tx" SG_ 1076 FuelLvlPssvSide_No_Raw 1;
BA_ "U_T6_MCA_MY2020_Tx" SG_ 1076 FuelLvlPssvSide_No_Raw 1;
BA_ "U_P702_MY2021_Tx" SG_ 1076 FuelLvlPssvSide_No_Raw 1;
BA_ "U_U55X_MY2022_Tx" SG_ 1076 FUEL_SENSOR_NUM 1;
BA_ "U_CD542_MY2021_Tx" SG_ 1076 FUEL_SENSOR_NUM 1;
BA_ "U_T6_MCA_MY2020_Tx" SG_ 1076 FUEL_SENSOR_NUM 1;
BA_ "U_P702_MY2021_Tx" SG_ 1076 FUEL_SENSOR_NUM 1;
BA_ "GenSigSendType" SG_ 1076 FUEL_SENSOR_NUM 3;
BA_ "U_U55X_MY2022_Tx" SG_ 1076 FuelLvlActvSide_No_Raw 1;
BA_ "U_CD542_MY2021_Tx" SG_ 1076 FuelLvlActvSide_No_Raw 1;
BA_ "U_T6_MCA_MY2020_Tx" SG_ 1076 FuelLvlActvSide_No_Raw 1;
BA_ "U_P702_MY2021_Tx" SG_ 1076 FuelLvlActvSide_No_Raw 1;
BA_ "U_U55X_MY2022_Tx" SG_ 1076 FuelLvl_Pc_Dsply 1;
BA_ "U_CD542_MY2021_Tx" SG_ 1076 FuelLvl_Pc_Dsply 1;
BA_ "U_T6_MCA_MY2020_Tx" SG_ 1076 FuelLvl_Pc_Dsply 1;
BA_ "U_P702_MY2021_Tx" SG_ 1076 FuelLvl_Pc_Dsply 1;
BA_ "ECGUsedRxSignal" SG_ 1076 FuelLvl_Pc_Dsply 1;
BA_ "U_U55X_MY2022_Rx" SG_ 1076 FuelLvl_Pc_Dsply 1;
BA_ "U_CD542_MY2021_Rx" SG_ 1076 FuelLvl_Pc_Dsply 1;
BA_ "U_T6_MCA_MY2020_Rx" SG_ 1076 FuelLvl_Pc_Dsply 1;
BA_ "U_U55X_MY2022_Tx" SG_ 1076 DISPLAY_SPEED_SCALING 1;
BA_ "U_CD542_MY2021_Tx" SG_ 1076 DISPLAY_SPEED_SCALING 1;
BA_ "U_T6_MCA_MY2020_Tx" SG_ 1076 DISPLAY_SPEED_SCALING 1;
BA_ "U_P702_MY2021_Tx" SG_ 1076 DISPLAY_SPEED_SCALING 1;
BA_ "U_U55X_MY2022_Tx" SG_ 1076 TirePReset_B_Rq 1;
BA_ "U_CD542_MY2021_Tx" SG_ 1076 TirePReset_B_Rq 1;
BA_ "U_T6_MCA_MY2020_Tx" SG_ 1076 TirePReset_B_Rq 1;
BA_ "GenSigSendType" SG_ 1076 TirePReset_B_Rq 3;
BA_ "U_U55X_MY2022_Tx" SG_ 1076 DISPLAY_SPEED_OFFSET 1;
BA_ "U_CD542_MY2021_Tx" SG_ 1076 DISPLAY_SPEED_OFFSET 1;
BA_ "U_T6_MCA_MY2020_Tx" SG_ 1076 DISPLAY_SPEED_OFFSET 1;
BA_ "U_P702_MY2021_Tx" SG_ 1076 DISPLAY_SPEED_OFFSET 1;
BA_ "U_U55X_MY2022_Tx" SG_ 709 DSPAMP_RDISP_WORD_Tx 1;
BA_ "U_CD542_MY2021_Tx" SG_ 709 DSPAMP_RDISP_WORD_Tx 1;
BA_ "U_T6_MCA_MY2020_Tx" SG_ 709 DSPAMP_RDISP_WORD_Tx 1;
BA_ "U_P702_MY2021_Tx" SG_ 709 DSPAMP_RDISP_WORD_Tx 1;
BA_ "U_U55X_MY2022_Rx" SG_ 709 DSPAMP_RDISP_WORD_Tx 1;
BA_ "U_CD542_MY2021_Rx" SG_ 709 DSPAMP_RDISP_WORD_Tx 1;
BA_ "U_T6_MCA_MY2020_Rx" SG_ 709 DSPAMP_RDISP_WORD_Tx 1;
BA_ "U_P702_MY2021_Rx" SG_ 709 DSPAMP_RDISP_WORD_Tx 1;
BA_ "U_U55X_MY2022_Tx" SG_ 552 DSP_Treble_St 1;
BA_ "U_CD542_MY2021_Tx" SG_ 552 DSP_Treble_St 1;
BA_ "U_T6_MCA_MY2020_Tx" SG_ 552 DSP_Treble_St 1;
BA_ "U_P702_MY2021_Tx" SG_ 552 DSP_Treble_St 1;
BA_ "U_U55X_MY2022_Rx" SG_ 552 DSP_Treble_St 1;
BA_ "U_CD542_MY2021_Rx" SG_ 552 DSP_Treble_St 1;
BA_ "U_T6_MCA_MY2020_Rx" SG_ 552 DSP_Treble_St 1;
BA_ "U_P702_MY2021_Rx" SG_ 552 DSP_Treble_St 1;
BA_ "GenSigSendType" SG_ 552 DSP_Treble_St 3;
BA_ "U_U55X_MY2022_Tx" SG_ 552 DSP_VoiceFBVolume_Up 1;
BA_ "U_CD542_MY2021_Tx" SG_ 552 DSP_VoiceFBVolume_Up 1;
BA_ "U_T6_MCA_MY2020_Tx" SG_ 552 DSP_VoiceFBVolume_Up 1;
BA_ "U_P702_MY2021_Tx" SG_ 552 DSP_VoiceFBVolume_Up 1;
BA_ "U_CD542_MY2021_Rx" SG_ 552 DSP_VoiceFBVolume_Up 1;
BA_ "U_P702_MY2021_Rx" SG_ 552 DSP_VoiceFBVolume_Up 1;
BA_ "U_U55X_MY2022_Rx" SG_ 552 DSP_VoiceFBVolume_Up 1;
BA_ "U_T6_MCA_MY2020_Rx" SG_ 552 DSP_VoiceFBVolume_Up 1;
BA_ "GenSigSendType" SG_ 552 DSP_VoiceFBVolume_Up 1;
BA_ "U_U55X_MY2022_Tx" SG_ 552 DSP_VoiceFBVolume_St 1;
BA_ "U_CD542_MY2021_Tx" SG_ 552 DSP_VoiceFBVolume_St 1;
BA_ "U_T6_MCA_MY2020_Tx" SG_ 552 DSP_VoiceFBVolume_St 1;
BA_ "U_P702_MY2021_Tx" SG_ 552 DSP_VoiceFBVolume_St 1;
BA_ "U_CD542_MY2021_Rx" SG_ 552 DSP_VoiceFBVolume_St 1;
BA_ "U_P702_MY2021_Rx" SG_ 552 DSP_VoiceFBVolume_St 1;
BA_ "U_U55X_MY2022_Rx" SG_ 552 DSP_VoiceFBVolume_St 1;
BA_ "U_T6_MCA_MY2020_Rx" SG_ 552 DSP_VoiceFBVolume_St 1;
BA_ "U_U55X_MY2022_Tx" SG_ 552 DSP_TAVolume_Up 1;
BA_ "U_CD542_MY2021_Tx" SG_ 552 DSP_TAVolume_Up 1;
BA_ "U_T6_MCA_MY2020_Tx" SG_ 552 DSP_TAVolume_Up 1;
BA_ "U_P702_MY2021_Tx" SG_ 552 DSP_TAVolume_Up 1;
BA_ "U_CD542_MY2021_Rx" SG_ 552 DSP_TAVolume_Up 1;
BA_ "U_P702_MY2021_Rx" SG_ 552 DSP_TAVolume_Up 1;
BA_ "U_U55X_MY2022_Rx" SG_ 552 DSP_TAVolume_Up 1;
BA_ "U_T6_MCA_MY2020_Rx" SG_ 552 DSP_TAVolume_Up 1;
BA_ "GenSigSendType" SG_ 552 DSP_TAVolume_Up 1;
BA_ "U_U55X_MY2022_Tx" SG_ 552 DSP_TAVolume_St 1;
BA_ "U_CD542_MY2021_Tx" SG_ 552 DSP_TAVolume_St 1;
BA_ "U_T6_MCA_MY2020_Tx" SG_ 552 DSP_TAVolume_St 1;
BA_ "U_P702_MY2021_Tx" SG_ 552 DSP_TAVolume_St 1;
BA_ "U_CD542_MY2021_Rx" SG_ 552 DSP_TAVolume_St 1;
BA_ "U_P702_MY2021_Rx" SG_ 552 DSP_TAVolume_St 1;
BA_ "U_U55X_MY2022_Rx" SG_ 552 DSP_TAVolume_St 1;
BA_ "U_T6_MCA_MY2020_Rx" SG_ 552 DSP_TAVolume_St 1;
BA_ "U_CD542_MY2021_Tx" SG_ 552 DSP_Shaker_St 1;
BA_ "U_U55X_MY2022_Rx" SG_ 552 DSP_Shaker_St 1;
BA_ "U_CD542_MY2021_Rx" SG_ 552 DSP_Shaker_St 1;
BA_ "U_P702_MY2021_Rx" SG_ 552 DSP_Shaker_St 1;
BA_ "GenSigSendType" SG_ 552 DSP_Shaker_St 3;
BA_ "U_U55X_MY2022_Tx" SG_ 552 DSP_Reg_St 1;
BA_ "U_CD542_MY2021_Tx" SG_ 552 DSP_Reg_St 1;
BA_ "U_T6_MCA_MY2020_Tx" SG_ 552 DSP_Reg_St 1;
BA_ "U_P702_MY2021_Tx" SG_ 552 DSP_Reg_St 1;
BA_ "U_U55X_MY2022_Rx" SG_ 552 DSP_Reg_St 1;
BA_ "U_CD542_MY2021_Rx" SG_ 552 DSP_Reg_St 1;
BA_ "U_T6_MCA_MY2020_Rx" SG_ 552 DSP_Reg_St 1;
BA_ "U_P702_MY2021_Rx" SG_ 552 DSP_Reg_St 1;
BA_ "GenSigSendType" SG_ 552 DSP_Reg_St 3;
BA_ "U_U55X_MY2022_Tx" SG_ 552 DSP_PhoneVolume_Up 1;
BA_ "U_CD542_MY2021_Tx" SG_ 552 DSP_PhoneVolume_Up 1;
BA_ "U_T6_MCA_MY2020_Tx" SG_ 552 DSP_PhoneVolume_Up 1;
BA_ "U_P702_MY2021_Tx" SG_ 552 DSP_PhoneVolume_Up 1;
BA_ "U_CD542_MY2021_Rx" SG_ 552 DSP_PhoneVolume_Up 1;
BA_ "U_P702_MY2021_Rx" SG_ 552 DSP_PhoneVolume_Up 1;
BA_ "U_U55X_MY2022_Rx" SG_ 552 DSP_PhoneVolume_Up 1;
BA_ "U_T6_MCA_MY2020_Rx" SG_ 552 DSP_PhoneVolume_Up 1;
BA_ "GenSigSendType" SG_ 552 DSP_PhoneVolume_Up 1;
BA_ "U_U55X_MY2022_Tx" SG_ 552 DSP_PhoneVolume_St 1;
BA_ "U_CD542_MY2021_Tx" SG_ 552 DSP_PhoneVolume_St 1;
BA_ "U_T6_MCA_MY2020_Tx" SG_ 552 DSP_PhoneVolume_St 1;
BA_ "U_P702_MY2021_Tx" SG_ 552 DSP_PhoneVolume_St 1;
BA_ "U_CD542_MY2021_Rx" SG_ 552 DSP_PhoneVolume_St 1;
BA_ "U_P702_MY2021_Rx" SG_ 552 DSP_PhoneVolume_St 1;
BA_ "U_U55X_MY2022_Rx" SG_ 552 DSP_PhoneVolume_St 1;
BA_ "U_T6_MCA_MY2020_Rx" SG_ 552 DSP_PhoneVolume_St 1;
BA_ "U_U55X_MY2022_Tx" SG_ 552 DSP_NavCmdVolume_Up 1;
BA_ "U_CD542_MY2021_Tx" SG_ 552 DSP_NavCmdVolume_Up 1;
BA_ "U_T6_MCA_MY2020_Tx" SG_ 552 DSP_NavCmdVolume_Up 1;
BA_ "U_P702_MY2021_Tx" SG_ 552 DSP_NavCmdVolume_Up 1;
BA_ "U_CD542_MY2021_Rx" SG_ 552 DSP_NavCmdVolume_Up 1;
BA_ "U_P702_MY2021_Rx" SG_ 552 DSP_NavCmdVolume_Up 1;
BA_ "U_U55X_MY2022_Rx" SG_ 552 DSP_NavCmdVolume_Up 1;
BA_ "U_T6_MCA_MY2020_Rx" SG_ 552 DSP_NavCmdVolume_Up 1;
BA_ "GenSigSendType" SG_ 552 DSP_NavCmdVolume_Up 1;
BA_ "U_U55X_MY2022_Tx" SG_ 552 DSP_NavCmdVolume_St 1;
BA_ "U_CD542_MY2021_Tx" SG_ 552 DSP_NavCmdVolume_St 1;
BA_ "U_T6_MCA_MY2020_Tx" SG_ 552 DSP_NavCmdVolume_St 1;
BA_ "U_P702_MY2021_Tx" SG_ 552 DSP_NavCmdVolume_St 1;
BA_ "U_CD542_MY2021_Rx" SG_ 552 DSP_NavCmdVolume_St 1;
BA_ "U_P702_MY2021_Rx" SG_ 552 DSP_NavCmdVolume_St 1;
BA_ "U_U55X_MY2022_Rx" SG_ 552 DSP_NavCmdVolume_St 1;
BA_ "U_T6_MCA_MY2020_Rx" SG_ 552 DSP_NavCmdVolume_St 1;
BA_ "U_U55X_MY2022_Tx" SG_ 552 DSP_Midrange_St 1;
BA_ "U_CD542_MY2021_Tx" SG_ 552 DSP_Midrange_St 1;
BA_ "U_T6_MCA_MY2020_Tx" SG_ 552 DSP_Midrange_St 1;
BA_ "U_P702_MY2021_Tx" SG_ 552 DSP_Midrange_St 1;
BA_ "U_U55X_MY2022_Rx" SG_ 552 DSP_Midrange_St 1;
BA_ "U_CD542_MY2021_Rx" SG_ 552 DSP_Midrange_St 1;
BA_ "U_T6_MCA_MY2020_Rx" SG_ 552 DSP_Midrange_St 1;
BA_ "U_P702_MY2021_Rx" SG_ 552 DSP_Midrange_St 1;
BA_ "GenSigSendType" SG_ 552 DSP_Midrange_St 3;
BA_ "U_U55X_MY2022_Tx" SG_ 552 DSP_Fader_St 1;
BA_ "U_CD542_MY2021_Tx" SG_ 552 DSP_Fader_St 1;
BA_ "U_T6_MCA_MY2020_Tx" SG_ 552 DSP_Fader_St 1;
BA_ "U_P702_MY2021_Tx" SG_ 552 DSP_Fader_St 1;
BA_ "U_U55X_MY2022_Rx" SG_ 552 DSP_Fader_St 1;
BA_ "U_CD542_MY2021_Rx" SG_ 552 DSP_Fader_St 1;
BA_ "U_T6_MCA_MY2020_Rx" SG_ 552 DSP_Fader_St 1;
BA_ "U_P702_MY2021_Rx" SG_ 552 DSP_Fader_St 1;
BA_ "GenSigSendType" SG_ 552 DSP_Fader_St 3;
BA_ "U_U55X_MY2022_Tx" SG_ 552 DSP_DSPProgram_St 1;
BA_ "U_T6_MCA_MY2020_Tx" SG_ 552 DSP_DSPProgram_St 1;
BA_ "U_P702_MY2021_Tx" SG_ 552 DSP_DSPProgram_St 1;
BA_ "U_CD542_MY2021_Rx" SG_ 552 DSP_DSPProgram_St 1;
BA_ "U_U55X_MY2022_Rx" SG_ 552 DSP_DSPProgram_St 1;
BA_ "U_T6_MCA_MY2020_Rx" SG_ 552 DSP_DSPProgram_St 1;
BA_ "U_P702_MY2021_Rx" SG_ 552 DSP_DSPProgram_St 1;
BA_ "GenSigSendType" SG_ 552 DSP_DSPProgram_St 3;
BA_ "U_U55X_MY2022_Tx" SG_ 552 DSP_DSP_St 1;
BA_ "U_T6_MCA_MY2020_Tx" SG_ 552 DSP_DSP_St 1;
BA_ "U_P702_MY2021_Tx" SG_ 552 DSP_DSP_St 1;
BA_ "U_CD542_MY2021_Rx" SG_ 552 DSP_DSP_St 1;
BA_ "U_U55X_MY2022_Rx" SG_ 552 DSP_DSP_St 1;
BA_ "U_T6_MCA_MY2020_Rx" SG_ 552 DSP_DSP_St 1;
BA_ "U_P702_MY2021_Rx" SG_ 552 DSP_DSP_St 1;
BA_ "GenSigSendType" SG_ 552 DSP_DSP_St 3;
BA_ "U_U55X_MY2022_Tx" SG_ 552 DSP_Bass_St 1;
BA_ "U_CD542_MY2021_Tx" SG_ 552 DSP_Bass_St 1;
BA_ "U_T6_MCA_MY2020_Tx" SG_ 552 DSP_Bass_St 1;
BA_ "U_P702_MY2021_Tx" SG_ 552 DSP_Bass_St 1;
BA_ "U_U55X_MY2022_Rx" SG_ 552 DSP_Bass_St 1;
BA_ "U_CD542_MY2021_Rx" SG_ 552 DSP_Bass_St 1;
BA_ "U_T6_MCA_MY2020_Rx" SG_ 552 DSP_Bass_St 1;
BA_ "U_P702_MY2021_Rx" SG_ 552 DSP_Bass_St 1;
BA_ "GenSigSendType" SG_ 552 DSP_Bass_St 3;
BA_ "U_U55X_MY2022_Tx" SG_ 552 DSP_Balance_St 1;
BA_ "U_CD542_MY2021_Tx" SG_ 552 DSP_Balance_St 1;
BA_ "U_T6_MCA_MY2020_Tx" SG_ 552 DSP_Balance_St 1;
BA_ "U_P702_MY2021_Tx" SG_ 552 DSP_Balance_St 1;
BA_ "U_U55X_MY2022_Rx" SG_ 552 DSP_Balance_St 1;
BA_ "U_CD542_MY2021_Rx" SG_ 552 DSP_Balance_St 1;
BA_ "U_T6_MCA_MY2020_Rx" SG_ 552 DSP_Balance_St 1;
BA_ "U_P702_MY2021_Rx" SG_ 552 DSP_Balance_St 1;
BA_ "GenSigSendType" SG_ 552 DSP_Balance_St 3;
BA_ "U_U55X_MY2022_Tx" SG_ 552 DSP_AVC_St 1;
BA_ "U_CD542_MY2021_Tx" SG_ 552 DSP_AVC_St 1;
BA_ "U_T6_MCA_MY2020_Tx" SG_ 552 DSP_AVC_St 1;
BA_ "U_P702_MY2021_Tx" SG_ 552 DSP_AVC_St 1;
BA_ "U_U55X_MY2022_Rx" SG_ 552 DSP_AVC_St 1;
BA_ "U_CD542_MY2021_Rx" SG_ 552 DSP_AVC_St 1;
BA_ "U_T6_MCA_MY2020_Rx" SG_ 552 DSP_AVC_St 1;
BA_ "U_P702_MY2021_Rx" SG_ 552 DSP_AVC_St 1;
BA_ "GenSigSendType" SG_ 552 DSP_AVC_St 3;
BA_ "U_U55X_MY2022_Tx" SG_ 552 Audio_Demo_Status 1;
BA_ "U_CD542_MY2021_Tx" SG_ 552 Audio_Demo_Status 1;
BA_ "U_T6_MCA_MY2020_Tx" SG_ 552 Audio_Demo_Status 1;
BA_ "U_P702_MY2021_Tx" SG_ 552 Audio_Demo_Status 1;
BA_ "U_U55X_MY2022_Rx" SG_ 552 Audio_Demo_Status 1;
BA_ "U_CD542_MY2021_Rx" SG_ 552 Audio_Demo_Status 1;
BA_ "U_T6_MCA_MY2020_Rx" SG_ 552 Audio_Demo_Status 1;
BA_ "U_P702_MY2021_Rx" SG_ 552 Audio_Demo_Status 1;
BA_ "GenSigSendType" SG_ 552 Audio_Demo_Status 3;
BA_ "U_U55X_MY2022_Rx" SG_ 967 CamZoomActiveState 1;
BA_ "U_CD542_MY2021_Rx" SG_ 967 CamZoomActiveState 1;
BA_ "U_T6_MCA_MY2020_Rx" SG_ 967 CamZoomActiveState 1;
BA_ "U_U55X_MY2022_Rx" SG_ 967 CamraViewSplit_D_Actl 1;
BA_ "U_CD542_MY2021_Rx" SG_ 967 CamraViewSplit_D_Actl 1;
BA_ "U_T6_MCA_MY2020_Rx" SG_ 967 CamraViewSplit_D_Actl 1;
BA_ "GenSigStartValue" SG_ 967 CamraViewSplit_D_Actl 2;
BA_ "GenSigStartValueInteger" SG_ 967 CamraViewSplit_D_Actl 2;
BA_ "U_U55X_MY2022_Rx" SG_ 967 CamraOvrlTow_D_Actl 1;
BA_ "U_CD542_MY2021_Rx" SG_ 967 CamraOvrlTow_D_Actl 1;
BA_ "U_T6_MCA_MY2020_Rx" SG_ 967 CamraOvrlTow_D_Actl 1;
BA_ "U_U55X_MY2022_Rx" SG_ 967 CamraZoomMan_D_Actl 1;
BA_ "U_CD542_MY2021_Rx" SG_ 967 CamraZoomMan_D_Actl 1;
BA_ "U_T6_MCA_MY2020_Rx" SG_ 967 CamraZoomMan_D_Actl 1;
BA_ "U_U55X_MY2022_Rx" SG_ 967 CamraOvrlStat_D_Actl 1;
BA_ "U_CD542_MY2021_Rx" SG_ 967 CamraOvrlStat_D_Actl 1;
BA_ "U_T6_MCA_MY2020_Rx" SG_ 967 CamraOvrlStat_D_Actl 1;
BA_ "U_U55X_MY2022_Rx" SG_ 967 CamraOvrlDyn_D_Actl 1;
BA_ "U_CD542_MY2021_Rx" SG_ 967 CamraOvrlDyn_D_Actl 1;
BA_ "U_T6_MCA_MY2020_Rx" SG_ 967 CamraOvrlDyn_D_Actl 1;
BA_ "U_U55X_MY2022_Rx" SG_ 967 CamPDCGuidStat 1;
BA_ "U_CD542_MY2021_Rx" SG_ 967 CamPDCGuidStat 1;
BA_ "U_T6_MCA_MY2020_Rx" SG_ 967 CamPDCGuidStat 1;
VAL_ 729 ACU_VoiceFBVolume_Up 1 "Update" 0 "NoUpdate" ;
VAL_ 729 ACU_TAVolume_Up 1 "Update" 0 "NoUpdate" ;
VAL_ 729 ACU_Reg_St 0 "Invalid" 1 "Off" 2 "On" ;
VAL_ 729 ACU_PhoneVolume_Up 1 "Update" 0 "NoUpdate" ;
VAL_ 729 ACU_NavCmdVolume_Up 1 "Update" 0 "NoUpdate" ;
VAL_ 729 ACU_DSPProgram_St 7 "Reserved2" 6 "Reserved1" 5 "Voice" 4 "Rock" 0 "Invalid" 1 "Normal" 2 "Pop" 3 "Classical" ;
VAL_ 729 ACU_DSP_St 15 "Reserved" 9 "Convertible" 8 "RearSeats" 7 "FrontSeats" 0 "Invalid" 1 "All" 2 "Driver" 3 "Passenger" 4 "Reserved1" 5 "Reserved2" 6 "Reserved3" ;
VAL_ 727 ACU_LoadEjectMode_St 0 "Invalid" 1 "LoadModeInactiveDiscNumIgnored" 2 "LoadModeActiveDiscNumIgnored" 3 "PreparingToLoad" 4 "Insert" 5 "Loading" 6 "PreparingToEject" 7 "Ejecting" 8 "RemoveDisc" ;
VAL_ 727 ACU_LoadEjectDisc_St 0 "Invalid" 1 "Disc1" 2 "Disc2" 3 "Disc3" 4 "Disc4" 5 "Disc5" 6 "Disc6" 7 "All" ;
VAL_ 726 ACU_TAMode_St 0 "Invalid" 1 "TaLocalOn" 2 "TaDistantOn" 3 "TaOff" ;
VAL_ 726 ACU_NEWSMode_St 0 "Invalid" 1 "NewsOn" 2 "NewsOff" ;
VAL_ 726 ACU_AFJump_St 2 "Enabled" 1 "Inhibited" 0 "NoDataExists" ;
VAL_ 369 CrawlMdeActv_B_Stat 1 "On" 0 "Off" ;
VAL_ 369 DrvPerfMde_D_DsplyPt 3 "Sport" 2 "Normal" 1 "NotUsed" 0 "NoModeSelected" ;
VAL_ 369 SeatWorkSrfc_B_Falt 1 "Active" 0 "Inactive" ;
VAL_ 369 TrnIpcDsplyRng_D_Stat 3 "NotUsed" 2 "Flash" 1 "On" 0 "Blank_No_Display" ;
VAL_ 369 TrnIpcDsplyGear_D_Actl 15 "No_Gear_Selected" 14 "_14th_Gear" 13 "_13th_Gear" 12 "_12th_Gear" 11 "_11th_Gear" 10 "_10th_Gear" 9 "_9th_Gear" 8 "_8th_Gear" 7 "_7th_Gear" 6 "_6th_Gear" 5 "_5th_Gear" 4 "_4th_Gear" 3 "_3rd_Gear" 2 "_2nd_Gear" 1 "_1st_Gear" 0 "Neutral" ;
VAL_ 369 TrnIpcDsplyMde_D_Stat 3 "Reserved_Blank_No_Display" 2 "Flash" 1 "On" 0 "Blank_No_Display" ;
VAL_ 369 TrnIpcDsplyMde_D_Actl 7 "Manual_3" 6 "Manual_2" 5 "Manual_1_Low" 4 "Sport" 3 "Drive" 2 "Neutral" 1 "Reverse" 0 "Park" ;
VAL_ 369 TrnIpcDsplyGear_D_Stat 3 "Reserved_Blank_No_Display" 2 "Flash" 1 "On" 0 "Blank_No_Display" ;
VAL_ 369 TrnIpcDsplyRng2_D_Actl 15 "No_Range_Selected" 14 "Range_14" 13 "Range_13" 12 "Range_12" 11 "Range_11" 10 "Range_10" 9 "Range_9" 8 "Range_8" 7 "Range_7" 6 "Range_6" 5 "Range_5" 4 "Range_4" 3 "Range_3" 2 "Range_2" 1 "Range_1" 0 "NotUsed" ;
VAL_ 1071 CluPdlPosPcMeas_D_Qf 3 "OK" 2 "Not_Within_Specifications" 1 "No_Data_Exists" 0 "Faulty" ;
VAL_ 1071 EngMnfld3_P_Actl 255 "Faulty" 254 "NoDataExists" ;
VAL_ 848 RILStat 3 "Fault" 2 "Plant_Mode" 1 "On" 0 "Off" ;
VAL_ 891 CabnSndAmb2_Db_Actl 255 "Fault" ;
VAL_ 839 FohStop_B_Stat 3 "Unknown" 2 "NotUsed" 1 "Enable" 0 "Disable" ;
VAL_ 839 FohMsgTxt_D_Rq 4 "BatteryNotFullyCharged" 3 "Exceed7DaysFromLastEngRun" 2 "AmbientTemperatureTooHigh" 1 "LowFuel" 0 "NoMessage" ;
VAL_ 839 FohKeyOff_B_Rq 1 "Enable" 0 "Disable" ;
VAL_ 839 FohEnbl_B_Rq 1 "Enable" 0 "Disable" ;
VAL_ 839 FohTAllEnable_B_Stat 3 "Unknown" 2 "NotUsed" 1 "Enable" 0 "Disable" ;
VAL_ 839 FohT2Enable_B_Stat 1 "Enable" 0 "Disable" ;
VAL_ 839 FohT1Enable_B_Stat 1 "Enable" 0 "Disable" ;
VAL_ 839 FohStrtEnable_B_Stat 1 "Enable" 0 "Disable" ;
VAL_ 839 FohContOn_B_Stat 3 "Unknown" 2 "NotUsed" 1 "Enable" 0 "Disable" ;
VAL_ 839 FohStrtDay_T_Stat 7 "Sunday" 6 "Saturday" 5 "Friday" 4 "Thursday" 3 "Wednesday" 2 "Tuesday" 1 "Monday" 0 "NotUsed" ;
VAL_ 839 FohT2Wednesday_T_Stat 1 "Enable" 0 "Disable" ;
VAL_ 839 FohT2Tuesday_T_Stat 1 "Enable" 0 "Disable" ;
VAL_ 839 FohT2Thursday_T_Stat 1 "Enable" 0 "Disable" ;
VAL_ 839 FohT2Sunday_T_Stat 1 "Enable" 0 "Disable" ;
VAL_ 839 FohT2Saturday_T_Stat 1 "Enable" 0 "Disable" ;
VAL_ 839 FohT2Monday_T_Stat 1 "Enable" 0 "Disable" ;
VAL_ 839 FohT2Friday_T_Stat 1 "Enable" 0 "Disable" ;
VAL_ 839 FohT1Wednesday_T_Stat 1 "Enable" 0 "Disable" ;
VAL_ 839 FohT1Tuesday_T_Stat 1 "Enable" 0 "Disable" ;
VAL_ 839 FohT1Thursday_T_Stat 1 "Enable" 0 "Disable" ;
VAL_ 839 FohT1Sunday_T_Stat 1 "Enable" 0 "Disable" ;
VAL_ 839 FohT1Saturday_T_Stat 1 "Enable" 0 "Disable" ;
VAL_ 839 FohT1Monday_T_Stat 1 "Enable" 0 "Disable" ;
VAL_ 839 FohT1Friday_T_Stat 1 "Enable" 0 "Disable" ;
VAL_ 1091 CamraRearOn_D2_Stat2 7 "Faulty" 6 "NotUsed_3" 5 "NotUsed_2" 4 "NotUsed_1" 3 "Decommission" 2 "Activate" 1 "Deactivate" 0 "Null" ;
VAL_ 1091 PoliceAux4Lamp_B_Rq2 1 "On" 0 "Off" ;
VAL_ 1091 PoliceAux3Lamp_B_Rq2 1 "On" 0 "Off" ;
VAL_ 1091 PoliceAux2Lamp_B_Rq2 1 "On" 0 "Off" ;
VAL_ 1091 PoliceAux1Lamp_B_Rq2 1 "On" 0 "Off" ;
VAL_ 1091 WakeAlarm2_B_Typ 1 "CanAndEcuDriveCircuit" 0 "CanOnly" ;
VAL_ 1091 TrlrAlarmSpprt_D_Stat 3 "SupportedByBrakesAndLights" 2 "SupportedByLights" 1 "SupportedByBrakes" 0 "NotSupported" ;
VAL_ 1091 TowBarMsgTxt_D_Rq 7 "NotUsed3" 6 "NotUsed2" 5 "NotUsed1" 4 "TowBar_Ext_No_Trlr" 3 "Error_Dealer_Fix" 2 "Start_Engine_Swivel" 1 "Check_Tow_Bar" 0 "Null" ;
VAL_ 1091 ParkLampTrlrOut_B_Stat 1 "Out" 0 "Null" ;
VAL_ 1091 TrlrLampCtl_D_Stat 3 "NotUsed" 2 "TrlrLampCnnctDrvFailure" 1 "TrlrLampNotCnnctDrvFailure" 0 "Null" ;
VAL_ 1091 TrlrBattChrg_D_Stat 3 "Reverse" 2 "Normal" 1 "Low" 0 "Null" ;
VAL_ 1091 StopLampTrlrOut_B_Stat 1 "Out" 0 "Null" ;
VAL_ 1091 TurnLampTrlrRr_B_Stat 1 "Out" 0 "Null" ;
VAL_ 1091 TurnLampTrlrRl_B_Stat 1 "Out" 0 "Null" ;
VAL_ 1091 TrlrLampCnnct_B_Actl 1 "Yes" 0 "No" ;
VAL_ 998 PersIndexSccm_D_Actl 7 "Unused_3" 6 "Unused_2" 5 "Unused_1" 4 "Vehicle" 3 "PERS_4" 2 "PERS_3" 1 "PERS_2" 0 "PERS_1" ;
VAL_ 984 DsmcMsgTxt_D_Dsply 3 "Blockage" 2 "DriverNotSeen" 1 "Fault" 0 "NoMessage" ;
VAL_ 984 AhbcHiBeam_D_Rq 3 "Deactivated_Unavailabl" 2 "Unused" 1 "Main_HighBeamRecommend" 0 "Dipped_LowBeamRecommend" ;
VAL_ 984 AhbcStat_B_Dsply 1 "On" 0 "Off" ;
VAL_ 984 AhbHiBeam_D_Rq 3 "NotUsed" 2 "HighBeamRecommended" 1 "LowBeamRecommended" 0 "DeactivatedUnavailable" ;
VAL_ 984 DasWarn_D_Dsply 3 "Undefined" 2 "Warning_Level_2" 1 "Warning_Level_1" 0 "No_Warning" ;
VAL_ 984 DasStats_D_Dsply 3 "Available" 2 "Unavailable_Other" 1 "Feedback_due_to_Speed" 0 "Off" ;
VAL_ 984 DasAlrtLvl_D_Dsply 5 "Alertness_Level_5" 4 "Alertness_Level_4" 3 "Alertness_Level_3" 2 "Alertness_Level_2" 1 "Alertness_Level_1" 0 "Undefined" ;
VAL_ 984 CamraStats_D_Dsply 3 "FrtCam_TempUnavailOther" 2 "FrtCam_TempUnavailVisibile" 1 "Front_Camera_Service_Reqd" 0 "Front_Camera_OK" ;
VAL_ 984 LaHandsOff_D_Dsply 3 "Suppressed" 2 "Level2" 1 "Level1" 0 "HandsOn" ;
VAL_ 984 LaDenyStats_B_Dsply 1 "Unavailable" 0 "Available" ;
VAL_ 984 LaActvStats_D_Dsply 31 "Unused7" 30 "LA_Off" 29 "Unused5" 28 "Unused4" 27 "Unused3" 26 "Unused2" 25 "Unused1" 24 "InerveneLeft_InterveneRght" 23 "WarnLeft_InterveneRight" 22 "SuppressLeft_InterveneRght" 21 "AvailLeft_InterveneRhtt" 20 "NoLeft_InterveneRight" 19 "InterveneLeft_WarnRight" 18 "WarnLeft_WarnRight" 17 "SuppressLeft_WarnRight" 16 "AvailableLeft_WarnRight" 15 "NoLeft_WarnRight" 14 "InterveneLeft_SuppressRght" 13 "WarnLeft_SuppressRight" 12 "SuppressLeft_SuppressRight" 11 "AvailLeft_SuppressRight" 10 "NoLeft_SuppressRight" 9 "InterveneLeft_AvailRight" 8 "WarnLeft_AvailRight" 7 "SuppressLeft_AvailRight" 6 "AvailableLeft_AvailRight" 5 "NoLeft_AvailableRight" 4 "InterveneLeft_NoRight" 3 "WarnLeft_NoRight" 2 "SuppressLeft_NoRight" 1 "AvailableLeft_NoRight" 0 "NoLeft_NoRight" ;
VAL_ 984 AhbcRampingV_D_Rq 3 "Slow" 2 "Medium" 1 "Fast" 0 "Immediately" ;
VAL_ 984 CamraDefog_B_Req 1 "On" 0 "Off" ;
VAL_ 984 PersIndexIpma_D_Actl 7 "Unused_3" 6 "Unused_2" 5 "Unused_1" 4 "Vehicle" 3 "PERS_4" 2 "PERS_3" 1 "PERS_2" 0 "PERS_1" ;
VAL_ 1072 PtDrvMde_D_Rq 15 "Faulty" 14 "NotUsed11" 13 "NotUsed10" 12 "NotUsed9" 11 "NotUsed8" 10 "NotUsed7" 9 "NotUsed6" 8 "Track" 7 "Drag" 6 "Rock" 5 "Baja" 4 "Sand" 3 "TowHaulGradeAssist" 2 "SnowWet" 1 "Sport" 0 "Normal" ;
VAL_ 1072 DrvSlipCtlMde_D_Rq 3 "App_Specific_Off_Mode_3" 2 "App_Specific_Off_Mode_2" 1 "App_Specific_Off_Mode_1" 0 "Default_Mode" ;
VAL_ 1072 EngIdlShutDown_B_RqDrv 1 "Inhibit" 0 "No_Inibit" ;
VAL_ 1072 DrvPerfMde_D_Rq 3 "Sport" 2 "Normal" 1 "NotUsed" 0 "NoModeSelected" ;
VAL_ 1072 HaDsplyCpblty_B_Stat 1 "Available" 0 "NotAvailable" ;
VAL_ 1072 HsaMde_D_Rq 3 "Undefined" 2 "Manual" 1 "Automatic" 0 "Off" ;
VAL_ 1072 StopStrtDrvMde_D_RqMnu 3 "NotUsed2" 2 "NotUsed1" 1 "StopStart_Deselected" 0 "StopStart_Selected" ;
VAL_ 1072 NtrlTowMdeEnbl_B_RqDrv 1 "Yes" 0 "No" ;
VAL_ 1072 LscmbbStat_B_Actl 1 "On" 0 "Off" ;
VAL_ 1072 BulbChkActv_B_Stat 1 "Active" 0 "Inactive" ;
VAL_ 1072 ParkDetect_Stat 1 "Park" 0 "Not_Park" ;
VAL_ 1072 ReducedGuard_D_Rq 3 "NotUsed" 2 "On" 1 "Off" 0 "Null" ;
VAL_ 1072 FrostWarn_D_Stat 3 "NotUsed" 2 "On_Amber" 1 "On_Red" 0 "Off" ;
VAL_ 1072 TrlrBrkMde_D_Rq 1 "ElectricOverHydraulic" 0 "Electric" ;
VAL_ 1072 TRLR_SWAY_CONFIG_CMD 1 "On" 0 "Off" ;
VAL_ 1072 TRAILER_BRAKE_CONFIG 1 "Yes" 0 "No" ;
VAL_ 1072 Power_Liftgate_Mode_Cmd 1 "Enable" 0 "Disable" ;
VAL_ 1072 AccEnbl_B_RqDrv 1 "Adaptive_Cruise" 0 "Normal_Cruise" ;
VAL_ 1072 OdometerMasterValue 16777215 "Invalid" ;
VAL_ 1072 EngOilLife_B_RqReset 1 "Yes" 0 "No" ;
VAL_ 1072 MetricActvTe_B_Actl 1 "Active" 0 "Inactive" ;
VAL_ 1072 AccDeny_B_RqIpc 1 "Yes" 0 "No" ;
VAL_ 1072 ePRNDL_MODE 1 "On" 0 "Off" ;
VAL_ 1072 PrkLckCtlEnbl_D_RqIpc 3 "Rq_Towing" 2 "Rq_Enable" 1 "Rq_Disable" 0 "Null" ;
VAL_ 1072 DrvSlipCtlMde_B_Rq2 1 "Pressed" 0 "Not_Pressed" ;
VAL_ 1072 Fda_B_Stat 1 "On" 0 "Off" ;
VAL_ 1072 MetricActv_B_Actl 1 "Active" 0 "Inactive" ;
VAL_ 1072 KeyTypeChngMykey_D_Rq 3 "Search_PE_BackupSlot" 2 "Clear_All_MyKeys" 1 "Request_New_MyKey" 0 "None" ;
VAL_ 1072 ManRgen_D_Rq 3 "NotUsed2" 2 "NotUsed1" 1 "CustInitManExhFilterClean" 0 "No_Customer_Request" ;
VAL_ 395 SelDrvMdeCnfm_D_Stat 3 "NotUsed" 2 "Accepted" 1 "NotAccepted" 0 "Null" ;
VAL_ 395 HudMde_D_Rq 7 "NotUsed3" 6 "NotUsed2" 5 "NotUsed1" 4 "Manual" 3 "Drag" 2 "RoadCourse" 1 "Tach" 0 "Off" ;
VAL_ 395 HudLedMde_D_Rq 3 "Not_Used" 2 "Flash" 1 "On" 0 "Off" ;
VAL_ 395 HudLed9On_B_Rq 1 "On" 0 "Off" ;
VAL_ 395 HudLed8On_B_Rq 1 "On" 0 "Off" ;
VAL_ 395 HudLed7On_B_Rq 1 "On" 0 "Off" ;
VAL_ 395 HudLed6On_B_Rq 1 "On" 0 "Off" ;
VAL_ 395 HudLed5On_B_Rq 1 "On" 0 "Off" ;
VAL_ 395 HudLed4On_B_Rq 1 "On" 0 "Off" ;
VAL_ 395 HudLed3On_B_Rq 1 "On" 0 "Off" ;
VAL_ 395 HudLed2On_B_Rq 1 "On" 0 "Off" ;
VAL_ 395 HudLed1On_B_Rq 1 "On" 0 "Off" ;
VAL_ 395 HudLed18On_B_Rq 1 "On" 0 "Off" ;
VAL_ 395 HudLed17On_B_Rq 1 "On" 0 "Off" ;
VAL_ 395 HudLed16On_B_Rq 1 "On" 0 "Off" ;
VAL_ 395 HudLed15On_B_Rq 1 "On" 0 "Off" ;
VAL_ 395 HudLed14On_B_Rq 1 "On" 0 "Off" ;
VAL_ 395 HudLed13On_B_Rq 1 "On" 0 "Off" ;
VAL_ 395 HudLed12On_B_Rq 1 "On" 0 "Off" ;
VAL_ 395 HudLed11On_B_Rq 1 "On" 0 "Off" ;
VAL_ 395 HudLed10On_B_Rq 1 "On" 0 "Off" ;
VAL_ 76 RstrnPsngrOn_D_Stat 15 "Faulty" 14 "NotUsed_11" 13 "NotUsed_10" 12 "ConfiguredOff" 11 "NotUsed_9" 10 "On" 9 "NotUsed_8" 8 "NotUsed_7" 7 "NotUsed_6" 6 "NotUsed_5" 5 "Off" 4 "NotUsed_4" 3 "NotUsed_3" 2 "NotUsed_2" 1 "NotUsed_1" 0 "NoAction" ;
VAL_ 76 PsngrFmidDetct_D_Actl 3 "Unknown" 2 "Empty" 1 "Occupied" 0 "Fault" ;
VAL_ 76 FirstRowBuckleMid 3 "Unknown" 2 "Unbelted" 1 "Belted" 0 "Faulty" ;
VAL_ 76 ThirdRowBucklePsngr 3 "Unknown" 2 "Unbelted" 1 "Belted" 0 "Faulty" ;
VAL_ 76 ThirdRowBuckleMid 3 "Unknown" 2 "Unbelted" 1 "Belted" 0 "Faulty" ;
VAL_ 76 ThirdRowBuckleDriver 3 "Unknown" 2 "Unbelted" 1 "Belted" 0 "Faulty" ;
VAL_ 76 SecondRowBucklePsngr 3 "Unknown" 2 "Unbelted" 1 "Belted" 0 "Faulty" ;
VAL_ 76 SecondRowBuckleMid 3 "Unknown" 2 "Unbelted" 1 "Belted" 0 "Faulty" ;
VAL_ 76 SecondRowBuckleDriver 3 "Unknown" 2 "Unbelted" 1 "Belted" 0 "Faulty" ;
VAL_ 76 FirstRowBuckleDriver 3 "Unknown" 2 "Unbelted" 1 "Belted" 0 "Faulty" ;
VAL_ 76 RILReq 3 "Not_Used" 2 "Plant_Mode" 1 "On" 0 "Off" ;
VAL_ 76 FirstRowBucklePsngr 3 "Unknown" 2 "Unbelted" 1 "Belted" 0 "Faulty" ;
VAL_ 76 RstrnImpactEvntStatus 7 "Invalid" 6 "Not_Used_4" 5 "Threshold_2_Exceeded" 4 "Not_Used_3" 3 "Threshold_1_Exceeded" 2 "Not_Used_2" 1 "Not_Used_1" 0 "Normal" ;
VAL_ 76 PsngrFrntDetct_D_Actl 3 "Unknown" 2 "Empty" 0 "Faulty" 1 "Occupied" ;
VAL_ 76 PassRstrnInd_Req 3 "ABOnNotIllum_OffNotIllum" 2 "AirbagOnNot_Illum_OffIllum" 1 "AirbagOn_Illum_OffNotIllum" 0 "AirbagOn_Illum_Off_Illum" ;
VAL_ 76 EDRTriggerEvntSync 1 "Threshold_Exceeded" 0 "Normal" ;
VAL_ 1069 IsaOffst_D_Stat 15 "Faulty" 14 "Null" 13 "Thirteen" 12 "Twelve" 11 "Eleven" 10 "Ten" 9 "Nine" 8 "Eight" 7 "Seven" 6 "Six" 5 "Five" 4 "Four" 3 "Three" 2 "Two" 1 "One" 0 "Zero" ;
VAL_ 1069 EngOilMaint_B_Stat 1 "On" 0 "Off" ;
VAL_ 1069 ReFuelSysStat_D_Dsply 7 "NotUsed3" 6 "NotUsed2" 5 "NotUsed1" 4 "Refuel_Err" 3 "Close_Fuel_Door" 2 "Refuel_Ready" 1 "Wait_To_Fuel" 0 "Null" ;
VAL_ 1069 SlMde_D_Stat 3 "IsaNotConfigured" 2 "Manual_Mode" 1 "Auto_Mode" 0 "Null" ;
VAL_ 1069 SlMde_D_RqDsply 3 "NotUsed" 2 "ManualSpeed_LimiterSymbol" 1 "AutoSpeed_LimiterSymbol" 0 "NoSpeed_LimiterSymbol" ;
VAL_ 1069 ULoSrcOnPlg_B_Cmd 1 "Activate" 0 "Deactivate" ;
VAL_ 1069 EngAirIn_Te_Actl 1023 "Fault" 1022 "Unknown" ;
VAL_ 1069 GrllShtrPos_B_Falt 1 "Fault" 0 "No_Fault" ;
VAL_ 1069 EngMsgTxt_D_Rq 3 "Undefined_2" 2 "Undefined_1" 1 "Power_Reduced_to_LowerTemp" 0 "No_Message" ;
VAL_ 1069 TracKeyMdeEnbl_B_Stat 1 "On" 0 "Off" ;
VAL_ 1069 ObdWarmUp_B_Complt 1 "Yes" 0 "No" ;
VAL_ 1069 GrllShtrPos_D_Cmd 15 "Fully_Open" 14 "Position14" 13 "Position13" 12 "Position12" 11 "Position11" 10 "Position10" 9 "Position9" 8 "Position8" 7 "Position7" 6 "Position6" 5 "Position5" 4 "Position4" 3 "Position3" 2 "Position2" 1 "Position1" 0 "Fully_Closed" ;
VAL_ 1057 FohEng_D_Rq 3 "AutoEnable_ParkEnable" 2 "AutoDisable_ParkEnable" 1 "AutoEnable_ParkDisable" 0 "Disable_Stop" ;
VAL_ 1057 EngIdlShutDwnTxt_D_Rq 3 "NotUsed" 2 "EngineShutdownOnPrevDrive" 1 "FeatureDisabledDueToFault" 0 "NoMessage" ;
VAL_ 1057 EngIdlShutDown_D_Stat 3 "Not_used" 2 "Engine_Shutdown" 1 "Initiated_Countdown" 0 "Normal_Operation" ;
VAL_ 1057 FUEL_ALCOHOL_PERCNT 255 "Invalid" ;
VAL_ 1057 TrnTotTq_Rt_Est 65535 "Fault" 65534 "Unknown" ;
VAL_ 1057 TrnTotLss_Tq_Est 255 "Fault" 254 "Unknown" ;
VAL_ 1057 ECMMILRequest 3 "Not_Used" 2 "Flash" 1 "On" 0 "Off" ;
VAL_ 1057 AirCondFluidHi_P_Actl 255 "Fault" 254 "Unknown" ;
VAL_ 1057 OilPressureWarning 1 "Low_Pressure_Lamp_On" 0 "Normal_Pressure_Lamp_Off" ;
VAL_ 1057 VehVLimStat_D_Actl 7 "Undefined_3" 6 "Undefined_2" 5 "Undefined_1" 4 "ASL_Fault_Condition" 3 "Active_and_Limiting" 2 "Active_but_Not_Limiting" 1 "Standby" 0 "Off" ;
VAL_ 1057 VehVLimActv_B_Actl 1 "Active" 0 "Inactive" ;
VAL_ 1057 CoolantFanStepAct 31 "Unused7" 30 "Unused6" 29 "Unused5" 28 "Unused4" 27 "Unused3" 26 "Unused2" 25 "Unused1" 23 "Step23" 22 "Step22" 21 "Step21" 20 "Step20" 19 "Step19" 18 "Step18" 17 "Step17" 16 "Step16" 15 "Step15" 14 "Step14" 13 "Step13" 12 "Step12" 11 "Step11" 10 "Step10" 9 "Step9" 8 "Step8" 7 "Step7" 6 "Step6" 5 "Step5" 4 "Step4" 3 "Step3" 2 "Step2" 1 "Step1" 24 "Max_Fan_Speed_Req" 0 "Fan_Cmd_Off" ;
VAL_ 516 EngAoutNActl_D_QF 3 "OK" 2 "Not_Within_Specifications" 1 "No_Data_Exists" 0 "Faulty" ;
VAL_ 516 ApedPos_PcRate_ActlArb 255 "Fault" 254 "Unknown" ;
VAL_ 516 ApedPosPcActl_D_Qf 3 "OK" 2 "Not_Within_Specifications" 1 "No_Data_Exists" 0 "Faulty" ;
VAL_ 516 EngAout3_N_Actl 65535 "Invalid" ;
VAL_ 514 VehVTrlrAid_B_Avail 1 "Yes" 0 "No" ;
VAL_ 514 StrtrMtrCtlMsgTxt_D_Rq 7 "Start_In_Gear_Allowed" 6 "Pending_Start_Cancelled" 5 "Start_Pending_Please_Wait" 4 "Cranking_Limit_Exceeded" 3 "Press_Brk_and_Shift_to_P_N" 2 "Press_Clutch_and_Brake" 1 "Press_Clutch_To_Start" 0 "No_Display" ;
VAL_ 514 GearRvrse_D_Actl 7 "Fault" 6 "NotUsed_3" 5 "NotUsed_2" 4 "NotUsed_1" 3 "Active_confirmed" 2 "Active_not_confirmed" 1 "Inactive_confirmed" 0 "Inactive_not_confirmed" ;
VAL_ 514 VehVActlEng_D_Qf 3 "OK" 2 "Not_Within_Specifications" 1 "No_Data_Exists" 0 "Faulty" ;
VAL_ 514 StrtrMtrDlyStrt_B_Stat 1 "Yes" 0 "No" ;
VAL_ 514 StrtrMtrCtlMsgTxt_D2_Rq 3 "NoRequestPcmStartingMsgCtl" 2 "ShiftToNeutralToStart" 1 "ShiftToParkToStart" 0 "NoRequestBcmStartingMsgCtl" ;
VAL_ 381 EngOilSrvcMsgTxt_D_Rq 7 "NotUsed3" 6 "OilMinderNotConfigured" 5 "ResetFailed" 4 "ResetComplete" 3 "ResetInProgress" 2 "ChangeOilNow" 1 "ChangeOilSoon" 0 "NoText" ;
VAL_ 381 RunDryPrevent_B_Stat 1 "True" 0 "False" ;
VAL_ 381 WaterInFuel 1 "On" 0 "Off" ;
VAL_ 381 GlowIndication 1 "On" 0 "Off" ;
VAL_ 380 FuelMaintMde_D_Rq 3 "Feature_Not_Present" 2 "Fuel_Maint_Req_Now" 1 "Fuel_Maint_Req_Soon" 0 "NoRequest" ;
VAL_ 380 GrdAsstAllw_D_DsplyPt 3 "NotUsed" 2 "On" 1 "Off" 0 "NoModeSelected" ;
VAL_ 380 EngOilLvlWarn_D_Rq1 7 "Undefined_3" 6 "Undefined_2" 5 "Engine_Oil_Monitor_Fault" 3 "Engine_Oil_High" 2 "Engine_Oil_Critical_Low" 1 "Engine_Oil_Low" 0 "No_Message" 4 "Engine_Oil_Critical_High" ;
VAL_ 380 EngExhBrkOnLamp_B_Rq 1 "On" 0 "Off" ;
VAL_ 380 EngExhBrkAutoLamp_B_Rq 1 "On" 0 "Off" ;
VAL_ 380 EngExhBrkMde_D_Actl 6 "ExhBrkDisable_NoError" 5 "ExhBrkActive_AUTO" 4 "ExhBrkActive_ON" 3 "ExhBrkRequest_AUTO" 2 "ExhBrkRequest_ON" 1 "ExhBrkNoRequest_OFF" 0 "ExhBrkUnavailable_Error" ;
VAL_ 380 WhlRearDual_D_Stat 3 "NotUsed" 2 "Dual" 1 "Single" 0 "NoDataExists" ;
VAL_ 377 TrnManShif_D_IndDrv 7 "Undefined_3" 6 "Undefined_2" 5 "Shift_to_Neutral" 4 "Downshift_Recommendation" 3 "Upshift_Warning" 2 "Upshift_Performance" 1 "Upshift_Fuel_Economy" 0 "No_Indication" ;
VAL_ 377 HvacAirFullOut_B_Rq 1 "Yes" 0 "No" ;
VAL_ 377 EngFuelCutFull_B_Inhbt 1 "Inhibit_DFSO" 0 "Normal" ;
VAL_ 377 EngDecelFuelCut_B_Allw 1 "Yes" 0 "No" ;
VAL_ 377 TrnManShifGear_D_IndDrv 7 "Indicate_Reverse_Gear" 6 "Indicate_Gear6" 5 "Indicate_Gear5" 4 "Indicate_Gear4" 3 "Indicate_Gear3" 2 "Indicate_Gear2" 1 "Indicate_Gear1" 0 "No_Indication" ;
VAL_ 377 FuelFillInlet_B_Dsply 1 "Yes" 0 "No" ;
VAL_ 377 EngSrvcRqd_B_Rq 1 "Engine_Service_Required" 0 "No_engine_service_required" ;
VAL_ 377 OdoCount 255 "Invalid" ;
VAL_ 377 TrnKickDown_B_RqDrv 1 "Yes" 0 "No" ;
VAL_ 377 FuelFilterLamp_B_Dsply 1 "On" 0 "Off" ;
VAL_ 377 AirCondRec_B_Rq 1 "Yes" 0 "No" ;
VAL_ 377 AirCondClutch_B_Stats 1 "Yes" 0 "No" ;
VAL_ 377 EngAoutTqActl_D_Qf 3 "OK" 2 "Not_Within_Specifications" 1 "No_Data_Exists" 0 "Faulty" ;
VAL_ 376 GasPrtc_D_RqDsply 7 "NotUsed_5" 6 "NotUsed_4" 5 "NotUsed_3" 4 "NotUsed_2" 3 "NotUsed_1" 2 "GpfOverLimit" 1 "GpfAtLimit" 0 "NormalOperation" ;
VAL_ 376 LnchCtlSys_D_Stat 7 "NotUsed3" 6 "NotUsed2" 5 "NotUsed1" 4 "On_LC_Unavailable_TC_On" 3 "On_LC_Unavailable" 2 "On_LC_Available" 1 "On_LC_Active" 0 "LC_OFF" ;
VAL_ 376 DynoMde_B_Cmd 1 "DynomometerMode" 0 "NormalOperation" ;
VAL_ 376 AslIconDsply_D_Rq 3 "On_Passive_Overridden" 2 "On_Active" 1 "On_Passive" 0 "Off" ;
VAL_ 376 AslChime_B_Rq 1 "Yes" 0 "No" ;
VAL_ 376 PtcHtr_D_Cmd 3 "TurnOn" 2 "AutoMode" 1 "TurnOff" 0 "NoDecision_Initializing" ;
VAL_ 376 HvacHtrCore2_Te_Actl 1023 "Faulty" ;
VAL_ 376 EcssLamp_D_RqDsply 3 "Not_Used" 2 "Flash" 1 "On" 0 "Off" ;
VAL_ 376 AirAmbTe_D_Qf 3 "OK" 2 "Not_Within_Specifications" 1 "No_Data_Exists" 0 "Faulty" ;
VAL_ 376 AirAmb_P_Actl 63 "Fault" 62 "NoDataExists" ;
VAL_ 373 DieslPrtc2_D_RqDsply 15 "NotUsed4" 14 "NotUsed3" 13 "NotUsed2" 12 "NotUsed1" 11 "OCR_ExhFilterClean_Stopped" 10 "OCR_ExhFilterCleaned" 9 "RgnOff_AtLimit" 8 "RgnOff_Overloaded" 7 "RgnOff_Loaded" 6 "Exhaust_Filter_Full" 5 "DPF_Overlimit" 4 "DPF_AtLimit" 3 "ExhFilter_Drive_Completed" 2 "Cleaning_Exhaust_Filter" 1 "DPF_Overloaded" 0 "DPF_Normal_Operation" ;
VAL_ 373 DieslPrtc_D_RqDsply 7 "Unused_2" 6 "Unused_1" 5 "DPF_SOOT_Level3_Blocked" 4 "DPFSootLvl2_SevereOverload" 3 "DPFRegen_ExhFilterComplete" 2 "DPFRegen_CleanExhFilter" 1 "DPF_Soot_Level1_Overloaded" 0 "DPF_OK_Normal_Operation" ;
VAL_ 373 DieslPrtcRgen_D_Actl 3 "Undefined" 2 "Regen_Level_2" 1 "Regen_Level_1" 0 "No_regen" ;
VAL_ 373 DieslPrtcRgen_D_Rq 7 "Unused_2" 6 "Unused_1" 5 "Full_Regen_2" 4 "Full_Regen_1" 3 "HeatUp_3" 2 "HeatUp_2" 1 "HeatUp_1" 0 "Normal_Mode_NoRegen" ;
VAL_ 373 EngFuelCutFull_B_Allw 1 "Yes" 0 "No" ;
VAL_ 373 EngTurboMde_D_Actl 3 "Fault" 2 "One_Turbo_Active" 1 "Two_Turbos_Active" 0 "Initializing" ;
VAL_ 373 EngTeColdPrtct_D_Stats 3 "Engine_Warm_RdcPwr" 2 "OK_to_Drive" 1 "Engine_Warm_PlsWait" 0 "Normal_Operation" ;
VAL_ 373 EngExhOvrTe_B_RqDsply 1 "Active" 0 "Inactive" ;
VAL_ 373 EngPtoMde_D_Rq 7 "Undefined" 6 "Split_Shaft_Stationary" 5 "Not_Used_2" 4 "PTO_Mobile" 3 "Not_Used_1" 2 "PTO_Stationary" 1 "BCP" 0 "Off" ;
VAL_ 355 AccFllwMdeActv_B_Actl 1 "Active" 0 "Inactive" ;
VAL_ 355 AutoRgenTxt_B_RqDsply 1 "AutExhFilterCleanOFF" 0 "AutExhFilterCleanON" ;
VAL_ 355 EngPtoMde_D_Actl 7 "Undefined" 6 "Split_Shaft_Stationary" 5 "Not_Used_2" 4 "PTO_Mobile" 3 "Not_Used_1" 2 "PTO_Stationary" 1 "BCP" 0 "Off" ;
VAL_ 355 ManRgenVeh_V_MinAllw 127 "Fault" ;
VAL_ 355 ManRgenTxt_D_RqDsply 7 "NotUsed3" 6 "NotUsed2" 5 "NotUsed1" 4 "Cleaning_Aborted_Stopped" 3 "Cleaning_Completed" 2 "Cleaning_In_Progress" 1 "Cleaning_Allowed" 0 "Cleaning_Not_Allowed" ;
VAL_ 355 ManRgenSoot_Pc_RqDsply 127 "Fault" ;
VAL_ 355 ManRgenInhbt_T_RqDsply 65535 "Fault" ;
VAL_ 355 ManRgenInhbt_Pc_Soot 127 "Fault" ;
VAL_ 355 DieslMsgTxt_D_Rq 3 "NotUsed2" 2 "NotUsed1" 1 "ReducedEnginePower" 0 "NoMessage" ;
VAL_ 355 ManRgenInhbt_L_RqDsply 65535 "Fault" ;
VAL_ 342 HtrLoop_B_Stat 1 "Fault" 0 "No_Fault" ;
VAL_ 342 TqmTerrMdeChng_D_Rdy 7 "Fault" 6 "Undefined_2" 5 "Undefined_1" 4 "ModeUnavailDrInputRqd" 3 "SpOpModes_NotSupported" 2 "ModeUnavailDynamicCond" 1 "Module_In_Initialization" 0 "Mode_Change_Available" ;
VAL_ 342 TqmTerrMde_D_Actl 7 "Fail_Safe_Default" 6 "Dynamic_Mode" 5 "Rock_Crawl_Mode" 4 "Mud_Ruts_Mode" 3 "Sand_Mode" 2 "Undefined" 1 "Low_Mu_Mode" 0 "Special_Operating_Mode_Off" ;
VAL_ 342 EngOvrhtMitgActv_D_Ind 3 "Undefined" 2 "Mode2" 1 "Mode1" 0 "Normal_Mode" ;
VAL_ 342 EngClntTe_D_Qf 3 "OK" 2 "Not_Within_Specifications" 1 "No_Data_Exists" 0 "Faulty" ;
VAL_ 342 EngAcsyArcPmp_Tq_Actl 255 "Fault" 254 "Unknown" ;
VAL_ 342 EngOilLvlDsply_D_Rq 15 "EngOil_LevelSys_CheckFault" 14 "Reserved_2" 13 "Reserved_1" 12 "Conditions_Unsuitable" 11 "Dipstick_Below_Minimum" 10 "Dipstick_Above_Maximum" 9 "Dipstick_Minimum" 8 "Dipstick_12_5_MinMaxRange" 7 "Dipstick_25_MinMaxRange" 6 "Dipstick_37_5_MinMaxRange" 5 "Dipstick_50_MinMaxRange" 4 "Dipstick_62_5_MinMaxRange" 3 "Dipstick_75_MinMaxRange" 2 "Dipstick_87_5_MinMaxRange" 1 "Dipstick_Maximum_Displayed" 0 "No_Message" ;
VAL_ 342 EngOil_Te_Actl 255 "Fault" 254 "Unknown" ;
VAL_ 530 StationTypeSel_D_Rq 0 "Inactive" 1 "PI_Code" 2 "SCIDI_SID_ECC" 3 "NotUsed_1" ;
VAL_ 897 VehElAvgTrip2_Eff_Dsply 127 "Faulty" 126 "NoDataExists" ;
VAL_ 897 Trip2SumDrvE_Pc_Dsply 1023 "Faulty" 1022 "NoDataExists" ;
VAL_ 897 Trip2ExtFctrE_Pc_Dsply 1023 "Faulty" 1022 "NoDataExists" ;
VAL_ 897 Trip2ClimE_Pc_Dsply 1023 "Faulty" 1022 "NoDataExists" ;
VAL_ 897 Trip2BattULoE_Pc_Dsply 1023 "Faulty" 1022 "NoDataExists" ;
VAL_ 1102 SelDrvMdePos12_D_Stat 31 "Faulty" 30 "SelDrvMde31" 29 "SelDrvMde30" 28 "SelDrvMde29" 27 "SelDrvMde28" 26 "SelDrvMde27" 25 "SelDrvMde26" 24 "SelDrvMde25" 23 "SelDrvMde24" 22 "SelDrvMde23" 21 "SelDrvMde22" 20 "SelDrvMde21" 19 "SelDrvMde20" 18 "SelDrvMde19" 17 "SelDrvMde18" 16 "SelDrvMde17" 15 "SelDrvMde16" 14 "SelDrvMde15" 13 "SelDrvMde14" 12 "SelDrvMde13" 11 "SelDrvMde12" 10 "SelDrvMde11" 9 "SelDrvMde10" 8 "SelDrvMde09" 7 "SelDrvMde08" 6 "SelDrvMde07" 5 "SelDrvMde06" 4 "SelDrvMde05" 3 "SelDrvMde04" 2 "SelDrvMde03" 1 "SelDrvMde02" 0 "SelDrvMde01" ;
VAL_ 1102 SelDrvMdePos11_D_Stat 31 "Faulty" 30 "SelDrvMde31" 29 "SelDrvMde30" 28 "SelDrvMde29" 27 "SelDrvMde28" 26 "SelDrvMde27" 25 "SelDrvMde26" 24 "SelDrvMde25" 23 "SelDrvMde24" 22 "SelDrvMde23" 21 "SelDrvMde22" 20 "SelDrvMde21" 19 "SelDrvMde20" 18 "SelDrvMde19" 17 "SelDrvMde18" 16 "SelDrvMde17" 15 "SelDrvMde16" 14 "SelDrvMde15" 13 "SelDrvMde14" 12 "SelDrvMde13" 11 "SelDrvMde12" 10 "SelDrvMde11" 9 "SelDrvMde10" 8 "SelDrvMde09" 7 "SelDrvMde08" 6 "SelDrvMde07" 5 "SelDrvMde06" 4 "SelDrvMde05" 3 "SelDrvMde04" 2 "SelDrvMde03" 1 "SelDrvMde02" 0 "SelDrvMde01" ;
VAL_ 1102 SelDrvMdePos10_D_Stat 31 "Faulty" 30 "SelDrvMde31" 29 "SelDrvMde30" 28 "SelDrvMde29" 27 "SelDrvMde28" 26 "SelDrvMde27" 25 "SelDrvMde26" 24 "SelDrvMde25" 23 "SelDrvMde24" 22 "SelDrvMde23" 21 "SelDrvMde22" 20 "SelDrvMde21" 19 "SelDrvMde20" 18 "SelDrvMde19" 17 "SelDrvMde18" 16 "SelDrvMde17" 15 "SelDrvMde16" 14 "SelDrvMde15" 13 "SelDrvMde14" 12 "SelDrvMde13" 11 "SelDrvMde12" 10 "SelDrvMde11" 9 "SelDrvMde10" 8 "SelDrvMde09" 7 "SelDrvMde08" 6 "SelDrvMde07" 5 "SelDrvMde06" 4 "SelDrvMde05" 3 "SelDrvMde04" 2 "SelDrvMde03" 1 "SelDrvMde02" 0 "SelDrvMde01" ;
VAL_ 1102 SelDrvMdePos09_D_Stat 31 "Faulty" 30 "SelDrvMde31" 29 "SelDrvMde30" 28 "SelDrvMde29" 27 "SelDrvMde28" 26 "SelDrvMde27" 25 "SelDrvMde26" 24 "SelDrvMde25" 23 "SelDrvMde24" 22 "SelDrvMde23" 21 "SelDrvMde22" 20 "SelDrvMde21" 19 "SelDrvMde20" 18 "SelDrvMde19" 17 "SelDrvMde18" 16 "SelDrvMde17" 15 "SelDrvMde16" 14 "SelDrvMde15" 13 "SelDrvMde14" 12 "SelDrvMde13" 11 "SelDrvMde12" 10 "SelDrvMde11" 9 "SelDrvMde10" 8 "SelDrvMde09" 7 "SelDrvMde08" 6 "SelDrvMde07" 5 "SelDrvMde06" 4 "SelDrvMde05" 3 "SelDrvMde04" 2 "SelDrvMde03" 1 "SelDrvMde02" 0 "SelDrvMde01" ;
VAL_ 1102 SelDrvMdePos08_D_Stat 31 "Faulty" 30 "SelDrvMde31" 29 "SelDrvMde30" 28 "SelDrvMde29" 27 "SelDrvMde28" 26 "SelDrvMde27" 25 "SelDrvMde26" 24 "SelDrvMde25" 23 "SelDrvMde24" 22 "SelDrvMde23" 21 "SelDrvMde22" 20 "SelDrvMde21" 19 "SelDrvMde20" 18 "SelDrvMde19" 17 "SelDrvMde18" 16 "SelDrvMde17" 15 "SelDrvMde16" 14 "SelDrvMde15" 13 "SelDrvMde14" 12 "SelDrvMde13" 11 "SelDrvMde12" 10 "SelDrvMde11" 9 "SelDrvMde10" 8 "SelDrvMde09" 7 "SelDrvMde08" 6 "SelDrvMde07" 5 "SelDrvMde06" 4 "SelDrvMde05" 3 "SelDrvMde04" 2 "SelDrvMde03" 1 "SelDrvMde02" 0 "SelDrvMde01" ;
VAL_ 1102 SelDrvMdePos07_D_Stat 31 "Faulty" 30 "SelDrvMde31" 29 "SelDrvMde30" 28 "SelDrvMde29" 27 "SelDrvMde28" 26 "SelDrvMde27" 25 "SelDrvMde26" 24 "SelDrvMde25" 23 "SelDrvMde24" 22 "SelDrvMde23" 21 "SelDrvMde22" 20 "SelDrvMde21" 19 "SelDrvMde20" 18 "SelDrvMde19" 17 "SelDrvMde18" 16 "SelDrvMde17" 15 "SelDrvMde16" 14 "SelDrvMde15" 13 "SelDrvMde14" 12 "SelDrvMde13" 11 "SelDrvMde12" 10 "SelDrvMde11" 9 "SelDrvMde10" 8 "SelDrvMde09" 7 "SelDrvMde08" 6 "SelDrvMde07" 5 "SelDrvMde06" 4 "SelDrvMde05" 3 "SelDrvMde04" 2 "SelDrvMde03" 1 "SelDrvMde02" 0 "SelDrvMde01" ;
VAL_ 1102 SelDrvMdePos06_D_Stat 31 "Faulty" 30 "SelDrvMde31" 29 "SelDrvMde30" 28 "SelDrvMde29" 27 "SelDrvMde28" 26 "SelDrvMde27" 25 "SelDrvMde26" 24 "SelDrvMde25" 23 "SelDrvMde24" 22 "SelDrvMde23" 21 "SelDrvMde22" 20 "SelDrvMde21" 19 "SelDrvMde20" 18 "SelDrvMde19" 17 "SelDrvMde18" 16 "SelDrvMde17" 15 "SelDrvMde16" 14 "SelDrvMde15" 13 "SelDrvMde14" 12 "SelDrvMde13" 11 "SelDrvMde12" 10 "SelDrvMde11" 9 "SelDrvMde10" 8 "SelDrvMde09" 7 "SelDrvMde08" 6 "SelDrvMde07" 5 "SelDrvMde06" 4 "SelDrvMde05" 3 "SelDrvMde04" 2 "SelDrvMde03" 1 "SelDrvMde02" 0 "SelDrvMde01" ;
VAL_ 1102 SelDrvMdePos05_D_Stat 31 "Faulty" 30 "SelDrvMde31" 29 "SelDrvMde30" 28 "SelDrvMde29" 27 "SelDrvMde28" 26 "SelDrvMde27" 25 "SelDrvMde26" 24 "SelDrvMde25" 23 "SelDrvMde24" 22 "SelDrvMde23" 21 "SelDrvMde22" 20 "SelDrvMde21" 19 "SelDrvMde20" 18 "SelDrvMde19" 17 "SelDrvMde18" 16 "SelDrvMde17" 15 "SelDrvMde16" 14 "SelDrvMde15" 13 "SelDrvMde14" 12 "SelDrvMde13" 11 "SelDrvMde12" 10 "SelDrvMde11" 9 "SelDrvMde10" 8 "SelDrvMde09" 7 "SelDrvMde08" 6 "SelDrvMde07" 5 "SelDrvMde06" 4 "SelDrvMde05" 3 "SelDrvMde04" 2 "SelDrvMde03" 1 "SelDrvMde02" 0 "SelDrvMde01" ;
VAL_ 1102 SelDrvMdePos04_D_Stat 31 "Faulty" 30 "SelDrvMde31" 29 "SelDrvMde30" 28 "SelDrvMde29" 27 "SelDrvMde28" 26 "SelDrvMde27" 25 "SelDrvMde26" 24 "SelDrvMde25" 23 "SelDrvMde24" 22 "SelDrvMde23" 21 "SelDrvMde22" 20 "SelDrvMde21" 19 "SelDrvMde20" 18 "SelDrvMde19" 17 "SelDrvMde18" 16 "SelDrvMde17" 15 "SelDrvMde16" 14 "SelDrvMde15" 13 "SelDrvMde14" 12 "SelDrvMde13" 11 "SelDrvMde12" 10 "SelDrvMde11" 9 "SelDrvMde10" 8 "SelDrvMde09" 7 "SelDrvMde08" 6 "SelDrvMde07" 5 "SelDrvMde06" 4 "SelDrvMde05" 3 "SelDrvMde04" 2 "SelDrvMde03" 1 "SelDrvMde02" 0 "SelDrvMde01" ;
VAL_ 1102 SelDrvMdePos03_D_Stat 31 "Faulty" 30 "SelDrvMde31" 29 "SelDrvMde30" 28 "SelDrvMde29" 27 "SelDrvMde28" 26 "SelDrvMde27" 25 "SelDrvMde26" 24 "SelDrvMde25" 23 "SelDrvMde24" 22 "SelDrvMde23" 21 "SelDrvMde22" 20 "SelDrvMde21" 19 "SelDrvMde20" 18 "SelDrvMde19" 17 "SelDrvMde18" 16 "SelDrvMde17" 15 "SelDrvMde16" 14 "SelDrvMde15" 13 "SelDrvMde14" 12 "SelDrvMde13" 11 "SelDrvMde12" 10 "SelDrvMde11" 9 "SelDrvMde10" 8 "SelDrvMde09" 7 "SelDrvMde08" 6 "SelDrvMde07" 5 "SelDrvMde06" 4 "SelDrvMde05" 3 "SelDrvMde04" 2 "SelDrvMde03" 1 "SelDrvMde02" 0 "SelDrvMde01" ;
VAL_ 1102 SelDrvMdePos02_D_Stat 31 "Faulty" 30 "SelDrvMde31" 29 "SelDrvMde30" 28 "SelDrvMde29" 27 "SelDrvMde28" 26 "SelDrvMde27" 25 "SelDrvMde26" 24 "SelDrvMde25" 23 "SelDrvMde24" 22 "SelDrvMde23" 21 "SelDrvMde22" 20 "SelDrvMde21" 19 "SelDrvMde20" 18 "SelDrvMde19" 17 "SelDrvMde18" 16 "SelDrvMde17" 15 "SelDrvMde16" 14 "SelDrvMde15" 13 "SelDrvMde14" 12 "SelDrvMde13" 11 "SelDrvMde12" 10 "SelDrvMde11" 9 "SelDrvMde10" 8 "SelDrvMde09" 7 "SelDrvMde08" 6 "SelDrvMde07" 5 "SelDrvMde06" 4 "SelDrvMde05" 3 "SelDrvMde04" 2 "SelDrvMde03" 1 "SelDrvMde02" 0 "SelDrvMde01" ;
VAL_ 1102 SelDrvMdePos01_D_Stat 31 "Faulty" 30 "SelDrvMde31" 29 "SelDrvMde30" 28 "SelDrvMde29" 27 "SelDrvMde28" 26 "SelDrvMde27" 25 "SelDrvMde26" 24 "SelDrvMde25" 23 "SelDrvMde24" 22 "SelDrvMde23" 21 "SelDrvMde22" 20 "SelDrvMde21" 19 "SelDrvMde20" 18 "SelDrvMde19" 17 "SelDrvMde18" 16 "SelDrvMde17" 15 "SelDrvMde16" 14 "SelDrvMde15" 13 "SelDrvMde14" 12 "SelDrvMde13" 11 "SelDrvMde12" 10 "SelDrvMde11" 9 "SelDrvMde10" 8 "SelDrvMde09" 7 "SelDrvMde08" 6 "SelDrvMde07" 5 "SelDrvMde06" 4 "SelDrvMde05" 3 "SelDrvMde04" 2 "SelDrvMde03" 1 "SelDrvMde02" 0 "SelDrvMde01" ;
VAL_ 551 Rba_D_Rq 3 "NotUsed" 2 "On" 1 "Off" 0 "Null" ;
VAL_ 551 PrcondEdit_D_RqMnu 7 "NotUsed_3" 6 "NotUsed_2" 5 "NotUsed_1" 4 "High" 3 "Medium" 2 "Low" 1 "Off" 0 "Null" ;
VAL_ 551 ChrgToPcEdit_Pc_RqMnu 127 "Faulty" 126 "NoDataExists" ;
VAL_ 551 EcoIdl_D_Rq 3 "NotUsed" 2 "Enabled" 1 "Disabled" 0 "Null" ;
VAL_ 551 PwRnngBoardT_D_Rq 3 "NotUsed" 2 "Timer2" 1 "Timer1" 0 "Inactive" ;
VAL_ 551 PwRnngBoardSwtch_D_Rq 3 "NotUsed" 2 "DeployUnlocked" 1 "AlwaysActive" 0 "Inactive" ;
VAL_ 551 PwRnngBoardMde_D_Rq 0 "Inactive" 1 "Off" 2 "Out" 3 "Auto" ;
VAL_ 551 OneTEditActv_B_RqMnu 1 "Yes" 0 "No" ;
VAL_ 551 Cntr_Plg_Mode_Cmd 1 "Enable" 0 "Disable" ;
VAL_ 551 BattTracLoThres_D_Rq 7 "NotUsed" 6 "Thres80km_50mi" 5 "Thres50km_31mi" 4 "Thres30km_18mi" 3 "Thres50mi_80km" 2 "Thres30mi_48km" 1 "Thres20mi_32km" 0 "Null" ;
VAL_ 551 EmPrflNo_D_Rq 7 "NotUsed_3" 6 "NotUsed_2" 5 "NotUsed_1" 4 "Pers4" 3 "Pers3" 2 "Pers2" 1 "Pers1" 0 "Null" ;
VAL_ 551 EmPrflButtnAssoc_D_Rq 3 "NotUsed" 2 "ExitButtonAssociation" 1 "EnterButtonAssociation" 0 "Null" ;
VAL_ 551 EmPrflKeyAssoc_D_Rq 7 "NotUsed_3" 6 "DisassociatePhone" 5 "EnterPhoneAssociation" 4 "OverwriteKey" 3 "DisassociateKey" 2 "ExitKeyAssociation" 1 "EnterKeyAssociation" 0 "Null" ;
VAL_ 551 Em_D_Stat 3 "NotSupported" 2 "ProfilesOff" 1 "ProfilesOn" 0 "Null" ;
VAL_ 551 PmCabnLvl_D_Stat 7 "NotUsed_1" 6 "Level_6_Worst" 5 "Level_5" 4 "Level_4" 3 "Level_3" 2 "Level_2" 1 "Level_1_Best" 0 "NotKnown" ;
VAL_ 551 PmCabn_D_Stat 3 "FilteringComplete" 2 "FilteringOn" 1 "FilteringOff" 0 "NotKnown" ;
VAL_ 551 ChrgCrdLckEnbl_B_Stat 1 "Enable" 0 "Disable" ;
VAL_ 551 ChrgOvrdExitScrn_D_Rq 3 "NotUsed_1" 2 "Request_override" 1 "Do_not_request_override" 0 "Inactive" ;
VAL_ 551 Btt_L_Actl2 127 "Faulty" 126 "NoDataExists" ;
VAL_ 673 ICI_Coding_BtnID_D 15 "Idle" 5 "Stuck" 4 "LongEvent" 3 "ShortElapsed" 2 "ShortEvent" 1 "Active" 0 "Inactive" ;
VAL_ 673 ICI_Coding_BtnID_C 15 "Idle" 5 "Stuck" 4 "LongEvent" 3 "ShortElapsed" 2 "ShortEvent" 1 "Active" 0 "Inactive" ;
VAL_ 673 ICI_Coding_BtnID_B 15 "Idle" 5 "Stuck" 4 "LongEvent" 3 "ShortElapsed" 2 "ShortEvent" 1 "Active" 0 "Inactive" ;
VAL_ 673 ICI_Coding_BtnID_A 15 "Idle" 5 "Stuck" 4 "LongEvent" 3 "ShortElapsed" 2 "ShortEvent" 1 "Active" 0 "Inactive" ;
VAL_ 963 Illuminated_Entry_Stat 3 "Invalid" 2 "Unknown" 1 "On" 0 "Off" ;
VAL_ 963 Dr_Courtesy_Light_Stat 3 "Invalid" 2 "Unknown" 1 "On" 0 "Off" ;
VAL_ 963 Courtesy_Delay_Status 3 "Invalid" 2 "Unknown" 1 "On" 0 "Off" ;
VAL_ 963 ImpactEvntFdbck_D_Stat 3 "NotUsed" 2 "EventComplete" 1 "EventInProgress" 0 "Normal" ;
VAL_ 963 WrlssAcsyChrgInhbt_B_Rq 1 "Yes" 0 "No" ;
VAL_ 963 PudLampPsngr_D_Rq 3 "Ramp_Down" 2 "Ramp_Up" 1 "On" 0 "Off" ;
VAL_ 963 HeadLampLoOut_B_Stat 1 "Out" 0 "Null" ;
VAL_ 963 HeadLghtHiFdbck_D_Stat 3 "NotUsed" 2 "Cancel" 1 "Hold" 0 "Allow_Change" ;
VAL_ 963 PrkLightChime_B_Rq 1 "On" 0 "Off" ;
VAL_ 963 TrnNotInPrkChime_B_Rq 1 "On" 0 "Off" ;
VAL_ 963 KeyInIgnWarn_B_Cmd 1 "On" 0 "Off" ;
VAL_ 963 HomeSafeLtChime_B_Rq 1 "On" 0 "Off" ;
VAL_ 963 StopLghtOn_B_Stat 1 "On" 0 "Off" ;
VAL_ 963 RvrseLghtOn_B_Stat 1 "On" 0 "Off" ;
VAL_ 963 PrkLght_D_Stat 3 "Park_Both" 2 "Park_Right" 1 "Park_Left" 0 "Off" ;
VAL_ 963 HeadLghtSwtch_D_Stat 3 "Autolamp" 2 "Headlamp" 1 "Parklamp" 0 "Off" ;
VAL_ 963 HeadLampLoFrOn_B_Stat 1 "Low" 0 "Not_Low" ;
VAL_ 963 HeadLampLoFlOn_B_Stat 1 "Low" 0 "Not_Low" ;
VAL_ 963 HeadLampLoActv_B_Stat 1 "On" 0 "Off" ;
VAL_ 963 Headlamp_On_Wrning_Cmd 1 "On" 0 "Off" ;
VAL_ 963 HeadLghtHiOn_B_Stat 1 "On" 0 "Off" ;
VAL_ 963 Park_Brake_Chime_Rqst 1 "On" 0 "Off" ;
VAL_ 963 BrkWarnInd_B_Rq 1 "On" 0 "Off" ;
VAL_ 963 Brk_Fluid_Lvl_Low 3 "Invalid" 2 "Unknown" 1 "Low" 0 "OK" ;
VAL_ 963 ReducedGuard_D_Stat 3 "NotUsed" 2 "Alarm_On" 1 "Alarm_Off_Previously_On" 0 "Alarm_Off" ;
VAL_ 963 PudLampDrv_D_Rq 3 "Ramp_Down" 2 "Ramp_Up" 1 "On" 0 "Off" ;
VAL_ 963 Courtesy_BSave_Stat 3 "Invalid" 2 "Unknown" 1 "No_Effect" 0 "Off" ;
VAL_ 963 DayRnngLampOn_B_Stat 1 "On" 0 "Off" ;
VAL_ 963 PerimeterAlarmChimeRq 1 "On" 0 "Off" ;
VAL_ 963 Perimeter_Alarm_Status 3 "Activated" 2 "Armed" 1 "Prearmed" 0 "Disarmed" ;
VAL_ 963 WndwGlbl_D_Cmd 7 "NotUsed3" 6 "NotUsed2" 5 "NotUsed1" 4 "GLEARN" 3 "GCLOSE" 2 "GOPEN" 1 "GSTOP" 0 "Null" ;
VAL_ 963 DrTgateLck_D_Stat 3 "NotUsed" 2 "Unlock" 1 "Lock" 0 "Null" ;
VAL_ 963 PudLamp_D_Rq 3 "RAMP_DOWN" 2 "RAMP_UP" 1 "ON" 0 "OFF" ;
VAL_ 949 Tire_Press_RR_ORR_Data 65535 "Not_Supported" 65534 "Invalid" 65533 "Unknown" ;
VAL_ 949 Tire_Press_LR_OLR_Data 65535 "Not_Supported" 65534 "Invalid" 65533 "Unknown" ;
VAL_ 949 Tire_Press_LF_Data 65535 "Not_Supported" 65534 "Invalid" 65533 "Unknown" ;
VAL_ 949 Tire_Press_RF_Data 65535 "Not_Supported" 65534 "Invalid" 65533 "Unknown" ;
VAL_ 1076 AutoRgen_D_Rq 3 "NotUsed" 2 "AutExhFilterCleanOFF" 1 "AutExhFilterCleanON" 0 "No_Mode_Selected" ;
VAL_ 1076 W2S_LAMP_OK 1 "Yes" 0 "No" ;
VAL_ 1076 OdoTripRx_B_Actl 1 "Yes" 0 "No" ;
VAL_ 1076 DrvSlipCtlMde_B_RqMyKey 1 "On" 0 "Off" ;
VAL_ 1076 FuelLvlWarn_D_Actl 3 "NotUsed" 2 "VeryLow" 1 "Low" 0 "OK" ;
VAL_ 1076 DieslFuelBio_B_ActlDrv 1 "Biodiesel_User" 0 "Non_Biodiesel_User" ;
VAL_ 1076 FuelSecndActv_B_Actl 1 "Yes" 0 "No" ;
VAL_ 1076 HILL_DESC_SW 1 "On" 0 "Off" ;
VAL_ 1076 FUEL_SENSOR_NUM 1 "Dual_Sensors" 0 "Single_Sensor" ;
VAL_ 1076 TirePReset_B_Rq 1 "Reset" 0 "Null" ;
VAL_ 552 DSP_VoiceFBVolume_Up 1 "Update" 0 "NoUpdate" ;
VAL_ 552 DSP_TAVolume_Up 1 "Update" 0 "NoUpdate" ;
VAL_ 552 DSP_Shaker_St 1 "Active" 0 "Inactive" ;
VAL_ 552 DSP_Reg_St 0 "Invalid" 1 "Off" 2 "On" ;
VAL_ 552 DSP_PhoneVolume_Up 1 "Update" 0 "NoUpdate" ;
VAL_ 552 DSP_NavCmdVolume_Up 1 "Update" 0 "NoUpdate" ;
VAL_ 552 DSP_DSPProgram_St 7 "Reserved2" 6 "Reserved1" 5 "Voice" 4 "Rock" 0 "Invalid" 1 "Normal" 2 "Pop" 3 "Classical" ;
VAL_ 552 DSP_DSP_St 0 "Invalid" 1 "All" 2 "Driver" 3 "Passenger" 4 "Pop" 5 "Classical" 6 "Rock" ;
VAL_ 552 Audio_Demo_Status 1 "Active" 0 "Inactive" ;
VAL_ 967 CamZoomActiveState 3 "Not_Used" 2 "Inactive" 1 "Active" 0 "Invalid" ;
VAL_ 967 CamraViewSplit_D_Actl 3 "NotUsed" 2 "Inactive" 1 "Active" 0 "Invalid" ;
VAL_ 967 CamraOvrlTow_D_Actl 3 "Not_Used" 2 "Inactive" 1 "Active" 0 "Invalid" ;
VAL_ 967 CamraZoomMan_D_Actl 7 "Unknown" 6 "Invalid" 5 "Zoom_Level_V" 4 "Zoom_Level_IV" 3 "Zoom_Level_III" 2 "Zoom_Level_II" 1 "Zoom_Level_I" 0 "Off" ;
VAL_ 967 CamraOvrlStat_D_Actl 3 "Not_Used" 2 "Inactive" 1 "Active" 0 "Invalid" ;
VAL_ 967 CamraOvrlDyn_D_Actl 3 "Not_Used" 2 "Inactive" 1 "Active" 0 "Invalid" ;
VAL_ 967 CamPDCGuidStat 3 "Not_Used" 2 "Inactive" 1 "Active" 0 "Invalid" ;
